VERSION ""

NS_ :

BS_:

BU_: Turbocharger OnBoardDataLogger OffBoardDiagnosticTool2 OffBoardDiagnosticTool1 FileServer ParkingBrakeController SeatControl2 FanDriveController SteeringColumnUnit CommunicationUnitRadio CommunicationUnitSatellite CommunicationUnitCellular PropulsionBatteryCharger ChassisController2 ChassisController1 EngineValveControl AuxiliaryHeater2 AuxiliaryHeater1 ClutchUnit RampControl InformationSystem1 SuspensionSystemController2 OilSensor VehicleDynamicStability ExhaustEmissionController TransmissionDisplay2 TransmissionDisplay1 ClimateControl2 WaterPumpController RearAxleSteeringController LightingOperatorControl SeatController1 IgnitionController2 IgnitionController1 TirePressureController CabController2 CabController1 PneumaticSystemController SuspensionSystemController1 HydraulicPumpController EnduranceBrakingSystem RetarderExhaustEngine2 OnBoardDiagnosticUnit HeadwayController RetarderExhaustEngine1 CabDisplay1 ManagementComputer VirtualTerminal OffVehicleGateway PowerTakeOffFront HitchControl AuxiliaryValveControl BodyController TractorTrailerBridge1 StarterSystem ElectricalSystem VehicleSecurity VehicleNavigation AerodynamicControl ElectricalChargingSystem ClimateControl1 TripRecorder InstrumentCluster SuspensionDriveAxle2 SuspensionDriveAxle1 SuspensionSteerAxle SteeringController FuelSystem CruiseControl RetarderDriveline RetarderEngine BrakesDriveAxle2 BrakesDriveAxle1 BrakesSystemController BrakesSteerAxle AxleDrive2 AxleDrive1 AxleSteering PowerTakeOff ShiftConsoleSecondary ShiftConsolePrimary Transmission2 Transmission1 Engine2 Engine1

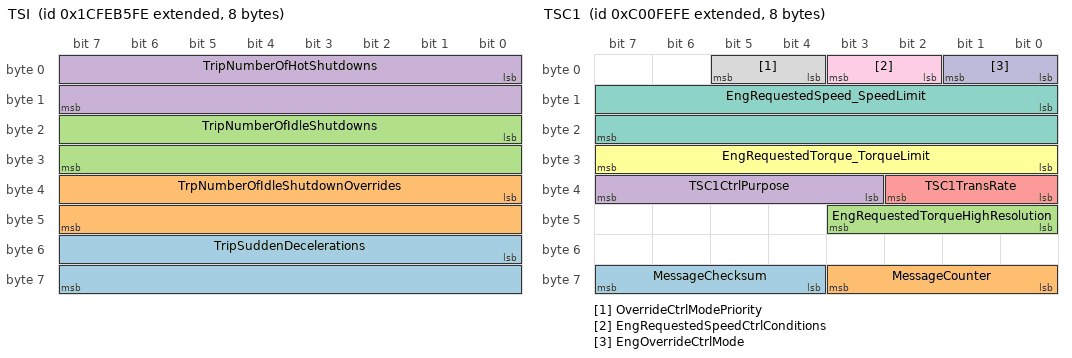
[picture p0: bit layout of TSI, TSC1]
BO_ 2633938430 TSI: 8 Vector__XXX
 SG_ TripSuddenDecelerations : 48|16@1+ (1,0) [0|64255] "counts" Vector__XXX
 SG_ TrpNumberOfIdleShutdownOverrides : 32|16@1+ (1,0) [0|64255] "counts" Vector__XXX
 SG_ TripNumberOfIdleShutdowns : 16|16@1+ (1,0) [0|64255] "counts" Vector__XXX
 SG_ TripNumberOfHotShutdowns : 0|16@1+ (1,0) [0|64255] "counts" Vector__XXX

BO_ 2348875518 TSC1: 8 Vector__XXX
 SG_ MessageChecksum : 60|4@1+ (1,0) [0|15] "" Vector__XXX
 SG_ MessageCounter : 56|4@1+ (1,0) [0|15] "" Vector__XXX
 SG_ EngRequestedTorqueHighResolution : 40|4@1+ (1,0) [0|0.875] "%" Vector__XXX
 SG_ TSC1CtrlPurpose : 35|5@1+ (1,0) [0|31] "" Vector__XXX
 SG_ TSC1TransRate : 32|3@1+ (1,0) [0|7] "" Vector__XXX
 SG_ EngRequestedTorque_TorqueLimit : 24|8@1+ (1,-125) [-125|125] "%" Vector__XXX
 SG_ EngRequestedSpeed_SpeedLimit : 8|16@1+ (1,0) [0|8031.875] "rpm" Vector__XXX
 SG_ OverrideCtrlModePriority : 4|2@1+ (1,0) [0|3] "" Vector__XXX
 SG_ EngRequestedSpeedCtrlConditions : 2|2@1+ (1,0) [0|3] "" Vector__XXX
 SG_ EngOverrideCtrlMode : 0|2@1+ (1,0) [0|3] "" Vector__XXX

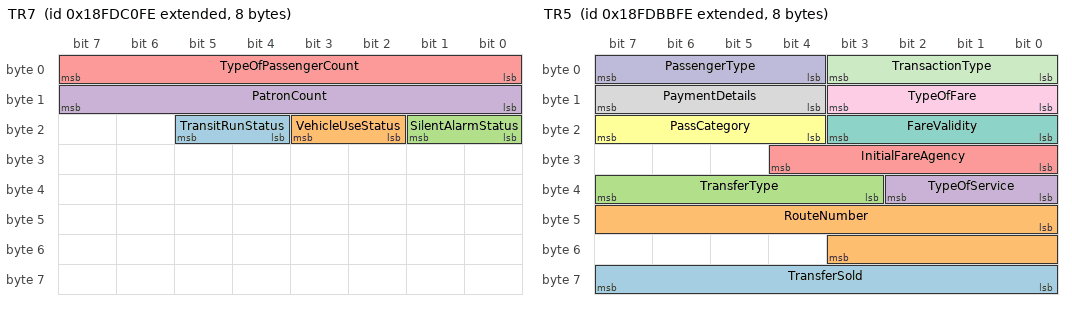
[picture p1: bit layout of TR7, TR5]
BO_ 2566766846 TR7: 8 Vector__XXX
 SG_ TransitRunStatus : 20|2@1+ (1,0) [0|3] "" Vector__XXX
 SG_ VehicleUseStatus : 18|2@1+ (1,0) [0|3] "" Vector__XXX
 SG_ SilentAlarmStatus : 16|2@1+ (1,0) [0|3] "" Vector__XXX
 SG_ PatronCount : 8|8@1+ (1,0) [0|250] "" Vector__XXX
 SG_ TypeOfPassengerCount : 0|8@1+ (1.02,0) [0|255] "" Vector__XXX

BO_ 2566765310 TR6: 8 Vector__XXX
 SG_ FareboxAlarmIdentifier : 8|7@1+ (1,0) [0|127] "" Vector__XXX
 SG_ FareboxEmergencyStatus : 0|2@1+ (1,0) [0|3] "" Vector__XXX

BO_ 2566765566 TR5: 8 Vector__XXX
 SG_ TransferSold : 56|8@1+ (1.02,0) [0|255] "" Vector__XXX
 SG_ RouteNumber : 40|12@1+ (1,0) [0|4095] "" Vector__XXX
 SG_ TransferType : 35|5@1+ (1,0) [0|31] "" Vector__XXX
 SG_ TypeOfService : 32|3@1+ (1,0) [0|7] "" Vector__XXX
 SG_ InitialFareAgency : 24|5@1+ (1,0) [0|31] "" Vector__XXX
 SG_ PassCategory : 20|4@1+ (1,0) [0|15] "" Vector__XXX
 SG_ FareValidity : 16|4@1+ (1,0) [0|15] "" Vector__XXX
 SG_ PaymentDetails : 12|4@1+ (1,0) [0|15] "" Vector__XXX
 SG_ TypeOfFare : 8|4@1+ (1,0) [0|15] "" Vector__XXX
 SG_ PassengerType : 4|4@1+ (1,0) [0|15] "" Vector__XXX
 SG_ TransactionType : 0|4@1+ (1,0) [0|15] "" Vector__XXX

BO_ 2566765822 TR4: 15 Vector__XXX
 SG_ DriversFareboxSecurityCode : 104|16@1+ (1.0199206287448,0) [0|65535] "counts" Vector__XXX
 SG_ AssignedBlock : 88|16@1+ (1.0199206287448,0) [0|65535] "counts" Vector__XXX
 SG_ AssignedRun : 72|16@1+ (1.0199206287448,0) [0|65535] "counts" Vector__XXX
 SG_ AssignedRoute : 56|16@1+ (1.0199206287448,0) [0|65535] "counts" Vector__XXX
 SG_ PatternNumber : 40|16@1+ (1.0199206287448,0) [0|65535] "counts" Vector__XXX
 SG_ TripNumber : 24|16@1+ (1.0199206287448,0) [0|65535] "counts" Vector__XXX
 SG_ FarePresets : 16|8@1+ (1.02,0) [0|255] "" Vector__XXX
 SG_ TripDirection : 8|4@1+ (1,0) [0|15] "" Vector__XXX
 SG_ TripStatus : 2|3@1+ (1,0) [0|0] "" Vector__XXX
 SG_ FareboxServiceStatus : 0|2@1+ (1,0) [0|3] "" Vector__XXX

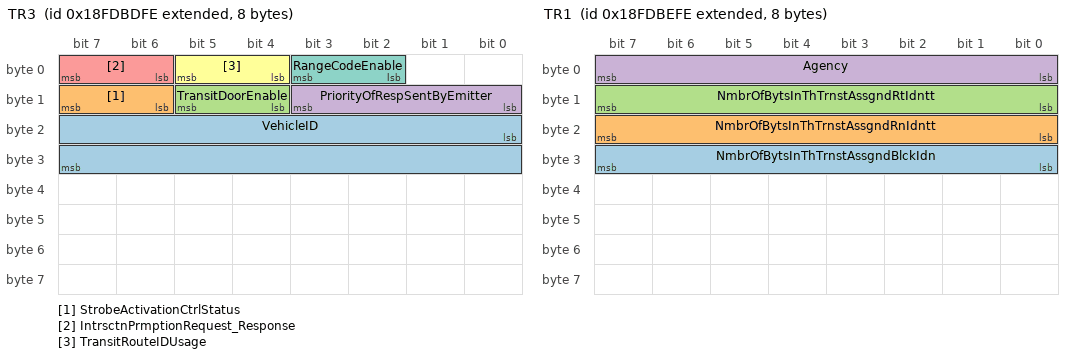
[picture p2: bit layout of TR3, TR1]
BO_ 2566766078 TR3: 8 Vector__XXX
 SG_ VehicleID : 16|16@1+ (1.0199206287448,0) [0|65535] "counts" Vector__XXX
 SG_ StrobeActivationCtrlStatus : 14|2@1+ (1,0) [0|3] "" Vector__XXX
 SG_ TransitDoorEnable : 12|2@1+ (1,0) [0|3] "" Vector__XXX
 SG_ PriorityOfRespSentByEmitter : 8|4@1+ (1,0) [0|15] "" Vector__XXX
 SG_ IntrsctnPrmptionRequest_Response : 6|2@1+ (1,0) [0|3] "" Vector__XXX
 SG_ TransitRouteIDUsage : 4|2@1+ (1,0) [0|3] "" Vector__XXX
 SG_ RangeCodeEnable : 2|2@1+ (1,0) [0|3] "" Vector__XXX

BO_ 2566766590 TR2: 8 Vector__XXX
 SG_ NmbrOfBytsInThMlpstIdntification : 0|8@1+ (1,0) [0|250] "" Vector__XXX

BO_ 2566766334 TR1: 8 Vector__XXX
 SG_ NmbrOfBytsInThTrnstAssgndBlckIdn : 24|8@1+ (1,0) [0|250] "" Vector__XXX
 SG_ NmbrOfBytsInThTrnstAssgndRnIdntt : 16|8@1+ (1,0) [0|250] "" Vector__XXX
 SG_ NmbrOfBytsInThTrnstAssgndRtIdntt : 8|8@1+ (1,0) [0|250] "" Vector__XXX
 SG_ Agency : 0|8@1+ (1.02,0) [0|255] "" Vector__XXX

BO_ 2561605374 TPRS: 8 Vector__XXX
 SG_ ReferenceTirePressSetting_33 m51 : 8|8@1+ (8,0) [0|2000] "kPa" Vector__XXX
 SG_ ReferenceTirePressSetting_32 m50 : 8|8@1+ (8,0) [0|2000] "kPa" Vector__XXX
 SG_ ReferenceTirePressSetting_31 m49 : 8|8@1+ (8,0) [0|2000] "kPa" Vector__XXX
 SG_ ReferenceTirePressSetting_30 m48 : 8|8@1+ (8,0) [0|2000] "kPa" Vector__XXX
 SG_ ReferenceTirePressSetting_23 m35 : 8|8@1+ (8,0) [0|2000] "kPa" Vector__XXX
 SG_ ReferenceTirePressSetting_22 m34 : 8|8@1+ (8,0) [0|2000] "kPa" Vector__XXX
 SG_ ReferenceTirePressSetting_21 m33 : 8|8@1+ (8,0) [0|2000] "kPa" Vector__XXX
 SG_ ReferenceTirePressSetting_20 m32 : 8|8@1+ (8,0) [0|2000] "kPa" Vector__XXX
 SG_ ReferenceTirePressSetting_13 m19 : 8|8@1+ (8,0) [0|2000] "kPa" Vector__XXX
 SG_ ReferenceTirePressSetting_12 m18 : 8|8@1+ (8,0) [0|2000] "kPa" Vector__XXX
 SG_ ReferenceTirePressSetting_11 m17 : 8|8@1+ (8,0) [0|2000] "kPa" Vector__XXX
 SG_ ReferenceTirePressSetting_10 m16 : 8|8@1+ (8,0) [0|2000] "kPa" Vector__XXX
 SG_ ReferenceTirePressSetting_01 m1 : 8|8@1+ (8,0) [0|2000] "kPa" Vector__XXX
 SG_ ReferenceTirePressSetting_00 m0 : 8|8@1+ (8,0) [0|2000] "kPa" Vector__XXX
 SG_ TireLocation M : 0|8@1+ (1,0) [0|255] "" Vector__XXX

BO_ 2566765054 TPRI: 8 Vector__XXX
 SG_ ReferenceTirePress_33 m51 : 8|8@1+ (8,0) [0|2000] "kPa" Vector__XXX
 SG_ ReferenceTirePress_32 m50 : 8|8@1+ (8,0) [0|2000] "kPa" Vector__XXX
 SG_ ReferenceTirePress_31 m49 : 8|8@1+ (8,0) [0|2000] "kPa" Vector__XXX
 SG_ ReferenceTirePress_30 m48 : 8|8@1+ (8,0) [0|2000] "kPa" Vector__XXX
 SG_ ReferenceTirePress_23 m35 : 8|8@1+ (8,0) [0|2000] "kPa" Vector__XXX
 SG_ ReferenceTirePress_22 m34 : 8|8@1+ (8,0) [0|2000] "kPa" Vector__XXX
 SG_ ReferenceTirePress_21 m33 : 8|8@1+ (8,0) [0|2000] "kPa" Vector__XXX
 SG_ ReferenceTirePress_20 m32 : 8|8@1+ (8,0) [0|2000] "kPa" Vector__XXX
 SG_ ReferenceTirePress_13 m19 : 8|8@1+ (8,0) [0|2000] "kPa" Vector__XXX
 SG_ ReferenceTirePress_12 m18 : 8|8@1+ (8,0) [0|2000] "kPa" Vector__XXX
 SG_ ReferenceTirePress_11 m17 : 8|8@1+ (8,0) [0|2000] "kPa" Vector__XXX
 SG_ ReferenceTirePress_10 m16 : 8|8@1+ (8,0) [0|2000] "kPa" Vector__XXX
 SG_ ReferenceTirePress_01 m1 : 8|8@1+ (8,0) [0|2000] "kPa" Vector__XXX
 SG_ ReferenceTirePress_00 m0 : 8|8@1+ (8,0) [0|2000] "kPa" Vector__XXX
 SG_ TireLocation M : 0|8@1+ (1,0) [0|255] "" Vector__XXX

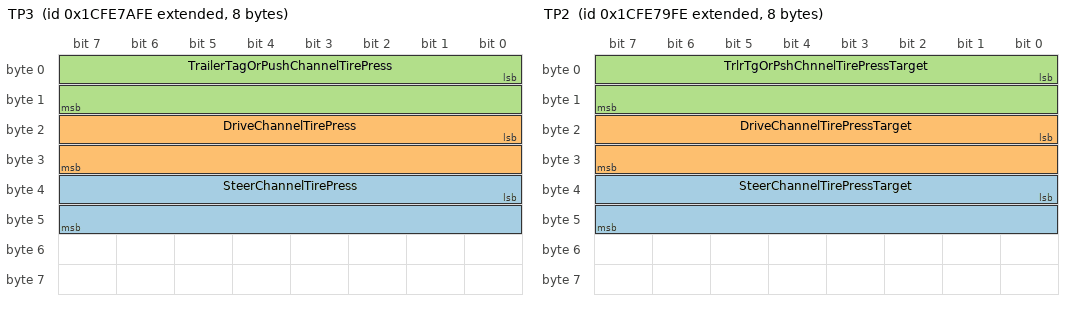
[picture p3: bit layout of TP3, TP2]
BO_ 2633923326 TP3: 8 Vector__XXX
 SG_ SteerChannelTirePress : 32|16@1+ (0.5,0) [0|32127.5] "kPa" Vector__XXX
 SG_ DriveChannelTirePress : 16|16@1+ (0.5,0) [0|32127.5] "kPa" Vector__XXX
 SG_ TrailerTagOrPushChannelTirePress : 0|16@1+ (0.5,0) [0|32127.5] "kPa" Vector__XXX

BO_ 2633923070 TP2: 8 Vector__XXX
 SG_ SteerChannelTirePressTarget : 32|16@1+ (0.5,0) [0|32127.5] "kPa" Vector__XXX
 SG_ DriveChannelTirePressTarget : 16|16@1+ (0.5,0) [0|32127.5] "kPa" Vector__XXX
 SG_ TrlrTgOrPshChnnelTirePressTarget : 0|16@1+ (0.5,0) [0|32127.5] "kPa" Vector__XXX

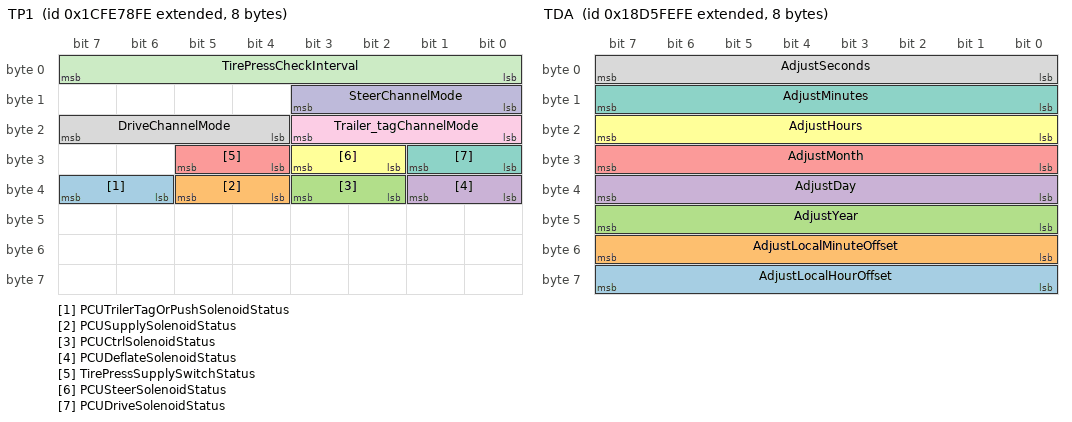
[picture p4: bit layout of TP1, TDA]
BO_ 2633922814 TP1: 8 Vector__XXX
 SG_ PCUTrilerTagOrPushSolenoidStatus : 38|2@1+ (1,0) [0|3] "" Vector__XXX
 SG_ PCUSupplySolenoidStatus : 36|2@1+ (1,0) [0|3] "" Vector__XXX
 SG_ PCUCtrlSolenoidStatus : 34|2@1+ (1,0) [0|3] "" Vector__XXX
 SG_ PCUDeflateSolenoidStatus : 32|2@1+ (1,0) [0|3] "" Vector__XXX
 SG_ TirePressSupplySwitchStatus : 28|2@1+ (1,0) [0|3] "" Vector__XXX
 SG_ PCUSteerSolenoidStatus : 26|2@1+ (1,0) [0|3] "" Vector__XXX
 SG_ PCUDriveSolenoidStatus : 24|2@1+ (1,0) [0|3] "" Vector__XXX
 SG_ DriveChannelMode : 20|4@1+ (1,0) [0|15] "" Vector__XXX
 SG_ Trailer_tagChannelMode : 16|4@1+ (1,0) [0|15] "" Vector__XXX
 SG_ SteerChannelMode : 8|4@1+ (1,0) [0|15] "" Vector__XXX
 SG_ TirePressCheckInterval : 0|8@1+ (1,0) [0|250] "mins" Vector__XXX

BO_ 2566845694 TIRE: 8 Vector__XXX
 SG_ TirePressThresholdDetection_13 m19 : 61|3@1+ (1,0) [0|7] "" Vector__XXX
 SG_ TirePressThresholdDetection_12 m18 : 61|3@1+ (1,0) [0|7] "" Vector__XXX
 SG_ TirePressThresholdDetection_11 m17 : 61|3@1+ (1,0) [0|7] "" Vector__XXX
 SG_ TirePressThresholdDetection_10 m16 : 61|3@1+ (1,0) [0|7] "" Vector__XXX
 SG_ TirePressThresholdDetection_01 m1 : 61|3@1+ (1,0) [0|7] "" Vector__XXX
 SG_ TirePress_33 m51 : 8|8@1+ (4,0) [0|1000] "kPa" Vector__XXX
 SG_ TirePress_32 m50 : 8|8@1+ (4,0) [0|1000] "kPa" Vector__XXX
 SG_ TirePress_31 m49 : 8|8@1+ (4,0) [0|1000] "kPa" Vector__XXX
 SG_ TirePress_30 m48 : 8|8@1+ (4,0) [0|1000] "kPa" Vector__XXX
 SG_ TirePress_23 m35 : 8|8@1+ (4,0) [0|1000] "kPa" Vector__XXX
 SG_ TirePress_22 m34 : 8|8@1+ (4,0) [0|1000] "kPa" Vector__XXX
 SG_ TirePress_21 m33 : 8|8@1+ (4,0) [0|1000] "kPa" Vector__XXX
 SG_ TirePress_20 m32 : 8|8@1+ (4,0) [0|1000] "kPa" Vector__XXX
 SG_ TirePress_13 m19 : 8|8@1+ (4,0) [0|1000] "kPa" Vector__XXX
 SG_ TirePress_12 m18 : 8|8@1+ (4,0) [0|1000] "kPa" Vector__XXX
 SG_ TirePress_11 m17 : 8|8@1+ (4,0) [0|1000] "kPa" Vector__XXX
 SG_ TirePress_10 m16 : 8|8@1+ (4,0) [0|1000] "kPa" Vector__XXX
 SG_ TireAirLeakageRate_33 m51 : 40|16@1+ (0.1,0) [0|6425.5] "Pa/s" Vector__XXX
 SG_ TireAirLeakageRate_32 m50 : 40|16@1+ (0.1,0) [0|6425.5] "Pa/s" Vector__XXX
 SG_ TireAirLeakageRate_31 m49 : 40|16@1+ (0.1,0) [0|6425.5] "Pa/s" Vector__XXX
 SG_ TireAirLeakageRate_30 m48 : 40|16@1+ (0.1,0) [0|6425.5] "Pa/s" Vector__XXX
 SG_ TireAirLeakageRate_23 m35 : 40|16@1+ (0.1,0) [0|6425.5] "Pa/s" Vector__XXX
 SG_ TireAirLeakageRate_22 m34 : 40|16@1+ (0.1,0) [0|6425.5] "Pa/s" Vector__XXX
 SG_ TireAirLeakageRate_21 m33 : 40|16@1+ (0.1,0) [0|6425.5] "Pa/s" Vector__XXX
 SG_ TireAirLeakageRate_20 m32 : 40|16@1+ (0.1,0) [0|6425.5] "Pa/s" Vector__XXX
 SG_ TireAirLeakageRate_13 m19 : 40|16@1+ (0.1,0) [0|6425.5] "Pa/s" Vector__XXX
 SG_ TireAirLeakageRate_12 m18 : 40|16@1+ (0.1,0) [0|6425.5] "Pa/s" Vector__XXX
 SG_ TireAirLeakageRate_11 m17 : 40|16@1+ (0.1,0) [0|6425.5] "Pa/s" Vector__XXX
 SG_ TireAirLeakageRate_10 m16 : 40|16@1+ (0.1,0) [0|6425.5] "Pa/s" Vector__XXX
 SG_ TireAirLeakageRate_01 m1 : 40|16@1+ (0.1,0) [0|6425.5] "Pa/s" Vector__XXX
 SG_ TireAirLeakageRate_00 m0 : 40|16@1+ (0.1,0) [0|6425.5] "Pa/s" Vector__XXX
 SG_ CTIWheelSensorStatus_33 m51 : 32|2@1+ (1,0) [0|3] "" Vector__XXX
 SG_ CTIWheelSensorStatus_32 m50 : 32|2@1+ (1,0) [0|3] "" Vector__XXX
 SG_ CTIWheelSensorStatus_31 m49 : 32|2@1+ (1,0) [0|3] "" Vector__XXX
 SG_ CTIWheelSensorStatus_30 m48 : 32|2@1+ (1,0) [0|3] "" Vector__XXX
 SG_ CTIWheelSensorStatus_23 m35 : 32|2@1+ (1,0) [0|3] "" Vector__XXX
 SG_ CTIWheelSensorStatus_22 m34 : 32|2@1+ (1,0) [0|3] "" Vector__XXX
 SG_ CTIWheelSensorStatus_21 m33 : 32|2@1+ (1,0) [0|3] "" Vector__XXX
 SG_ CTIWheelSensorStatus_20 m32 : 32|2@1+ (1,0) [0|3] "" Vector__XXX
 SG_ CTIWheelSensorStatus_13 m19 : 32|2@1+ (1,0) [0|3] "" Vector__XXX
 SG_ CTIWheelSensorStatus_12 m18 : 32|2@1+ (1,0) [0|3] "" Vector__XXX
 SG_ CTIWheelSensorStatus_11 m17 : 32|2@1+ (1,0) [0|3] "" Vector__XXX
 SG_ CTIWheelSensorStatus_10 m16 : 32|2@1+ (1,0) [0|3] "" Vector__XXX
 SG_ CTIWheelSensorStatus_01 m1 : 32|2@1+ (1,0) [0|3] "" Vector__XXX
 SG_ CTIWheelEndElectricalFault_33 m51 : 36|2@1+ (1,0) [0|3] "" Vector__XXX
 SG_ CTIWheelEndElectricalFault_32 m50 : 36|2@1+ (1,0) [0|3] "" Vector__XXX
 SG_ CTIWheelEndElectricalFault_31 m49 : 36|2@1+ (1,0) [0|3] "" Vector__XXX
 SG_ CTIWheelEndElectricalFault_30 m48 : 36|2@1+ (1,0) [0|3] "" Vector__XXX
 SG_ CTIWheelEndElectricalFault_23 m35 : 36|2@1+ (1,0) [0|3] "" Vector__XXX
 SG_ CTIWheelEndElectricalFault_22 m34 : 36|2@1+ (1,0) [0|3] "" Vector__XXX
 SG_ CTIWheelEndElectricalFault_21 m33 : 36|2@1+ (1,0) [0|3] "" Vector__XXX
 SG_ CTIWheelEndElectricalFault_20 m32 : 36|2@1+ (1,0) [0|3] "" Vector__XXX
 SG_ CTIWheelEndElectricalFault_13 m19 : 36|2@1+ (1,0) [0|3] "" Vector__XXX
 SG_ CTIWheelEndElectricalFault_12 m18 : 36|2@1+ (1,0) [0|3] "" Vector__XXX
 SG_ CTIWheelEndElectricalFault_11 m17 : 36|2@1+ (1,0) [0|3] "" Vector__XXX
 SG_ CTIWheelEndElectricalFault_10 m16 : 36|2@1+ (1,0) [0|3] "" Vector__XXX
 SG_ CTIWheelEndElectricalFault_01 m1 : 36|2@1+ (1,0) [0|3] "" Vector__XXX
 SG_ CTITireStatus_33 m51 : 34|2@1+ (1,0) [0|3] "" Vector__XXX
 SG_ CTITireStatus_32 m50 : 34|2@1+ (1,0) [0|3] "" Vector__XXX
 SG_ CTITireStatus_31 m49 : 34|2@1+ (1,0) [0|3] "" Vector__XXX
 SG_ CTITireStatus_30 m48 : 34|2@1+ (1,0) [0|3] "" Vector__XXX
 SG_ CTITireStatus_23 m35 : 34|2@1+ (1,0) [0|3] "" Vector__XXX
 SG_ CTITireStatus_22 m34 : 34|2@1+ (1,0) [0|3] "" Vector__XXX
 SG_ CTITireStatus_21 m33 : 34|2@1+ (1,0) [0|3] "" Vector__XXX
 SG_ CTITireStatus_20 m32 : 34|2@1+ (1,0) [0|3] "" Vector__XXX
 SG_ CTITireStatus_13 m19 : 34|2@1+ (1,0) [0|3] "" Vector__XXX
 SG_ CTITireStatus_12 m18 : 34|2@1+ (1,0) [0|3] "" Vector__XXX
 SG_ CTITireStatus_11 m17 : 34|2@1+ (1,0) [0|3] "" Vector__XXX
 SG_ CTITireStatus_10 m16 : 34|2@1+ (1,0) [0|3] "" Vector__XXX
 SG_ CTITireStatus_01 m1 : 34|2@1+ (1,0) [0|3] "" Vector__XXX
 SG_ TireTemp_11 m17 : 16|16@1+ (0.03125,-273) [-273|1735] "°C" Vector__XXX
 SG_ TireTemp_33 m51 : 16|16@1+ (0.03125,-273) [-273|1735] "°C" Vector__XXX
 SG_ TireTemp_32 m50 : 16|16@1+ (0.03125,-273) [-273|1735] "°C" Vector__XXX
 SG_ TireTemp_31 m49 : 16|16@1+ (0.03125,-273) [-273|1735] "°C" Vector__XXX
 SG_ TireTemp_30 m48 : 16|16@1+ (0.03125,-273) [-273|1735] "°C" Vector__XXX
 SG_ TireTemp_23 m35 : 16|16@1+ (0.03125,-273) [-273|1735] "°C" Vector__XXX
 SG_ TireTemp_22 m34 : 16|16@1+ (0.03125,-273) [-273|1735] "°C" Vector__XXX
 SG_ TireTemp_21 m33 : 16|16@1+ (0.03125,-273) [-273|1735] "°C" Vector__XXX
 SG_ TireTemp_20 m32 : 16|16@1+ (0.03125,-273) [-273|1735] "°C" Vector__XXX
 SG_ TireTemp_13 m19 : 16|16@1+ (0.03125,-273) [-273|1735] "°C" Vector__XXX
 SG_ TireTemp_12 m18 : 16|16@1+ (0.03125,-273) [-273|1735] "°C" Vector__XXX
 SG_ TireTemp_10 m16 : 16|16@1+ (0.03125,-273) [-273|1735] "°C" Vector__XXX
 SG_ TireTemp_01 m1 : 16|16@1+ (0.03125,-273) [-273|1735] "°C" Vector__XXX
 SG_ TireTemp_00 m0 : 16|16@1+ (0.03125,-273) [-273|1735] "°C" Vector__XXX
 SG_ TirePressThresholdDetection_33 m51 : 61|3@1+ (1,0) [0|7] "" Vector__XXX
 SG_ TirePressThresholdDetection_32 m50 : 61|3@1+ (1,0) [0|7] "" Vector__XXX
 SG_ TirePressThresholdDetection_31 m49 : 61|3@1+ (1,0) [0|7] "" Vector__XXX
 SG_ TirePressThresholdDetection_30 m48 : 61|3@1+ (1,0) [0|7] "" Vector__XXX
 SG_ TirePressThresholdDetection_23 m35 : 61|3@1+ (1,0) [0|7] "" Vector__XXX
 SG_ TirePressThresholdDetection_22 m34 : 61|3@1+ (1,0) [0|7] "" Vector__XXX
 SG_ TirePressThresholdDetection_21 m33 : 61|3@1+ (1,0) [0|7] "" Vector__XXX
 SG_ TirePressThresholdDetection_20 m32 : 61|3@1+ (1,0) [0|7] "" Vector__XXX
 SG_ TirePressThresholdDetection_00 m0 : 61|3@1+ (1,0) [0|7] "" Vector__XXX
 SG_ TirePress_01 m1 : 8|8@1+ (4,0) [0|1000] "kPa" Vector__XXX
 SG_ TirePress_00 m0 : 8|8@1+ (4,0) [0|1000] "kPa" Vector__XXX
 SG_ CTIWheelSensorStatus_00 m0 : 32|2@1+ (1,0) [0|3] "" Vector__XXX
 SG_ CTIWheelEndElectricalFault_00 m0 : 36|2@1+ (1,0) [0|3] "" Vector__XXX
 SG_ CTITireStatus_00 m0 : 34|2@1+ (1,0) [0|3] "" Vector__XXX
 SG_ TireLocation M : 0|8@1+ (1,0) [0|255] "" Vector__XXX

BO_ 2633939966 TFI: 16 Vector__XXX
 SG_ TripFanOnTimeDueToAManualSwitch : 64|32@1+ (0.05,0) [0|210554060.75] "hr" Vector__XXX
 SG_ TripFanOnTime : 0|32@1+ (0.05,0) [0|210554060.75] "hr" Vector__XXX
 SG_ TripFanOnTimeDueToTheA_CSystem : 96|32@1+ (0.05,0) [0|210554060.75] "hr" Vector__XXX
 SG_ TripFanOnTimeDueToTheEngSystem : 32|32@1+ (0.05,0) [0|210554060.75] "hr" Vector__XXX

BO_ 2633939710 TDI: 12 Vector__XXX
 SG_ TripDistanceInTopGear : 64|32@1+ (0.12500000000594,0) [0|526385151.9] "km" Vector__XXX
 SG_ TripGearDownDistance : 32|32@1+ (0.12500000000594,0) [0|526385151.9] "km" Vector__XXX
 SG_ TripDistanceOnVSL : 0|32@1+ (0.12500000000594,0) [0|526385151.9] "km" Vector__XXX

BO_ 2564161278 TDA: 8 Vector__XXX
 SG_ AdjustLocalHourOffset : 56|8@1+ (1,-125) [-125|125] "hr" Vector__XXX
 SG_ AdjustLocalMinuteOffset : 48|8@1+ (1,-125) [-125|125] "mins" Vector__XXX
 SG_ AdjustYear : 40|8@1+ (1,1985) [1985|2235] "years" Vector__XXX
 SG_ AdjustDay : 32|8@1+ (0.25,0) [0|62.5] "days" Vector__XXX
 SG_ AdjustMonth : 24|8@1+ (1,0) [0|250] "months" Vector__XXX
 SG_ AdjustHours : 16|8@1+ (1,0) [0|250] "hr" Vector__XXX
 SG_ AdjustMinutes : 8|8@1+ (1,0) [0|250] "mins" Vector__XXX
 SG_ AdjustSeconds : 0|8@1+ (0.25,0) [0|62.5] "s" Vector__XXX

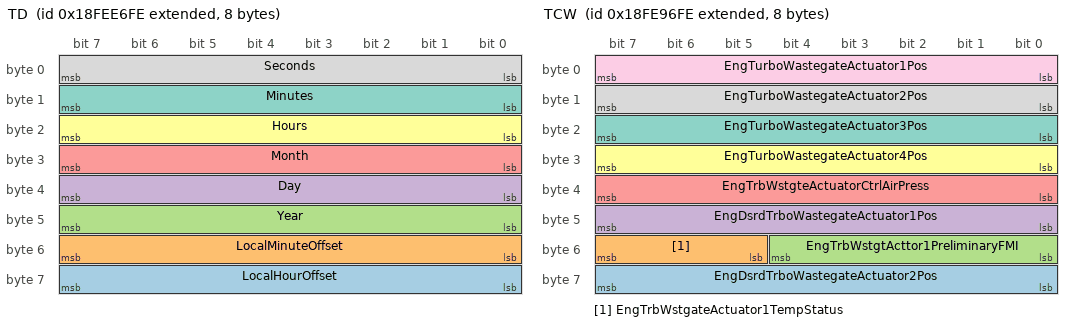
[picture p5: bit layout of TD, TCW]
BO_ 2566842110 TD: 8 Vector__XXX
 SG_ LocalHourOffset : 56|8@1+ (1,-125) [-125|125] "hr" Vector__XXX
 SG_ LocalMinuteOffset : 48|8@1+ (1,-125) [-125|125] "mins" Vector__XXX
 SG_ Year : 40|8@1+ (1,1985) [1985|2235] "years" Vector__XXX
 SG_ Day : 32|8@1+ (0.25,0) [0|62.5] "days" Vector__XXX
 SG_ Month : 24|8@1+ (1,0) [0|250] "months" Vector__XXX
 SG_ Hours : 16|8@1+ (1,0) [0|250] "hr" Vector__XXX
 SG_ Minutes : 8|8@1+ (1,0) [0|250] "mins" Vector__XXX
 SG_ Seconds : 0|8@1+ (0.25,0) [0|62.5] "s" Vector__XXX

BO_ 2566821630 TCW: 8 Vector__XXX
 SG_ EngDsrdTrboWastegateActuator2Pos : 56|8@1+ (1,0) [0|100] "%" Vector__XXX
 SG_ EngTrbWstgateActuator1TempStatus : 53|3@1+ (1,0) [0|7] "" Vector__XXX
 SG_ EngTrbWstgtActtor1PreliminaryFMI : 48|5@1+ (1,0) [0|31] "" Vector__XXX
 SG_ EngDsrdTrboWastegateActuator1Pos : 40|8@1+ (1,0) [0|100] "%" Vector__XXX
 SG_ EngTrbWstgteActuatorCtrlAirPress : 32|8@1+ (4,0) [0|1000] "kPa" Vector__XXX
 SG_ EngTurboWastegateActuator4Pos : 24|8@1+ (0.4,0) [0|100] "%" Vector__XXX
 SG_ EngTurboWastegateActuator3Pos : 16|8@1+ (0.4,0) [0|100] "%" Vector__XXX
 SG_ EngTurboWastegateActuator2Pos : 8|8@1+ (0.4,0) [0|100] "%" Vector__XXX
 SG_ EngTurboWastegateActuator1Pos : 0|8@1+ (0.4,0) [0|100] "%" Vector__XXX

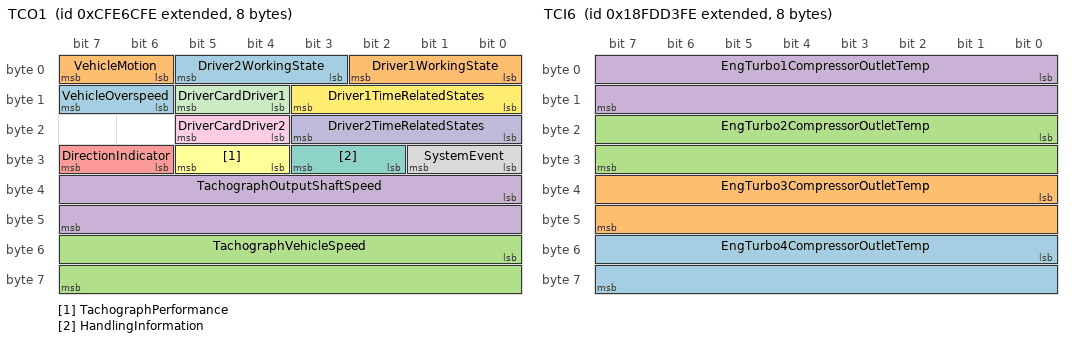
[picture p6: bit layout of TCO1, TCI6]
BO_ 2365484286 TCO1: 8 Vector__XXX
 SG_ VehicleOverspeed : 14|2@1+ (1,0) [0|3] "" Vector__XXX
 SG_ VehicleMotion : 6|2@1+ (1,0) [0|3] "" Vector__XXX
 SG_ TachographVehicleSpeed : 48|16@1+ (0.0039062485409696,0) [0|250.996] "km/h" Vector__XXX
 SG_ TachographOutputShaftSpeed : 32|16@1+ (0.125,0) [0|8031.875] "rpm" Vector__XXX
 SG_ DirectionIndicator : 30|2@1+ (1,0) [0|3] "" Vector__XXX
 SG_ TachographPerformance : 28|2@1+ (1,0) [0|3] "" Vector__XXX
 SG_ HandlingInformation : 26|2@1+ (1,0) [0|3] "" Vector__XXX
 SG_ SystemEvent : 24|2@1+ (1,0) [0|3] "" Vector__XXX
 SG_ DriverCardDriver2 : 20|2@1+ (1,0) [0|3] "" Vector__XXX
 SG_ Driver2TimeRelatedStates : 16|4@1+ (1,0) [0|15] "" Vector__XXX
 SG_ DriverCardDriver1 : 12|2@1+ (1,0) [0|3] "" Vector__XXX
 SG_ Driver1TimeRelatedStates : 8|4@1+ (1,0) [0|15] "" Vector__XXX
 SG_ Driver2WorkingState : 3|3@1+ (1,0) [0|7] "" Vector__XXX
 SG_ Driver1WorkingState : 0|3@1+ (1,0) [0|7] "" Vector__XXX

BO_ 2566771710 TCI6: 8 Vector__XXX
 SG_ EngTurbo4CompressorOutletTemp : 48|16@1+ (0.03125,-273) [-273|1734.96875] "deg C" Vector__XXX
 SG_ EngTurbo3CompressorOutletTemp : 32|16@1+ (0.03125,-273) [-273|1734.96875] "deg C" Vector__XXX
 SG_ EngTurbo2CompressorOutletTemp : 16|16@1+ (0.03125,-273) [-273|1734.96875] "deg C" Vector__XXX
 SG_ EngTurbo1CompressorOutletTemp : 0|16@1+ (0.03125,-273) [-273|1734.96875] "deg C" Vector__XXX

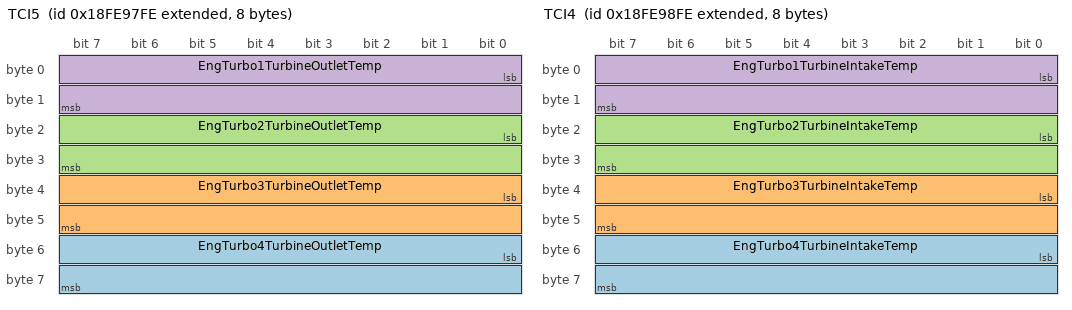
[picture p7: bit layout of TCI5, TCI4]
BO_ 2566821886 TCI5: 8 Vector__XXX
 SG_ EngTurbo4TurbineOutletTemp : 48|16@1+ (0.03125,-273) [-273|1734.96875] "deg C" Vector__XXX
 SG_ EngTurbo3TurbineOutletTemp : 32|16@1+ (0.03125,-273) [-273|1734.96875] "deg C" Vector__XXX
 SG_ EngTurbo2TurbineOutletTemp : 16|16@1+ (0.03125,-273) [-273|1734.96875] "deg C" Vector__XXX
 SG_ EngTurbo1TurbineOutletTemp : 0|16@1+ (0.03125,-273) [-273|1734.96875] "deg C" Vector__XXX

BO_ 2566822142 TCI4: 8 Vector__XXX
 SG_ EngTurbo4TurbineIntakeTemp : 48|16@1+ (0.03125,-273) [-273|1734.96875] "deg C" Vector__XXX
 SG_ EngTurbo3TurbineIntakeTemp : 32|16@1+ (0.03125,-273) [-273|1734.96875] "deg C" Vector__XXX
 SG_ EngTurbo2TurbineIntakeTemp : 16|16@1+ (0.03125,-273) [-273|1734.96875] "deg C" Vector__XXX
 SG_ EngTurbo1TurbineIntakeTemp : 0|16@1+ (0.03125,-273) [-273|1734.96875] "deg C" Vector__XXX

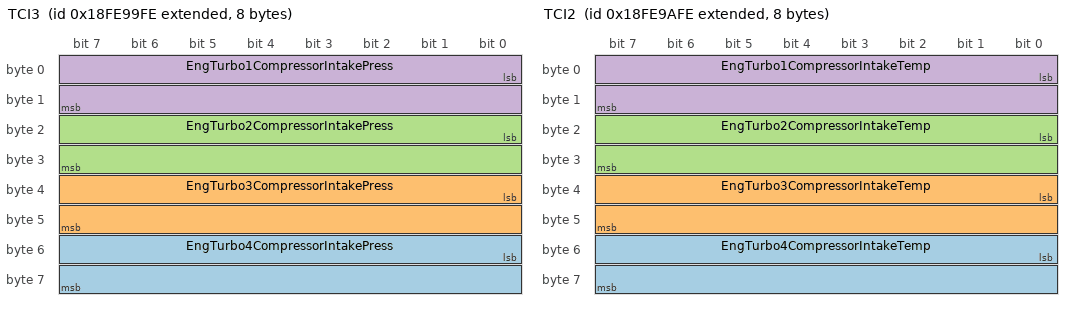
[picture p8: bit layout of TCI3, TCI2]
BO_ 2566822398 TCI3: 8 Vector__XXX
 SG_ EngTurbo4CompressorIntakePress : 48|16@1+ (0.0078124659559567,-250) [-250|251.99] "kPa" Vector__XXX
 SG_ EngTurbo3CompressorIntakePress : 32|16@1+ (0.0078124659559567,-250) [-250|251.99] "kPa" Vector__XXX
 SG_ EngTurbo2CompressorIntakePress : 16|16@1+ (0.0078124659559567,-250) [-250|251.99] "kPa" Vector__XXX
 SG_ EngTurbo1CompressorIntakePress : 0|16@1+ (0.0078124659559567,-250) [-250|251.99] "kPa" Vector__XXX

BO_ 2566822654 TCI2: 8 Vector__XXX
 SG_ EngTurbo4CompressorIntakeTemp : 48|16@1+ (0.03125,-273) [-273|1734.96875] "deg C" Vector__XXX
 SG_ EngTurbo3CompressorIntakeTemp : 32|16@1+ (0.03125,-273) [-273|1734.96875] "deg C" Vector__XXX
 SG_ EngTurbo2CompressorIntakeTemp : 16|16@1+ (0.03125,-273) [-273|1734.96875] "deg C" Vector__XXX
 SG_ EngTurbo1CompressorIntakeTemp : 0|16@1+ (0.03125,-273) [-273|1734.96875] "deg C" Vector__XXX

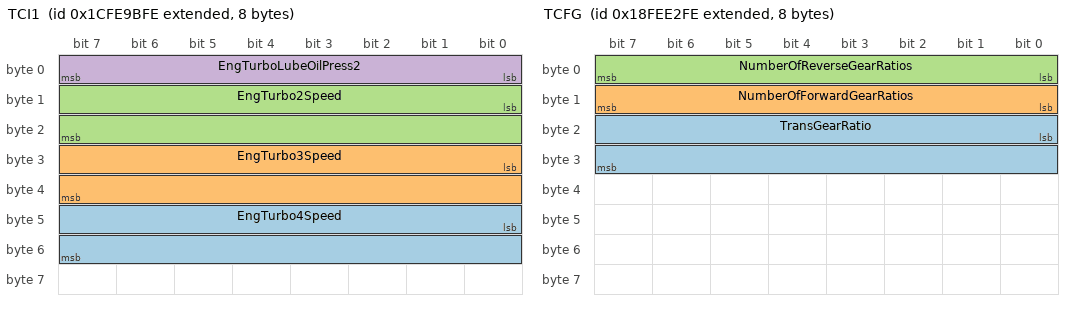
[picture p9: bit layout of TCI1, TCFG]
BO_ 2633931774 TCI1: 8 Vector__XXX
 SG_ EngTurbo4Speed : 40|16@1+ (4,0) [0|257020] "rpm" Vector__XXX
 SG_ EngTurbo3Speed : 24|16@1+ (4,0) [0|257020] "rpm" Vector__XXX
 SG_ EngTurbo2Speed : 8|16@1+ (4,0) [0|257020] "rpm" Vector__XXX
 SG_ EngTurboLubeOilPress2 : 0|8@1+ (4,0) [0|1000] "kPa" Vector__XXX

BO_ 2566802430 TCFG2: 8 Vector__XXX
 SG_ TransTorqueLimit : 0|16@1+ (1,0) [0|64255] "Nm" Vector__XXX

BO_ 2566841086 TCFG: 8 Vector__XXX
 SG_ TransGearRatio : 16|16@1+ (0.001,0) [0|64.255] "" Vector__XXX
 SG_ NumberOfForwardGearRatios : 8|8@1+ (1,0) [0|250] "" Vector__XXX
 SG_ NumberOfReverseGearRatios : 0|8@1+ (1,0) [0|250] "" Vector__XXX

BO_ 2348941054 TC1: 8 Vector__XXX
 SG_ TransMode8 : 62|2@1+ (1,0) [0|3] "" Vector__XXX
 SG_ TransMode7 : 60|2@1+ (1,0) [0|3] "" Vector__XXX
 SG_ TransMode6 : 58|2@1+ (1,0) [0|3] "" Vector__XXX
 SG_ TransMode5 : 56|2@1+ (1,0) [0|3] "" Vector__XXX
 SG_ TrnsShftSlectorDisplayModeSwitch : 54|2@1+ (1,0) [0|3] "" Vector__XXX
 SG_ TransRequestedLaunchGear : 50|4@1+ (1,0) [0|15] "" Vector__XXX
 SG_ TransMode4 : 46|2@1+ (1,0) [0|3] "" Vector__XXX
 SG_ TransMode3 : 44|2@1+ (1,0) [0|3] "" Vector__XXX
 SG_ TransMode2 : 42|2@1+ (1,0) [0|3] "" Vector__XXX
 SG_ TransMode1 : 40|2@1+ (1,0) [0|3] "" Vector__XXX
 SG_ DisengageDiffLockRqCentralRear : 36|2@1+ (1,0) [0|3] "" Vector__XXX
 SG_ DisengageDiffLockRqCentralFront : 34|2@1+ (1,0) [0|3] "" Vector__XXX
 SG_ DisengageDiffLockRqCentral : 32|2@1+ (1,0) [0|3] "" Vector__XXX
 SG_ DisengageDiffLockRqRearAxle2 : 30|2@1+ (1,0) [0|3] "" Vector__XXX
 SG_ DisengageDiffLockRqRearAxle1 : 28|2@1+ (1,0) [0|3] "" Vector__XXX
 SG_ DisengageDiffLockRqFrontAxle2 : 26|2@1+ (1,0) [0|3] "" Vector__XXX
 SG_ DisengageDiffLockRqFrontAxle1 : 24|2@1+ (1,0) [0|3] "" Vector__XXX
 SG_ TransRequestedGear : 16|8@1+ (1,-125) [-125|125] "" Vector__XXX
 SG_ RequestedPercentClutchSlip : 8|8@1+ (1,0) [0|100] "%" Vector__XXX
 SG_ TransReverseGearShiftInhibitRq : 6|2@1+ (1,0) [0|3] "" Vector__XXX
 SG_ DisengageDrivelineRq : 4|2@1+ (1,0) [0|3] "" Vector__XXX
 SG_ TrnsTrqeConverterLockupDisableRq : 2|2@1+ (1,0) [0|3] "" Vector__XXX
 SG_ TransGearShiftInhibitRq : 0|2@1+ (1,0) [0|3] "" Vector__XXX

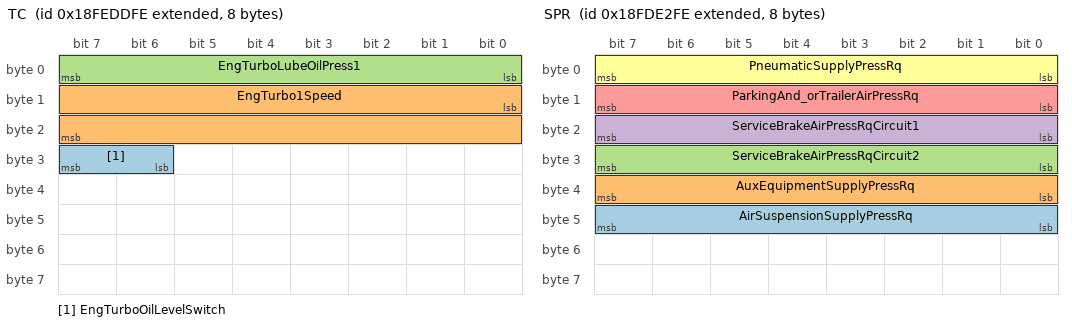
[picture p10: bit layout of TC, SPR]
BO_ 2566839806 TC: 8 Vector__XXX
 SG_ EngTurboOilLevelSwitch : 30|2@1+ (1,0) [0|3] "" Vector__XXX
 SG_ EngTurbo1Speed : 8|16@1+ (4,0) [0|257020] "rpm" Vector__XXX
 SG_ EngTurboLubeOilPress1 : 0|8@1+ (4,0) [0|1000] "kPa" Vector__XXX

BO_ 2633911806 TAVG: 8 Vector__XXX
 SG_ EngTotalAverageFuelEconomy : 16|16@1+ (0.0019531553964672,0) [0|125.5] "km/L" Vector__XXX
 SG_ EngTotalAverageFuelRate : 0|16@1+ (0.05,0) [0|3212.75] "L/h" Vector__XXX

BO_ 2566775550 SPR: 8 Vector__XXX
 SG_ AirSuspensionSupplyPressRq : 40|8@1+ (1,0) [0|2000] "kPa" Vector__XXX
 SG_ AuxEquipmentSupplyPressRq : 32|8@1+ (1,0) [0|2000] "kPa" Vector__XXX
 SG_ ServiceBrakeAirPressRqCircuit2 : 24|8@1+ (1,0) [0|2000] "kPa" Vector__XXX
 SG_ ServiceBrakeAirPressRqCircuit1 : 16|8@1+ (1,0) [0|2000] "kPa" Vector__XXX
 SG_ ParkingAnd_orTrailerAirPressRq : 8|8@1+ (1,0) [0|2000] "kPa" Vector__XXX
 SG_ PneumaticSupplyPressRq : 0|8@1+ (1,0) [0|2000] "kPa" Vector__XXX

BO_ 2566819838 SP2: 8 Vector__XXX
 SG_ EngExtlShutdownAirSupplyPress : 0|16@1+ (0.5,0) [0|32127.5] "kPa" Vector__XXX

BO_ 2566839038 SOFT: 8 Vector__XXX
 SG_ NmbrOfSftwreIdentificationFields : 0|8@1+ (1,0) [0|250] "steps" Vector__XXX
 SG_ SoftwareIdentification : 8|8@1+ (1.02,0) [0|255] "per byte" Vector__XXX

BO_ 2566841598 SHUTDN: 8 Vector__XXX
 SG_ PTOShutdownHasShutdownEng : 58|2@1+ (1,0) [0|3] "" Vector__XXX
 SG_ EngAirShutoffStatus : 56|2@1+ (1,0) [0|3] "" Vector__XXX
 SG_ EngOverspeedTest : 54|2@1+ (1,0) [0|3] "" Vector__XXX
 SG_ EngAirShutoffCmdStatus : 52|2@1+ (1,0) [0|3] "" Vector__XXX
 SG_ EngAlarmOutputCmdStatus : 50|2@1+ (1,0) [0|3] "" Vector__XXX
 SG_ EngAlarmAcknowledge : 48|2@1+ (1,0) [0|3] "" Vector__XXX
 SG_ EngProtectionSystemConfig : 46|2@1+ (1,0) [0|3] "" Vector__XXX
 SG_ EngProtectionSystemTimerState : 38|2@1+ (1,0) [0|3] "" Vector__XXX
 SG_ EngProtectionSystemTimerOverride : 36|2@1+ (1,0) [0|3] "" Vector__XXX
 SG_ EngPrtctnSystmApprachingShutdown : 34|2@1+ (1,0) [0|3] "" Vector__XXX
 SG_ EngPrtectionSystemHasShutdownEng : 32|2@1+ (1,0) [0|3] "" Vector__XXX
 SG_ EngWaitToStartLamp : 24|2@1+ (1,0) [0|3] "" Vector__XXX
 SG_ RefrigerantHighPressSwitch : 20|2@1+ (1,0) [0|3] "" Vector__XXX
 SG_ RefrigerantLowPressSwitch : 18|2@1+ (1,0) [0|3] "" Vector__XXX
 SG_ A_CHighPressFanSwitch : 16|2@1+ (1,0) [0|3] "" Vector__XXX
 SG_ EngIdleShutdownTimerFunction : 14|2@1+ (1,0) [0|3] "" Vector__XXX
 SG_ EngIdleShutdownTimerState : 6|2@1+ (1,0) [0|3] "" Vector__XXX
 SG_ EngIdleShutdownTimerOverride : 4|2@1+ (1,0) [0|3] "" Vector__XXX
 SG_ EngIdleShutdownDriverAlertMode : 2|2@1+ (1,0) [0|3] "" Vector__XXX
 SG_ EngIdleShutdownHasShutdownEng : 0|2@1+ (1,0) [0|3] "" Vector__XXX

BO_ 2633895166 WSMEM: 8 Vector__XXX
 SG_ VehicleSystem5 m5 : 49|7@1+ (1,0) [0|127] "" Vector__XXX
 SG_ VehicleSystem4 m4 : 49|7@1+ (1,0) [0|127] "" Vector__XXX
 SG_ VehicleSystem3 m3 : 49|7@1+ (1,0) [0|127] "" Vector__XXX
 SG_ VehicleSystem2 m2 : 49|7@1+ (1,0) [0|127] "" Vector__XXX
 SG_ VehicleSystem1 m1 : 49|7@1+ (1,0) [0|127] "" Vector__XXX
 SG_ ArbitraryAddressCapable : 63|1@1+ (1,0) [0|1] "" Vector__XXX
 SG_ IndustryGroup M : 60|3@1+ (1,0) [0|7] "" Vector__XXX
 SG_ VehicleSystemInstance : 56|4@1+ (1,0) [0|15] "" Vector__XXX
 SG_ VehicleSystem m0 : 49|7@1+ (1,0) [0|127] "" Vector__XXX
 SG_ ECUInstance : 32|3@1+ (1,0) [0|7] "" Vector__XXX
 SG_ FunctionInstance : 35|5@1+ (1,0) [0|31] "" Vector__XXX
 SG_ Function : 40|8@1+ (1,0) [0|255] "" Vector__XXX
 SG_ ManufacturerCode : 21|11@1+ (1,0) [0|2047] "" Vector__XXX
 SG_ IdentityNumber : 0|21@1+ (1,0) [0|2097152] "" Vector__XXX

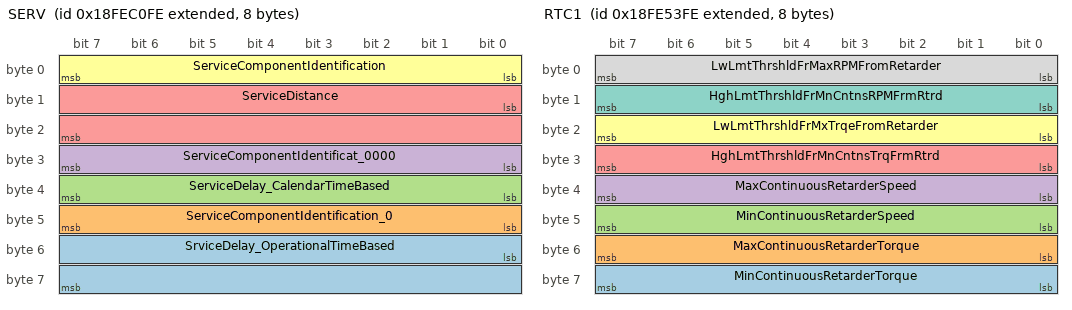
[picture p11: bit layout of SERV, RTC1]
BO_ 2566832382 SERV: 8 Vector__XXX
 SG_ SrviceDelay_OperationalTimeBased : 48|16@1+ (1,-32127) [-32127|32128] "hr" Vector__XXX
 SG_ ServiceComponentIdentification_0 : 40|8@1+ (1,0) [0|250] "ID" Vector__XXX
 SG_ ServiceDelay_CalendarTimeBased : 32|8@1+ (1,-125) [-125|125] "weeks" Vector__XXX
 SG_ ServiceComponentIdentificat_0000 : 24|8@1+ (1,0) [0|250] "ID" Vector__XXX
 SG_ ServiceDistance : 8|16@1+ (5,-160635) [-160635|160640] "km" Vector__XXX
 SG_ ServiceComponentIdentification : 0|8@1+ (1,0) [0|250] "ID" Vector__XXX

BO_ 2633928446 S2: 8 Vector__XXX
 SG_ TimeSinceLastService : 8|16@1+ (1,-32127) [-32127|32128] "hr" Vector__XXX
 SG_ ServiceComponentIdentification : 0|8@1+ (1,0) [0|250] "ID" Vector__XXX

BO_ 2566804478 RTC1: 8 Vector__XXX
 SG_ MinContinuousRetarderTorque : 56|8@1+ (1,-125) [-125|125] "%" Vector__XXX
 SG_ MaxContinuousRetarderTorque : 48|8@1+ (1,-125) [-125|125] "%" Vector__XXX
 SG_ MinContinuousRetarderSpeed : 40|8@1+ (1,0) [0|8000] "rpm" Vector__XXX
 SG_ MaxContinuousRetarderSpeed : 32|8@1+ (1,0) [0|8000] "rpm" Vector__XXX
 SG_ HghLmtThrshldFrMnCntnsTrqFrmRtrd : 24|8@1+ (1,-125) [-125|125] "%" Vector__XXX
 SG_ LwLmtThrshldFrMxTrqeFromRetarder : 16|8@1+ (1,-125) [-125|125] "%" Vector__XXX
 SG_ HghLmtThrshldFrMnCntnsRPMFrmRtrd : 8|8@1+ (1,0) [0|8000] "rpm" Vector__XXX
 SG_ LwLmtThrshldFrMaxRPMFromRetarder : 0|8@1+ (1,0) [0|8000] "rpm" Vector__XXX

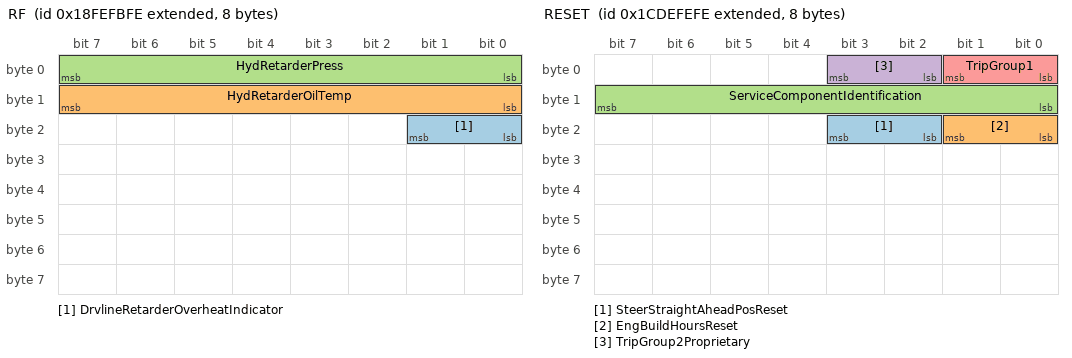
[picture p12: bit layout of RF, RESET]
BO_ 2566847486 RF: 8 Vector__XXX
 SG_ DrvlineRetarderOverheatIndicator : 16|2@1+ (1,0) [0|3] "" Vector__XXX
 SG_ HydRetarderOilTemp : 8|8@1+ (1,-40) [-40|210] "deg C" Vector__XXX
 SG_ HydRetarderPress : 0|8@1+ (16,0) [0|4000] "kPa" Vector__XXX

BO_ 2631859966 RESET: 8 Vector__XXX
 SG_ SteerStraightAheadPosReset : 18|2@1+ (1,0) [0|3] "" Vector__XXX
 SG_ EngBuildHoursReset : 16|2@1+ (1,0) [0|3] "" Vector__XXX
 SG_ ServiceComponentIdentification : 8|8@1+ (1,0) [0|250] "ID" Vector__XXX
 SG_ TripGroup2Proprietary : 2|2@1+ (1,0) [0|3] "" Vector__XXX
 SG_ TripGroup1 : 0|2@1+ (1,0) [0|3] "" Vector__XXX

BO_ 2566840830 RC: 19 Vector__XXX
 SG_ PercentTorqueAtPeakTorquePoint5 : 144|8@1+ (1,-125) [-125|125] "%" Vector__XXX
 SG_ ReferenceRetarderTorque : 128|16@1+ (1,0) [0|64255] "Nm" Vector__XXX
 SG_ RetarderSpeedAtPeakTorquePoint5 : 112|16@1+ (0.125,0) [0|8031.875] "rpm" Vector__XXX
 SG_ PercentTorqueAtPoint4 : 104|8@1+ (1,-125) [-125|125] "%" Vector__XXX
 SG_ RetarderSpeedAtPoint4 : 88|16@1+ (0.125,0) [0|8031.875] "rpm" Vector__XXX
 SG_ PercentTorqueAtPoint3 : 80|8@1+ (1,-125) [-125|125] "%" Vector__XXX
 SG_ RetarderSpeedAtPoint3 : 64|16@1+ (0.125,0) [0|8031.875] "rpm" Vector__XXX
 SG_ PercentTorqueAtMaxSpeedPoint2 : 56|8@1+ (1,-125) [-125|125] "%" Vector__XXX
 SG_ MaxRetarderSpeedPoint2 : 40|16@1+ (0.125,0) [0|8031.875] "rpm" Vector__XXX
 SG_ PercentTorqueAtIdlePoint1 : 32|8@1+ (1,-125) [-125|125] "%" Vector__XXX
 SG_ RetarderSpeedAtIdlePoint1 : 16|16@1+ (0.125,0) [0|8031.875] "rpm" Vector__XXX
 SG_ RetarderCtrlMethod : 8|8@1+ (1,0) [0|250] "steps" Vector__XXX
 SG_ RetarderLocation : 4|4@1+ (1,0) [0|15] "" Vector__XXX
 SG_ RetarderType : 0|4@1+ (1,0) [0|15] "" Vector__XXX

BO_ 2633930238 RBI: 8 Vector__XXX
 SG_ EngOperationTimeSinceRebuild : 0|32@1+ (1,0) [0|4211081215] "s" Vector__XXX

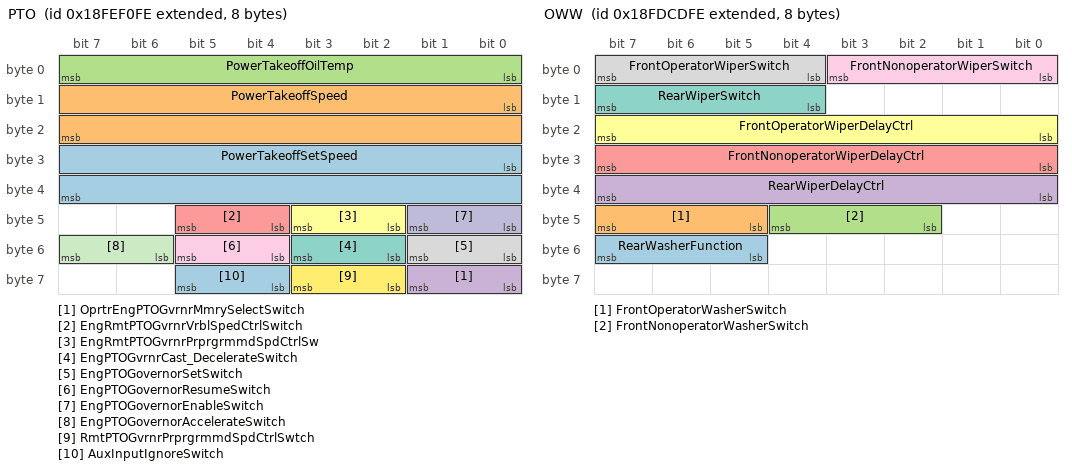
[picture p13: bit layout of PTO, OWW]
BO_ 2566844670 PTO: 8 Vector__XXX
 SG_ PowerTakeoffSetSpeed : 24|16@1+ (0.125,0) [0|8031.875] "rpm" Vector__XXX
 SG_ PowerTakeoffSpeed : 8|16@1+ (0.125,0) [0|8031.875] "rpm" Vector__XXX
 SG_ PowerTakeoffOilTemp : 0|8@1+ (1,-40) [-40|210] "deg C" Vector__XXX
 SG_ OprtrEngPTOGvrnrMmrySelectSwitch : 56|2@1+ (1,0) [0|3] "" Vector__XXX
 SG_ EngRmtPTOGvrnrVrblSpedCtrlSwitch : 44|2@1+ (1,0) [0|3] "" Vector__XXX
 SG_ EngRmtPTOGvrnrPrprgrmmdSpdCtrlSw : 42|2@1+ (1,0) [0|3] "" Vector__XXX
 SG_ EngPTOGvrnrCast_DecelerateSwitch : 50|2@1+ (1,0) [0|3] "" Vector__XXX
 SG_ EngPTOGovernorSetSwitch : 48|2@1+ (1,0) [0|3] "" Vector__XXX
 SG_ EngPTOGovernorResumeSwitch : 52|2@1+ (1,0) [0|3] "" Vector__XXX
 SG_ EngPTOGovernorEnableSwitch : 40|2@1+ (1,0) [0|3] "" Vector__XXX
 SG_ EngPTOGovernorAccelerateSwitch : 54|2@1+ (1,0) [0|3] "" Vector__XXX
 SG_ RmtPTOGvrnrPrprgrmmdSpdCtrlSwtch : 58|2@1+ (1,0) [0|3] "" Vector__XXX
 SG_ AuxInputIgnoreSwitch : 60|2@1+ (1,0) [0|3] "" Vector__XXX

BO_ 2566770174 OWW: 8 Vector__XXX
 SG_ RearWasherFunction : 53|3@1+ (1,0) [0|7] "" Vector__XXX
 SG_ FrontOperatorWasherSwitch : 45|3@1+ (1,0) [0|7] "" Vector__XXX
 SG_ FrontNonoperatorWasherSwitch : 42|3@1+ (1,0) [0|7] "" Vector__XXX
 SG_ RearWiperDelayCtrl : 32|8@1+ (0.4,0) [0|100] "%" Vector__XXX
 SG_ FrontNonoperatorWiperDelayCtrl : 24|8@1+ (0.4,0) [0|100] "%" Vector__XXX
 SG_ FrontOperatorWiperDelayCtrl : 16|8@1+ (0.4,0) [0|100] "%" Vector__XXX
 SG_ RearWiperSwitch : 12|4@1+ (1,0) [0|15] "" Vector__XXX
 SG_ FrontOperatorWiperSwitch : 4|4@1+ (1,0) [0|15] "" Vector__XXX
 SG_ FrontNonoperatorWiperSwitch : 0|4@1+ (1,0) [0|15] "" Vector__XXX

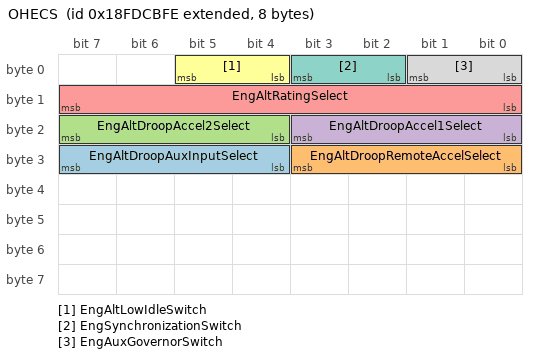
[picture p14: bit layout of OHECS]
BO_ 2566769662 OHECS: 8 Vector__XXX
 SG_ EngAltDroopAuxInputSelect : 28|4@1+ (1,0) [0|15] "" Vector__XXX
 SG_ EngAltDroopRemoteAccelSelect : 24|4@1+ (1,0) [0|15] "" Vector__XXX
 SG_ EngAltDroopAccel2Select : 20|4@1+ (1,0) [0|15] "" Vector__XXX
 SG_ EngAltDroopAccel1Select : 16|4@1+ (1,0) [0|15] "" Vector__XXX
 SG_ EngAltRatingSelect : 8|8@1+ (1.02,0) [0|255] "" Vector__XXX
 SG_ EngAltLowIdleSwitch : 4|2@1+ (1,0) [0|3] "" Vector__XXX
 SG_ EngSynchronizationSwitch : 2|2@1+ (1,0) [0|3] "" Vector__XXX
 SG_ EngAuxGovernorSwitch : 0|2@1+ (1,0) [0|3] "" Vector__XXX

CM_ SG_ 2633938430 TripSuddenDecelerations "Total number of decelerations whenever the vehicle deceleration is more than XYZ km/h/sec (where XYZ is a calibratible";
CM_ SG_ 2633938430 TrpNumberOfIdleShutdownOverrides "Total number of times an operator disables idle shutdown to prevent an engine shutdown, since the last trip reset.";
CM_ SG_ 2633938430 TripNumberOfIdleShutdowns "Total number of times the engine has been shutdown due to idling too long (at normal idle or fast idle) since the last trip";
CM_ SG_ 2633938430 TripNumberOfHotShutdowns "Total number of hot shutdowns since the last trip reset. A hot shutdown is based on operation at high load or high engine";
CM_ BO_ 2348875518 "NOTE - Retarder may be disabled by commanding a torque limit of 0%. Use of the limit mode allows the use of the";
CM_ SG_ 2348875518 MessageChecksum "The message checksum is used to verify the signal path from the transmitting device to the receiving device.";
CM_ SG_ 2348875518 MessageCounter "The message counter is used to detect situations where the transmitting ECU malfunction repeats the same frame all the";
CM_ SG_ 2348875518 EngRequestedTorqueHighResolution "This parameter displays an additional torque in percent of the reference engine torque.";
CM_ SG_ 2348875518 TSC1CtrlPurpose "State signal which indicates which control mode the sending device is using to generate the TSC1 command. Note that";
CM_ SG_ 2348875518 TSC1TransRate "This parameter indicates the transmission rate at which the sending device will transmit the TSC1 message. The engine";
CM_ SG_ 2348875518 EngRequestedTorque_TorqueLimit "Parameter provided to the engine or retarder in the torque/speed control message for controlling or limiting the output";
CM_ SG_ 2348875518 EngRequestedSpeed_SpeedLimit "Parameter provided to the engine from external sources in the torque/speed control message. This is the engine speed";
CM_ SG_ 2348875518 OverrideCtrlModePriority "This field is used as an input to the engine or retarder to determine the priority of the Override Control Mode received in";
CM_ SG_ 2348875518 EngRequestedSpeedCtrlConditions "This mode tells the engine control system the governor characteristics that are desired during speed control. The four";
CM_ SG_ 2348875518 EngOverrideCtrlMode "The override control mode defines which sort of command is used:";
CM_ BO_ 2566766846 "Used to notify the transit link devices of real-time boarding and exiting passengers or to indicate the total number of";
CM_ SG_ 2566766846 TransitRunStatus "Status of the run switch for the vehicle.";
CM_ SG_ 2566766846 VehicleUseStatus "Used to indicate the proper or unauthorized use of the vehicle. The administrative control device or any device issuing the";
CM_ SG_ 2566766846 SilentAlarmStatus "Used to report silent alarm push button status.";
CM_ SG_ 2566766846 PatronCount "Count of the number of passengers on a transit vehicle. If the type of passenger count (SPN 3043) is 0, the patron count";
CM_ SG_ 2566766846 TypeOfPassengerCount "Used to notify transit link devices of the type of passenger counting system used in the vehicle. Some passenger";
CM_ BO_ 2566765310 "Used to report alarms of the fare collection unit.";
CM_ SG_ 2566765310 FareboxAlarmIdentifier "Indicates the nature of the farebox alarm condition.";
CM_ SG_ 2566765310 FareboxEmergencyStatus "Indicates if a farebox emergency condition exists.";
CM_ BO_ 2566765566 "Used to report stop level point of sale detail.";
CM_ SG_ 2566765566 TransferSold "Indicates that a transfer was sold or issued on this transaction including its type and/or restrictions. The final definitions of";
CM_ SG_ 2566765566 RouteNumber "The route number issuing the transfer.";
CM_ SG_ 2566765566 TransferType "The kind of transfer used";
CM_ SG_ 2566765566 TypeOfService "The type of service provided";
CM_ SG_ 2566765566 InitialFareAgency "Identifies where the initial fare is paid";
CM_ SG_ 2566765566 PassCategory "Agency defined value indicating the category of the passenger associated with this fare";
CM_ SG_ 2566765566 FareValidity "Agency defined value indicating validity of this fare";
CM_ SG_ 2566765566 PaymentDetails "Payment details.";
CM_ SG_ 2566765566 TypeOfFare "Type of Fare";
CM_ SG_ 2566765566 PassengerType "Enumerated value representing the type/class of passenger, as defined by the agency.";
CM_ SG_ 2566765566 TransactionType "Enumerated value representing the type of transaction completed";
CM_ BO_ 2566765822 "Used to identify service, assignments, and fare preset detail of the fare collection unit.";
CM_ SG_ 2566765822 DriversFareboxSecurityCode "Security code for the farebox, numerical only.";
CM_ SG_ 2566765822 AssignedBlock "The agency defined block number for this trip";
CM_ SG_ 2566765822 AssignedRun "The agency defined run number for this trip";
CM_ SG_ 2566765822 AssignedRoute "The identity number assigned to this route.";
CM_ SG_ 2566765822 PatternNumber "The agency defined pattern number for this trip";
CM_ SG_ 2566765822 TripNumber "The identity number assigned to this trip.";
CM_ SG_ 2566765822 FarePresets "Fare Presets";
CM_ SG_ 2566765822 TripDirection "The general direction of travel for this trip.";
CM_ SG_ 2566765822 TripStatus "Trip Status";
CM_ SG_ 2566765822 FareboxServiceStatus "Indicates if the farebox is in or out of service.";
CM_ BO_ 2566766078 "Status and configuration of the device used for intersection preemption.";
CM_ SG_ 2566766078 VehicleID "Numerical designation of the vehicle. 65535 is used to represent the vehicle ID is not available.";
CM_ SG_ 2566766078 StrobeActivationCtrlStatus "Strobe activation control status";
CM_ SG_ 2566766078 TransitDoorEnable "Transit door enable";
CM_ SG_ 2566766078 PriorityOfRespSentByEmitter "Priority of response sent by emitter";
CM_ SG_ 2566766078 IntrsctnPrmptionRequest_Response "Status of the intersection signal preemption";
CM_ SG_ 2566766078 TransitRouteIDUsage "Transit route ID usage";
CM_ SG_ 2566766078 RangeCodeEnable "Range code enable";
CM_ BO_ 2566766590 "Identification of a transit route milepost";
CM_ SG_ 2566766590 NmbrOfBytsInThMlpstIdntification "Number of bytes in the Milepost Identification. This parameter identifies the length, in bytes, of the data in SPN 590";
CM_ BO_ 2566766334 "The current route assigned to this transit vehicle. The transit route information may be entered into different devices by";
CM_ SG_ 2566766334 NmbrOfBytsInThTrnstAssgndBlckIdn "Number of bytes in the Transit Assigned Block Identity. This parameter identifies the length, in bytes, of the data in SPN";
CM_ SG_ 2566766334 NmbrOfBytsInThTrnstAssgndRnIdntt "Number of bytes in the Transit Assigned Run Identity. This parameter identifies the length, in bytes, of the data in SPN";
CM_ SG_ 2566766334 NmbrOfBytsInThTrnstAssgndRtIdntt "Number of bytes in the Transit Assigned Route Identity. This parameter identifies the length, in bytes, of the data in SPN";
CM_ SG_ 2566766334 Agency "The identity of the agency involved in this transaction";
CM_ BO_ 2561605374 "Tire Pressure Reference Setting";
CM_ SG_ 2561605374 TireLocation "Identifies which tire is associated with the parametric data in this PGN.";
CM_ BO_ 2566765054 "Tire Pressure Reference Information";
CM_ SG_ 2566765054 TireLocation "Identifies which tire is associated with the parametric data in this PGN.";
CM_ SG_ 2633923326 SteerChannelTirePress "The latest gage pressure reading of the steer group of tires, as opposed to the pressure in each tire.";
CM_ SG_ 2633923326 DriveChannelTirePress "The latest gage pressure reading of the drive group of tires, as opposed to the pressure in each tire.";
CM_ SG_ 2633923326 TrailerTagOrPushChannelTirePress "The latest gage pressure reading of the trailer, tag, or push group of tires, as opposed to the pressure in each tire.";
CM_ SG_ 2633923070 SteerChannelTirePressTarget "The tire pressure control system’s target gage pressure for the steer group of tires.";
CM_ SG_ 2633923070 DriveChannelTirePressTarget "The tire pressure control system’s target gage pressure for the drive group of tires.";
CM_ SG_ 2633923070 TrlrTgOrPshChnnelTirePressTarget "The tire pressure control system’s target gage pressure for the trailer, tag, or push group of tires.";
CM_ SG_ 2633922814 PCUTrilerTagOrPushSolenoidStatus "Current state of the trailer, tag, or push solenoid used to implement a tire pressure control system in its pneumatic control";
CM_ SG_ 2633922814 PCUSupplySolenoidStatus "Current state of the supply solenoid used to implement a tire pressure control system in its pneumatic control unit (PCU).";
CM_ SG_ 2633922814 PCUCtrlSolenoidStatus "Current state of the control solenoid used to implement a tire pressure control system in its pneumatic control unit (PCU).";
CM_ SG_ 2633922814 PCUDeflateSolenoidStatus "Current state of the deflate solenoid used to implement a tire pressure control system in its pneumatic control unit (PCU).";
CM_ SG_ 2633922814 TirePressSupplySwitchStatus "Current state of an open/closed type switch used to determine if adequate pressure exists for system implementation.";
CM_ SG_ 2633922814 PCUSteerSolenoidStatus "Current state of the steer solenoid used to implement a tire pressure control system in its pneumatic control unit (PCU).";
CM_ SG_ 2633922814 PCUDriveSolenoidStatus "Current state of the drive solenoid used to implement a tire pressure control system in its pneumatic control unit (PCU).";
CM_ SG_ 2633922814 DriveChannelMode "Indicates the functional mode of trailer/tag channel of the tire pressure control system.";
CM_ SG_ 2633922814 Trailer_tagChannelMode "Indicates the functional mode of trailer/tag channel of the tire pressure control system.";
CM_ SG_ 2633922814 SteerChannelMode "Indicates the functional mode of steer channel of the tire pressure control system.";
CM_ SG_ 2633922814 TirePressCheckInterval "The interval at which the system will check the tire pressures (e.g., 5, 10, 15 min.).";
CM_ BO_ 2566845694 "Tire Condition";
CM_ SG_ 2566845694 TirePressThresholdDetection_13 "Signal indicating the pressure level of the tire.";
CM_ SG_ 2566845694 TirePressThresholdDetection_12 "Signal indicating the pressure level of the tire.";
CM_ SG_ 2566845694 TirePressThresholdDetection_11 "Signal indicating the pressure level of the tire.";
CM_ SG_ 2566845694 TirePressThresholdDetection_10 "Signal indicating the pressure level of the tire.";
CM_ SG_ 2566845694 TirePressThresholdDetection_01 "Signal indicating the pressure level of the tire.";
CM_ SG_ 2566845694 TirePress_33 "Pressure at which air is contained in cavity formed by tire and rim.";
CM_ SG_ 2566845694 TirePress_32 "Pressure at which air is contained in cavity formed by tire and rim.";
CM_ SG_ 2566845694 TirePress_31 "Pressure at which air is contained in cavity formed by tire and rim.";
CM_ SG_ 2566845694 TirePress_30 "Pressure at which air is contained in cavity formed by tire and rim.";
CM_ SG_ 2566845694 TirePress_23 "Pressure at which air is contained in cavity formed by tire and rim.";
CM_ SG_ 2566845694 TirePress_22 "Pressure at which air is contained in cavity formed by tire and rim.";
CM_ SG_ 2566845694 TirePress_21 "Pressure at which air is contained in cavity formed by tire and rim.";
CM_ SG_ 2566845694 TirePress_20 "Pressure at which air is contained in cavity formed by tire and rim.";
CM_ SG_ 2566845694 TirePress_13 "Pressure at which air is contained in cavity formed by tire and rim.";
CM_ SG_ 2566845694 TirePress_12 "Pressure at which air is contained in cavity formed by tire and rim.";
CM_ SG_ 2566845694 TirePress_11 "Pressure at which air is contained in cavity formed by tire and rim.";
CM_ SG_ 2566845694 TirePress_10 "Pressure at which air is contained in cavity formed by tire and rim.";
CM_ SG_ 2566845694 TireAirLeakageRate_33 "The pressure loss rate of a tire.";
CM_ SG_ 2566845694 TireAirLeakageRate_32 "The pressure loss rate of a tire.";
CM_ SG_ 2566845694 TireAirLeakageRate_31 "The pressure loss rate of a tire.";
CM_ SG_ 2566845694 TireAirLeakageRate_30 "The pressure loss rate of a tire.";
CM_ SG_ 2566845694 TireAirLeakageRate_23 "The pressure loss rate of a tire.";
CM_ SG_ 2566845694 TireAirLeakageRate_22 "The pressure loss rate of a tire.";
CM_ SG_ 2566845694 TireAirLeakageRate_21 "The pressure loss rate of a tire.";
CM_ SG_ 2566845694 TireAirLeakageRate_20 "The pressure loss rate of a tire.";
CM_ SG_ 2566845694 TireAirLeakageRate_13 "The pressure loss rate of a tire.";
CM_ SG_ 2566845694 TireAirLeakageRate_12 "The pressure loss rate of a tire.";
CM_ SG_ 2566845694 TireAirLeakageRate_11 "The pressure loss rate of a tire.";
CM_ SG_ 2566845694 TireAirLeakageRate_10 "The pressure loss rate of a tire.";
CM_ SG_ 2566845694 TireAirLeakageRate_01 "The pressure loss rate of a tire.";
CM_ SG_ 2566845694 TireAirLeakageRate_00 "The pressure loss rate of a tire.";
CM_ SG_ 2566845694 CTIWheelSensorStatus_33 "Indicates whether the wheel is being monitored by the CTI controller.";
CM_ SG_ 2566845694 CTIWheelSensorStatus_32 "Indicates whether the wheel is being monitored by the CTI controller.";
CM_ SG_ 2566845694 CTIWheelSensorStatus_31 "Indicates whether the wheel is being monitored by the CTI controller.";
CM_ SG_ 2566845694 CTIWheelSensorStatus_30 "Indicates whether the wheel is being monitored by the CTI controller.";
CM_ SG_ 2566845694 CTIWheelSensorStatus_23 "Indicates whether the wheel is being monitored by the CTI controller.";
CM_ SG_ 2566845694 CTIWheelSensorStatus_22 "Indicates whether the wheel is being monitored by the CTI controller.";
CM_ SG_ 2566845694 CTIWheelSensorStatus_21 "Indicates whether the wheel is being monitored by the CTI controller.";
CM_ SG_ 2566845694 CTIWheelSensorStatus_20 "Indicates whether the wheel is being monitored by the CTI controller.";
CM_ SG_ 2566845694 CTIWheelSensorStatus_13 "Indicates whether the wheel is being monitored by the CTI controller.";
CM_ SG_ 2566845694 CTIWheelSensorStatus_12 "Indicates whether the wheel is being monitored by the CTI controller.";
CM_ SG_ 2566845694 CTIWheelSensorStatus_11 "Indicates whether the wheel is being monitored by the CTI controller.";
CM_ SG_ 2566845694 CTIWheelSensorStatus_10 "Indicates whether the wheel is being monitored by the CTI controller.";
CM_ SG_ 2566845694 CTIWheelSensorStatus_01 "Indicates whether the wheel is being monitored by the CTI controller.";
CM_ SG_ 2566845694 CTIWheelEndElectricalFault_33 "Indicates the status of electrical fault on CTI wheel interface.";
CM_ SG_ 2566845694 CTIWheelEndElectricalFault_32 "Indicates the status of electrical fault on CTI wheel interface.";
CM_ SG_ 2566845694 CTIWheelEndElectricalFault_31 "Indicates the status of electrical fault on CTI wheel interface.";
CM_ SG_ 2566845694 CTIWheelEndElectricalFault_30 "Indicates the status of electrical fault on CTI wheel interface.";
CM_ SG_ 2566845694 CTIWheelEndElectricalFault_23 "Indicates the status of electrical fault on CTI wheel interface.";
CM_ SG_ 2566845694 CTIWheelEndElectricalFault_22 "Indicates the status of electrical fault on CTI wheel interface.";
CM_ SG_ 2566845694 CTIWheelEndElectricalFault_21 "Indicates the status of electrical fault on CTI wheel interface.";
CM_ SG_ 2566845694 CTIWheelEndElectricalFault_20 "Indicates the status of electrical fault on CTI wheel interface.";
CM_ SG_ 2566845694 CTIWheelEndElectricalFault_13 "Indicates the status of electrical fault on CTI wheel interface.";
CM_ SG_ 2566845694 CTIWheelEndElectricalFault_12 "Indicates the status of electrical fault on CTI wheel interface.";
CM_ SG_ 2566845694 CTIWheelEndElectricalFault_11 "Indicates the status of electrical fault on CTI wheel interface.";
CM_ SG_ 2566845694 CTIWheelEndElectricalFault_10 "Indicates the status of electrical fault on CTI wheel interface.";
CM_ SG_ 2566845694 CTIWheelEndElectricalFault_01 "Indicates the status of electrical fault on CTI wheel interface.";
CM_ SG_ 2566845694 CTITireStatus_33 "Indicates the status of the tire.";
CM_ SG_ 2566845694 CTITireStatus_32 "Indicates the status of the tire.";
CM_ SG_ 2566845694 CTITireStatus_31 "Indicates the status of the tire.";
CM_ SG_ 2566845694 CTITireStatus_30 "Indicates the status of the tire.";
CM_ SG_ 2566845694 CTITireStatus_23 "Indicates the status of the tire.";
CM_ SG_ 2566845694 CTITireStatus_22 "Indicates the status of the tire.";
CM_ SG_ 2566845694 CTITireStatus_21 "Indicates the status of the tire.";
CM_ SG_ 2566845694 CTITireStatus_20 "Indicates the status of the tire.";
CM_ SG_ 2566845694 CTITireStatus_13 "Indicates the status of the tire.";
CM_ SG_ 2566845694 CTITireStatus_12 "Indicates the status of the tire.";
CM_ SG_ 2566845694 CTITireStatus_11 "Indicates the status of the tire.";
CM_ SG_ 2566845694 CTITireStatus_10 "Indicates the status of the tire.";
CM_ SG_ 2566845694 CTITireStatus_01 "Indicates the status of the tire.";
CM_ SG_ 2566845694 TireTemp_11 "Temperature at the surface of the tire sidewall.";
CM_ SG_ 2566845694 TireTemp_33 "Temperature at the surface of the tire sidewall.";
CM_ SG_ 2566845694 TireTemp_32 "Temperature at the surface of the tire sidewall.";
CM_ SG_ 2566845694 TireTemp_31 "Temperature at the surface of the tire sidewall.";
CM_ SG_ 2566845694 TireTemp_30 "Temperature at the surface of the tire sidewall.";
CM_ SG_ 2566845694 TireTemp_23 "Temperature at the surface of the tire sidewall.";
CM_ SG_ 2566845694 TireTemp_22 "Temperature at the surface of the tire sidewall.";
CM_ SG_ 2566845694 TireTemp_21 "Temperature at the surface of the tire sidewall.";
CM_ SG_ 2566845694 TireTemp_20 "Temperature at the surface of the tire sidewall.";
CM_ SG_ 2566845694 TireTemp_13 "Temperature at the surface of the tire sidewall.";
CM_ SG_ 2566845694 TireTemp_12 "Temperature at the surface of the tire sidewall.";
CM_ SG_ 2566845694 TireTemp_10 "Temperature at the surface of the tire sidewall.";
CM_ SG_ 2566845694 TireTemp_01 "Temperature at the surface of the tire sidewall.";
CM_ SG_ 2566845694 TireTemp_00 "Temperature at the surface of the tire sidewall.";
CM_ SG_ 2566845694 TirePressThresholdDetection_33 "Signal indicating the pressure level of the tire.";
CM_ SG_ 2566845694 TirePressThresholdDetection_32 "Signal indicating the pressure level of the tire.";
CM_ SG_ 2566845694 TirePressThresholdDetection_31 "Signal indicating the pressure level of the tire.";
CM_ SG_ 2566845694 TirePressThresholdDetection_30 "Signal indicating the pressure level of the tire.";
CM_ SG_ 2566845694 TirePressThresholdDetection_23 "Signal indicating the pressure level of the tire.";
CM_ SG_ 2566845694 TirePressThresholdDetection_22 "Signal indicating the pressure level of the tire.";
CM_ SG_ 2566845694 TirePressThresholdDetection_21 "Signal indicating the pressure level of the tire.";
CM_ SG_ 2566845694 TirePressThresholdDetection_20 "Signal indicating the pressure level of the tire.";
CM_ SG_ 2566845694 TirePressThresholdDetection_00 "Signal indicating the pressure level of the tire.";
CM_ SG_ 2566845694 TirePress_01 "Pressure at which air is contained in cavity formed by tire and rim.";
CM_ SG_ 2566845694 TirePress_00 "Pressure at which air is contained in cavity formed by tire and rim.";
CM_ SG_ 2566845694 CTIWheelSensorStatus_00 "Indicates whether the wheel is being monitored by the CTI controller.";
CM_ SG_ 2566845694 CTIWheelEndElectricalFault_00 "Indicates the status of electrical fault on CTI wheel interface.";
CM_ SG_ 2566845694 CTITireStatus_00 "Indicates the status of the tire.";
CM_ SG_ 2566845694 TireLocation "Identifies which tire is associated with the parametric data in this PGN.";
CM_ BO_ 2633939966 "Trip Fan Information";
CM_ SG_ 2633939966 TripFanOnTimeDueToAManualSwitch "Total time the fan has been on due to manual activation by the operator (i.e., excluding time on due to automatic triggers)";
CM_ SG_ 2633939966 TripFanOnTime "Total time the fan has been on (due to an automatic trigger or manual trigger) since the last trip reset. The fan could be";
CM_ SG_ 2633939966 TripFanOnTimeDueToTheA_CSystem "Total time the fan has been on due to the A/C system since the last trip reset. For the time to be accumulated against the";
CM_ SG_ 2633939966 TripFanOnTimeDueToTheEngSystem "Total time the fan has been on due to engine triggers (i.e., excluding time on due to an operator manual switch or A/C";
CM_ BO_ 2633939710 "Trip Distance Information";
CM_ SG_ 2633939710 TripDistanceInTopGear "Total distance accumulated while the vehicle has operated in top gear for a calibrated minimum time since the last trip";
CM_ SG_ 2633939710 TripGearDownDistance "Total distance accumulated while the vehicle has operated in the gear which is one gear down from top gear and exceeds";
CM_ SG_ 2633939710 TripDistanceOnVSL "Total distance accumulated while the engine torque mode is road speed governing since the last trip reset.";
CM_ SG_ 2564161278 AdjustLocalHourOffset "The hour component for setting the offset between the UTC (Universal Time Coordinate) time and date and a the local";
CM_ SG_ 2564161278 AdjustLocalMinuteOffset "The minute component for setting the offset between the UTC (Universal Time Coordinate) time and date and a the local";
CM_ SG_ 2564161278 AdjustYear "The year component for setting the current calendar date. This should be reported as the year component of the current";
CM_ SG_ 2564161278 AdjustDay "The day component for setting the current calendar date. This should be reported as the day component of the current";
CM_ SG_ 2564161278 AdjustMonth "The month component for setting the current calendar date. This should be reported as the month component of the";
CM_ SG_ 2564161278 AdjustHours "The hours component for setting the current time of day. This should be reported as the hours component of the current";
CM_ SG_ 2564161278 AdjustMinutes "The minutes component for setting the current time of day. This should be reported as the minutes component of the";
CM_ SG_ 2564161278 AdjustSeconds "The seconds component for setting the current time of day. This should be reported as the seconds component of the";
CM_ SG_ 2566842110 LocalHourOffset "The hour component of the offset between the UTC (Universal Time Coordinate) time and date and a local time zone time";
CM_ SG_ 2566842110 LocalMinuteOffset "The minute component of the offset between the UTC time and date and a local time zone time and date. This is the";
CM_ SG_ 2566842110 Year "The year component of the current calendar date. This should be reported as the year component of the current date at";
CM_ SG_ 2566842110 Day "The day component of the current calendar date. This should be reported as the day component of the current date at";
CM_ SG_ 2566842110 Month "The month component of the current calendar date. This should be reported as the month component of the current date";
CM_ SG_ 2566842110 Hours "The hour component of the current time of day. This should be reported as the hour component of the current time at";
CM_ SG_ 2566842110 Minutes "The minutes component of the current time of day. This should be reported as the minutes component of the current time";
CM_ SG_ 2566842110 Seconds "The seconds component of the current time of day. This should be reported as the seconds component of the current";
CM_ SG_ 2566821630 EngDsrdTrboWastegateActuator2Pos "The Requested Valve position of the Turbocharger Wastegate Valve 2, commanded by the engine ECM. A value of 0%";
CM_ SG_ 2566821630 EngTrbWstgateActuator1TempStatus "Used to identify the status of the Engine Turbocharger Wastegate Actuator 1 drive circuitry temperature. Temperature";
CM_ SG_ 2566821630 EngTrbWstgtActtor1PreliminaryFMI "Used to identify the applicable J1939-73 FMI detected in the Engine Turbocharger Wastegate Actuator 1 by the";
CM_ SG_ 2566821630 EngDsrdTrboWastegateActuator1Pos "The Requested Valve position of the Turbocharger Wastegate Valve 1, commanded by the engine ECM. A value of 0%";
CM_ SG_ 2566821630 EngTrbWstgteActuatorCtrlAirPress "Gage pressure of the air used to control the actuator which opens and closes the wastegate valve.";
CM_ SG_ 2566821630 EngTurboWastegateActuator4Pos "Position of the wastegate drive. A value of 0% represents fully closed and a value of 100% represents fully open.";
CM_ SG_ 2566821630 EngTurboWastegateActuator3Pos "Position of the wastegate drive. A value of 0% represents fully closed and a value of 100% represents fully open.";
CM_ SG_ 2566821630 EngTurboWastegateActuator2Pos "Position of the wastegate drive. A value of 0% represents fully closed and a value of 100% represents fully open.";
CM_ SG_ 2566821630 EngTurboWastegateActuator1Pos "Position of the wastegate drive. A value of 0% represents fully closed and a value of 100% represents fully open.";
CM_ BO_ 2365484286 "Tachograph";
CM_ SG_ 2365484286 VehicleOverspeed "Indicates whether the vehicle is exceeding the legal speed limit set in the tachograph.";
CM_ SG_ 2365484286 VehicleMotion "Indicates whether motion of the vehicle is detected or not.";
CM_ SG_ 2365484286 TachographVehicleSpeed "Speed of the vehicle registered by the tachograph.";
CM_ SG_ 2365484286 TachographOutputShaftSpeed "Calculated speed of the transmission output shaft.";
CM_ SG_ 2365484286 DirectionIndicator "Indicates the direction of the vehicle.";
CM_ SG_ 2365484286 TachographPerformance "Indicates the tachograph performance; including electronic or mechanical analysis, instrument analysis, speed sensor";
CM_ SG_ 2365484286 HandlingInformation "Indicates that handling information is present. Information could include “no printer paper”, “no driver card”, etc.";
CM_ SG_ 2365484286 SystemEvent "Indicates that a tachograph event has occurred. This may include power supply interruption, interruption of the speed";
CM_ SG_ 2365484286 DriverCardDriver2 "Indicates the presence of a driver card";
CM_ SG_ 2365484286 Driver2TimeRelatedStates "Indicates if the driver approaches or exceeds working time limits (or other limits).";
CM_ SG_ 2365484286 DriverCardDriver1 "Indicates the presence of a driver card";
CM_ SG_ 2365484286 Driver1TimeRelatedStates "Indicates if the driver approaches or exceeds working time limits (or other limits).";
CM_ SG_ 2365484286 Driver2WorkingState "State of work of the driver.";
CM_ SG_ 2365484286 Driver1WorkingState "State of work of the driver.";
CM_ SG_ 2566771710 EngTurbo4CompressorOutletTemp "Temperature of the air exiting the turbocharger 4 compressor outlet";
CM_ SG_ 2566771710 EngTurbo3CompressorOutletTemp "Temperature of the air exiting the turbocharger 3 compressor outlet";
CM_ SG_ 2566771710 EngTurbo2CompressorOutletTemp "Temperature of the air exiting the turbocharger 2 compressor outlet";
CM_ SG_ 2566771710 EngTurbo1CompressorOutletTemp "Temperature of the air exiting the turbocharger 1 compressor outlet";
CM_ SG_ 2566821886 EngTurbo4TurbineOutletTemp "Temperature of the combustion by-products exiting the turbine side of the turbocharger.";
CM_ SG_ 2566821886 EngTurbo3TurbineOutletTemp "Temperature of the combustion by-products exiting the turbine side of the turbocharger.";
CM_ SG_ 2566821886 EngTurbo2TurbineOutletTemp "Temperature of the combustion by-products exiting the turbine side of the turbocharger.";
CM_ SG_ 2566821886 EngTurbo1TurbineOutletTemp "Temperature of the combustion by-products exiting the turbine side of the turbocharger.";
CM_ SG_ 2566822142 EngTurbo4TurbineIntakeTemp "Temperature of the combustion by-products entering the turbine side of the turbocharger.";
CM_ SG_ 2566822142 EngTurbo3TurbineIntakeTemp "Temperature of the combustion by-products entering the turbine side of the turbocharger.";
CM_ SG_ 2566822142 EngTurbo2TurbineIntakeTemp "Temperature of the combustion by-products entering the turbine side of the turbocharger.";
CM_ SG_ 2566822142 EngTurbo1TurbineIntakeTemp "Temperature of the combustion by-products entering the turbine side of the turbocharger.";
CM_ SG_ 2566822398 EngTurbo4CompressorIntakePress "Gage pressure of the air entering the compressor side of the turbocharger.";
CM_ SG_ 2566822398 EngTurbo3CompressorIntakePress "Gage pressure of the air entering the compressor side of the turbocharger.";
CM_ SG_ 2566822398 EngTurbo2CompressorIntakePress "Gage pressure of the air entering the compressor side of the turbocharger.";
CM_ SG_ 2566822398 EngTurbo1CompressorIntakePress "Gage pressure of the air entering the compressor side of the turbocharger.";
CM_ SG_ 2566822654 EngTurbo4CompressorIntakeTemp "Temperature of the air entering the compressor side of the turbocharger.";
CM_ SG_ 2566822654 EngTurbo3CompressorIntakeTemp "Temperature of the air entering the compressor side of the turbocharger.";
CM_ SG_ 2566822654 EngTurbo2CompressorIntakeTemp "Temperature of the air entering the compressor side of the turbocharger.";
CM_ SG_ 2566822654 EngTurbo1CompressorIntakeTemp "Temperature of the air entering the compressor side of the turbocharger.";
CM_ SG_ 2633931774 EngTurbo4Speed "Rotational velocity of rotor in the turbocharger.";
CM_ SG_ 2633931774 EngTurbo3Speed "Rotational velocity of rotor in the turbocharger.";
CM_ SG_ 2633931774 EngTurbo2Speed "Rotational velocity of rotor in the turbocharger.";
CM_ SG_ 2633931774 EngTurboLubeOilPress2 "Gage pressure of oil in turbocharger lubrication system.";
CM_ BO_ 2566802430 "Transmission Configuration 2";
CM_ SG_ 2566802430 TransTorqueLimit "Parameter provided to the engine from the transmission as a torque limit to be invoked by the engine in the event that";
CM_ BO_ 2566841086 "Total message length depends on total number of forward and reverse gear ratios.";
CM_ SG_ 2566841086 TransGearRatio "The transmission configuration describes the number of forward gears, the number of reverse gears, and the ratio of each";
CM_ SG_ 2566841086 NumberOfForwardGearRatios "Number of forward gear ratios in the transmission, provided as part of the configuration.";
CM_ SG_ 2566841086 NumberOfReverseGearRatios "Number of reverse gear ratios in the transmission, provided as part of the transmission configuration.";
CM_ SG_ 2348941054 TransMode8 "Indicates whether transmission mode 8 is enabled. Modes are manufacturer specific and are not necessarily mutually";
CM_ SG_ 2348941054 TransMode7 "Indicates whether transmission mode 7 is enabled. Modes are manufacturer specific and are not necessarily mutually";
CM_ SG_ 2348941054 TransMode6 "Indicates whether transmission mode 6 is enabled. Modes are manufacturer specific and are not necessarily mutually";
CM_ SG_ 2348941054 TransMode5 "Indicates whether transmission mode 5 is enabled. Modes are manufacturer specific and are not necessarily mutually";
CM_ SG_ 2348941054 TrnsShftSlectorDisplayModeSwitch "Status of the operator’s switch used to ‘toggle’ through multiple display modes of a shift selector display.";
CM_ SG_ 2348941054 TransRequestedLaunchGear "Initial gear for the transmission to start out in when the vehicle is launched from a standing stop, as specified by the";
CM_ SG_ 2348941054 TransMode4 "Indicates whether transmission mode 4 is enabled. Modes are manufacturer specific and are not necessarily mutually";
CM_ SG_ 2348941054 TransMode3 "Indicates whether transmission mode 3 is enabled. Modes are manufacturer specific and are not necessarily mutually";
CM_ SG_ 2348941054 TransMode2 "Indicates whether transmission mode 2 is enabled. Modes are manufacturer specific and are not necessarily mutually";
CM_ SG_ 2348941054 TransMode1 "Indicates whether transmission mode 1 is enabled. Modes are manufacturer specific and are not necessarily mutually";
CM_ SG_ 2348941054 DisengageDiffLockRqCentralRear "Command signal used to disengage the various differential locks, e.g., to allow an undistributed individual wheel control";
CM_ SG_ 2348941054 DisengageDiffLockRqCentralFront "Command signal used to disengage the various differential locks, e.g., to allow an undistributed individual wheel control";
CM_ SG_ 2348941054 DisengageDiffLockRqCentral "Command signal used to disengage the various differential locks, e.g., to allow an undistributed individual wheel control";
CM_ SG_ 2348941054 DisengageDiffLockRqRearAxle2 "Command signal used to disengage the various differential locks, e.g., to allow an undistributed individual wheel control";
CM_ SG_ 2348941054 DisengageDiffLockRqRearAxle1 "Command signal used to disengage the various differential locks, e.g., to allow an undistributed individual wheel control";
CM_ SG_ 2348941054 DisengageDiffLockRqFrontAxle2 "Command signal used to disengage the various differential locks, e.g., to allow an undistributed individual wheel control";
CM_ SG_ 2348941054 DisengageDiffLockRqFrontAxle1 "Command signal used to disengage the various differential locks, e.g., to allow an undistributed individual wheel control";
CM_ SG_ 2348941054 TransRequestedGear "Gear requested by the operator, ABS, or engine.";
CM_ SG_ 2348941054 RequestedPercentClutchSlip "Parameter which represents the percent clutch slip requested by a device.";
CM_ SG_ 2348941054 TransReverseGearShiftInhibitRq "Allows devices external to the normal transmission shift selector system to request the transmission to inhibit shifts into";
CM_ SG_ 2348941054 DisengageDrivelineRq "Command signal used to simply disengage the driveline, e.g., to prevent engine drag torque from causing high wheel slip";
CM_ SG_ 2348941054 TrnsTrqeConverterLockupDisableRq "Command signal to prevent torque converter lockup, which may cause problems in certain circumstances for ASR.";
CM_ SG_ 2348941054 TransGearShiftInhibitRq "Command signal to inhibit gear shifts.";
CM_ BO_ 2566839806 "Turbocharger";
CM_ SG_ 2566839806 EngTurboOilLevelSwitch "Switch signal which indicates the presence of oil at the turbocharger";
CM_ SG_ 2566839806 EngTurbo1Speed "Rotational velocity of rotor in the turbocharger.";
CM_ SG_ 2566839806 EngTurboLubeOilPress1 "Gage pressure of oil in turbocharger lubrication system.";
CM_ BO_ 2633911806 "Averages of information accumulated over the life of the engine";
CM_ SG_ 2633911806 EngTotalAverageFuelEconomy "Average fuel economy, equal to total vehicle distance divided by total fuel used, over the life of the engine";
CM_ SG_ 2633911806 EngTotalAverageFuelRate "Average fuel rate, equal to total fuel used divided by total engine hours, over the life of the engine";
CM_ BO_ 2566775550 "Used for controlling the supply pressure. Often used to raise the pressure of a supply pressure circuit in situations where";
CM_ SG_ 2566775550 AirSuspensionSupplyPressRq "Command signal to influence the pneumatic pressure in the circuit for the electronically controlled air suspension system.";
CM_ SG_ 2566775550 AuxEquipmentSupplyPressRq "Command signal to influence the pneumatic pressure in the auxiliary circuit. This parameter is the setpoint for the";
CM_ SG_ 2566775550 ServiceBrakeAirPressRqCircuit2 "Command signal to influence the pneumatic pressure in the service brake circuit or reservoir #2. This parameter is the";
CM_ SG_ 2566775550 ServiceBrakeAirPressRqCircuit1 "Command signal to influence the pneumatic pressure in the service brake circuit or reservoir #1. This parameter is the";
CM_ SG_ 2566775550 ParkingAnd_orTrailerAirPressRq "Command signal to influence the pneumatic pressure in the circuit or reservoir for the parking brake and/or the trailer";
CM_ SG_ 2566775550 PneumaticSupplyPressRq "Command signal to influence the pneumatic pressure in the main reservoir. This parameter is the setpoint for the";
CM_ SG_ 2566819838 EngExtlShutdownAirSupplyPress "Pressure of the air used to shut off the fuel supply to the engine.";
CM_ BO_ 2566839038 "Byte: 1 Number of software identification fields";
CM_ SG_ 2566839038 NmbrOfSftwreIdentificationFields "Number of software identification designators represented in the software identification parameter group.";
CM_ SG_ 2566839038 SoftwareIdentification "Software identification of an electronic module. As an example, this parameter may be represented with ASCII characters";
CM_ SG_ 2566841598 PTOShutdownHasShutdownEng "Status signal which identifies whether or not the engine has been shutdown by the PTO shutdown system.";
CM_ SG_ 2566841598 EngAirShutoffStatus "State signal which indicates the actual measured position of the Air Shutoff.";
CM_ SG_ 2566841598 EngOverspeedTest "The engine overspeed test signal as measured by the reporting ECM. Engine Overspeed Test is a mechanism to";
CM_ SG_ 2566841598 EngAirShutoffCmdStatus "State signal which indicates when the Air Shutoff driver output is being driven. Disabled means controller wants air";
CM_ SG_ 2566841598 EngAlarmOutputCmdStatus "State signal which indicates when the Alarm driver output is being driven. Not active means the Controller has no alarm";
CM_ SG_ 2566841598 EngAlarmAcknowledge "The Engine Alarm Acknowledge Input signal as measured by the reporting ECM. The Engine Alarm Acknowledge is a";
CM_ SG_ 2566841598 EngProtectionSystemConfig "Parameter which indicates the configuration of the engine shutdown system.";
CM_ SG_ 2566841598 EngProtectionSystemTimerState "Status signal which indicates the current mode of the engine protection system timer system. See Figure SPN1107_A.";
CM_ SG_ 2566841598 EngProtectionSystemTimerOverride "Status signal which indicates the status of the override feature of the engine protection system timer. See Figure";
CM_ SG_ 2566841598 EngPrtctnSystmApprachingShutdown "Status signal which indicates that engine shutdown is imminent. This engine protection signal can be a result of different";
CM_ SG_ 2566841598 EngPrtectionSystemHasShutdownEng "Status signal which indicates whether or not the engine protection system has shutdown the engine. See Figure";
CM_ SG_ 2566841598 EngWaitToStartLamp "Lamp signal which indicates that the engine is too cold to start and the operator should wait until the signal becomes";
CM_ SG_ 2566841598 RefrigerantHighPressSwitch "Switch signal which indicates the position of the high pressure switch in the coolant circuit of an air conditioning system.";
CM_ SG_ 2566841598 RefrigerantLowPressSwitch "Switch signal which indicates the position of the low pressure switch in the coolant circuit of an air conditioning system.";
CM_ SG_ 2566841598 A_CHighPressFanSwitch "Switch signal which indicates that the pressure in the coolant circuit of an air conditioning system is high and the fan may";
CM_ SG_ 2566841598 EngIdleShutdownTimerFunction "Parameter which indicates the configuration of the idle shutdown timer system.";
CM_ SG_ 2566841598 EngIdleShutdownTimerState "Status signal which indicates the current mode of operation of the idle shutdown timer system. See Figure SPN590_A.";
CM_ SG_ 2566841598 EngIdleShutdownTimerOverride "Status signal which indicates the status of the override feature of the idle shutdown timer system. See Figure SPN590_A.";
CM_ SG_ 2566841598 EngIdleShutdownDriverAlertMode "Status signal which indicates the status of the driver alert mode of the idle shutdown timer system. While the driver alert";
CM_ SG_ 2566841598 EngIdleShutdownHasShutdownEng "Status signal which identifies whether or not the engine has been shutdown by the idle shutdown timer system. See";
CM_ BO_ 2633895166 "This message is sent by the Master of a Working Set to identify an individual member of a specific Working Set (Master’s 
Source Address identifies the particular Working Set).";
CM_ SG_ 2633895166 IndustryGroup "0 = Global; 
   1  = On-Highway; 
   2  = Agricultural and Forestry; 
   3  = Construction; 
   4  = Marine;
   5  = Industrial - Process
          Control - Stationary (Gen-Sets)
   6  = Reserve for SAE
   7  = Reserve for SAE";
CM_ SG_ 2633895166 ManufacturerCode "Assigned by NMEA 2000 Committee";
CM_ BO_ 2566832382 "Transmitted with the service component identification that has the shortest distance or nearest time until the next service";
CM_ SG_ 2566832382 SrviceDelay_OperationalTimeBased "The time in vehicle operational time until the next vehicle service inspection is required. A negative value is transmitted if";
CM_ SG_ 2566832382 ServiceComponentIdentification_0 "Identification of component needing service. See Table SPN911_A.Identification of component needing service. See Table SPN911_A.Identification of component needing service. See Table SPN911_A.";
CM_ SG_ 2566832382 ServiceDelay_CalendarTimeBased "The time in weeks until the next vehicle service inspection is required. A negative value is transmitted if the service";
CM_ SG_ 2566832382 ServiceDistance "The distance which can be traveled by the vehicle before the next service inspection is required. A negative distance is";
CM_ BO_ 2633928446 "NOTE - There are two acceptable formats for the Service PGN. Format 1 has only 8 bytes of data and reports the";
CM_ SG_ 2633928446 TimeSinceLastService "The vehicle operation time since the last service was performed. The type of service information is identified by the";
CM_ SG_ 2633928446 ServiceComponentIdentification "Identification of component needing service. See Table SPN911_A.";
CM_ SG_ 2566804478 MinContinuousRetarderTorque "Applied limit for minimum continuous retarder torque";
CM_ SG_ 2566804478 MaxContinuousRetarderTorque "Applied limit for maximum continuous retarder torque.";
CM_ SG_ 2566804478 MinContinuousRetarderSpeed "Applied limit for minimum continuous retarder RPM";
CM_ SG_ 2566804478 MaxContinuousRetarderSpeed "Applied limit for maximum continuous retarder RPM";
CM_ SG_ 2566804478 HghLmtThrshldFrMnCntnsTrqFrmRtrd "Maximum allowable value for minimum continuous retarder torque.";
CM_ SG_ 2566804478 LwLmtThrshldFrMxTrqeFromRetarder "Minimum allowable value for maximum continuous retarder torque.";
CM_ SG_ 2566804478 HghLmtThrshldFrMnCntnsRPMFrmRtrd "Maximum allowable value for minimum continuous retarder speed";
CM_ SG_ 2566804478 LwLmtThrshldFrMaxRPMFromRetarder "Minimum allowable value for maximum continuous retarder speed";
CM_ SG_ 2566847486 DrvlineRetarderOverheatIndicator "Signal from the driveline retarder indicating that its fluid temperature is above normal acceptable limits, and as a result,";
CM_ SG_ 2566847486 HydRetarderOilTemp "Temperature of oil found in a hydraulic retarder.";
CM_ SG_ 2566847486 HydRetarderPress "Gage pressure of oil in hydraulic retarder system.";
CM_ BO_ 2631859966 "NOTE—This message requires an Acknowledgement response (See J1939-21, PGN 59392) from the receiving node.";
CM_ SG_ 2631859966 SteerStraightAheadPosReset "Used to reset the straight ahead position for a steering sensor in the steering column or a steering controller's straight";
CM_ SG_ 2631859966 EngBuildHoursReset "Command signal used to reset the engine rebuild hours.";
CM_ SG_ 2631859966 ServiceComponentIdentification "Identification of component needing service. See Table SPN911_A.";
CM_ SG_ 2631859966 TripGroup2Proprietary "Command signal used to reset proprietary parameters associated with a trip but not defined within this document.";
CM_ SG_ 2631859966 TripGroup1 "Command signal used to reset the PGNs and parameters as defined in Table SPN988_A.";
CM_ BO_ 2566840830 "This map describes the stationary behavior of the retarder.";
CM_ SG_ 2566840830 PercentTorqueAtPeakTorquePoint5 "The torque limit that indicates the available retarder torque which can be provided by the retarder at point 5 of the retarder";
CM_ SG_ 2566840830 ReferenceRetarderTorque "This parameter is the 100% reference value for all defined indicated retarder torque parameters. It is only defined once";
CM_ SG_ 2566840830 RetarderSpeedAtPeakTorquePoint5 "Please reference PGN 65249";
CM_ SG_ 2566840830 PercentTorqueAtPoint4 "The torque limit that indicates the available retarder torque which can be provided by the retarder at points 3 and 4 of the";
CM_ SG_ 2566840830 RetarderSpeedAtPoint4 "Retarder speed of point 4 of the engine retarder torque map. Please reference PGN 65249.";
CM_ SG_ 2566840830 PercentTorqueAtPoint3 "The torque limit that indicates the available retarder torque which can be provided by the retarder at points 3 and 4 of the";
CM_ SG_ 2566840830 RetarderSpeedAtPoint3 "Retarder speed of point 3 of the engine retarder torque map. Please reference PGN 65249.";
CM_ SG_ 2566840830 PercentTorqueAtMaxSpeedPoint2 "The torque limit that indicates the available retarder torque which can be provided by the retarder at its maximum speed.";
CM_ SG_ 2566840830 MaxRetarderSpeedPoint2 "Maximum speed of retarder (Please reference PGN 65249).";
CM_ SG_ 2566840830 PercentTorqueAtIdlePoint1 "The torque limit that indicates the available retarder torque which can be provided by the retarder at idle speed. The data";
CM_ SG_ 2566840830 RetarderSpeedAtIdlePoint1 "Please reference PGN 65249";
CM_ SG_ 2566840830 RetarderCtrlMethod "This parameter identifies the number of steps used by the retarder.";
CM_ SG_ 2566840830 RetarderLocation "This parameter defines whether the “torque/speed curve” defined by the retarder configuration message (PGN 65249) is";
CM_ SG_ 2566840830 RetarderType "A vehicle retarder is a supplementary device to the wheel brakes for the driver to better control the vehicle. The wheel";
CM_ SG_ 2633930238 EngOperationTimeSinceRebuild "The time in engine operation since the last engine rebuild.";
CM_ BO_ 2566844670 "Power Takeoff Information";
CM_ SG_ 2566844670 PowerTakeoffSetSpeed "Rotational velocity selected by operator for device used to transmit engine power to auxiliary equipment.";
CM_ SG_ 2566844670 PowerTakeoffSpeed "Rotational velocity of device used to transmit engine power to auxiliary equipment.";
CM_ SG_ 2566844670 PowerTakeoffOilTemp "Temperature of lubricant in device used to transmit engine power to auxiliary equipment.";
CM_ SG_ 2566844670 OprtrEngPTOGvrnrMmrySelectSwitch "Measured state of the operator’s engine PTO governor memory select switch. This switch selects which of the two";
CM_ SG_ 2566844670 EngRmtPTOGvrnrVrblSpedCtrlSwitch "Switch signal which indicates that the remote PTO governor toggle switch is in the enabled (ON) position. If the toggle";
CM_ SG_ 2566844670 EngRmtPTOGvrnrPrprgrmmdSpdCtrlSw "Switch signal which indicates that the remote PTO governor toggle switch is in the enabled (ON) position. If the toggle";
CM_ SG_ 2566844670 EngPTOGvrnrCast_DecelerateSwitch "Switch signal of the PTO control activator which indicates that the activator is in the position to \"coast/decelerate\" the PTO";
CM_ SG_ 2566844670 EngPTOGovernorSetSwitch "Switch signal of the PTO control activator which indicates that the activator is in the position to \"set\" the engine PTO";
CM_ SG_ 2566844670 EngPTOGovernorResumeSwitch "Switch signal of the PTO control activator which indicates that the activator is in the position to \"resume\" a previously";
CM_ SG_ 2566844670 EngPTOGovernorEnableSwitch "Switch signal which indicates that the PTO governor toggle switch is in the enabled (ON) position and therefore it is";
CM_ SG_ 2566844670 EngPTOGovernorAccelerateSwitch "Switch signal of the PTO control activator which indicates that the activator is in the position to \"accelerate\" the PTO";
CM_ SG_ 2566844670 RmtPTOGvrnrPrprgrmmdSpdCtrlSwtch "Switch signal which indicates that the remote PTO governor toggle switch #2 is in the enabled (ON) position. If the toggle";
CM_ SG_ 2566844670 AuxInputIgnoreSwitch "Switch signal which overrides other switch input's ability to disable an engine's operating condition.";
CM_ BO_ 2566770174 "Message for items related to the operators controls for the window wipers and washers on the front and rear cab windows";
CM_ SG_ 2566770174 RearWasherFunction "State of operation selected by operator switch for the rear washer. The parameter, 'Front Operator Washer Switch’";
CM_ SG_ 2566770174 FrontOperatorWasherSwitch "State of operation selected by operator switch for the washer in front of the operator position. This parameter, 'Front";
CM_ SG_ 2566770174 FrontNonoperatorWasherSwitch "State of operation selected by operator switch for the front washer not in front of the operator position. The parameter,";
CM_ SG_ 2566770174 RearWiperDelayCtrl "Time between cycles of the rear wiper (i.e. from end of cycle 'n' to start of cycle 'n+1') as selected by the operator control";
CM_ SG_ 2566770174 FrontNonoperatorWiperDelayCtrl "Time between cycles of the front non-operator side wiper (i.e. from end of cycle 'n' to start of cycle 'n+1') as selected by";
CM_ SG_ 2566770174 FrontOperatorWiperDelayCtrl "Time between cycles of the front operator side wiper (i.e. from end of cycle 'n' to start of cycle 'n+1') as selected by the";
CM_ SG_ 2566770174 RearWiperSwitch "State of operation selected by operator switch for the rear wiper. The parameter, 'Front Operator Washer Switch' should";
CM_ SG_ 2566770174 FrontOperatorWiperSwitch "State of operation selected by operator switch for the Wiper in front of the operator position. This parameter, 'Front";
CM_ SG_ 2566770174 FrontNonoperatorWiperSwitch "State of operation selected by operator switch for the front wiper not in front of the operator position. The parameter,";
CM_ BO_ 2566769662 "Allows for the selection of off-highway engine control modes, as they apply to different modes of engine operation which";
CM_ SG_ 2566769662 EngAltDroopAuxInputSelect "In some off-highway applications it may be desirable to have multiple droop settings available across the range of engine";
CM_ SG_ 2566769662 EngAltDroopRemoteAccelSelect "In some off-highway applications it may be desirable to have multiple droop settings available across the range of engine";
CM_ SG_ 2566769662 EngAltDroopAccel2Select "Same description as Engine Alternate Droop Accelerator 1 Select (SPN 2881) except that the selections may apply to";
CM_ SG_ 2566769662 EngAltDroopAccel1Select "In some off-highway applications it may be desirable to have multiple droop settings available across the range of engine";
CM_ SG_ 2566769662 EngAltRatingSelect "In some off-highway applications it may be desirable to have multiple engine ratings available for selection by the";
CM_ SG_ 2566769662 EngAltLowIdleSwitch "Operator switch which selects between two low idle speeds, default and alternate.";
CM_ SG_ 2566769662 EngSynchronizationSwitch "This is the On/Off operation of the Multiple Unit Synchronization functionality. When it is enabled (i.e. On) the master";
CM_ SG_ 2566769662 EngAuxGovernorSwitch "This is the On/Off operation of the Auxiliary Governor feature switch. This feature is used to allow engine speed to be";
BA_DEF_ SG_  "SigType" ENUM  "Default","Range","RangeSigned","ASCII","Discrete","Control","ReferencePGN","DTC","StringDelimiter","StringLength","StringLengthControl";
BA_DEF_ SG_  "GenSigStartValue" INT 0 10000;
BA_DEF_ SG_  "GenSigSendType" ENUM  "Cyclic","OnWrite","OnWriteWithRepetition","OnChange","OnChangeWithRepetition","IfActive","IfActiveWithRepetition","NoSigSendType";
BA_DEF_ SG_  "GenSigILSupport" ENUM  "No","Yes";
BA_DEF_ SG_  "GenSigEVName" STRING ;
BA_DEF_ SG_  "SPN" INT 0 524287;
BA_DEF_ SG_  "SAEDocument" STRING ;
BA_DEF_ BO_  "GenMsgStartDelayTime" INT 0 100000;
BA_DEF_ BO_  "GenMsgILSupport" ENUM  "No","Yes";
BA_DEF_ BO_  "GenMsgRequestable" INT 0 1;
BA_DEF_ BO_  "GenMsgSendType" ENUM  "cyclic","NotUsed","NotUsed","NotUsed","NotUsed","NotUsed","NotUsed","IfActive","noMsgSendType";
BA_DEF_ BO_  "VFrameFormat" ENUM  "StandardCAN","ExtendedCAN","reserved","J1939PG";
BA_DEF_ BO_  "SingleFrame" INT 0 1;
BA_DEF_ BO_  "GenMsgCycleTime" INT 0 3600000;
BA_DEF_ BO_  "SAE_Document" STRING ;
BA_DEF_ SG_  "SystemSignalLongSymbol" STRING ;
BA_DEF_DEF_  "SigType" "Default";
BA_DEF_DEF_  "GenSigStartValue" 0;
BA_DEF_DEF_  "GenSigSendType" "NoSigSendType";
BA_DEF_DEF_  "GenSigILSupport" "Yes";
BA_DEF_DEF_  "GenSigEVName" "Env@Nodename_@Signame";
BA_DEF_DEF_  "SPN" 0;
BA_DEF_DEF_  "SAEDocument" "";
BA_DEF_DEF_  "GenMsgStartDelayTime" 0;
BA_DEF_DEF_  "GenMsgILSupport" "Yes";
BA_DEF_DEF_  "GenMsgRequestable" 1;
BA_DEF_DEF_  "GenMsgSendType" "noMsgSendType";
BA_DEF_DEF_  "VFrameFormat" "J1939PG";
BA_DEF_DEF_  "SingleFrame" 1;
BA_DEF_DEF_  "GenMsgCycleTime" 0;
BA_DEF_DEF_  "SAE_Document" "";
BA_DEF_DEF_  "SystemSignalLongSymbol" "";
BA_ "SAE_Document" BO_ 2633938430 "J1939-71";
BA_ "GenMsgSendType" BO_ 2348875518 0;
BA_ "GenMsgCycleTime" BO_ 2348875518 10;
BA_ "SAE_Document" BO_ 2348875518 "J1939-71";
BA_ "SAE_Document" BO_ 2566766846 "J1939-71";
BA_ "SAE_Document" BO_ 2566765310 "J1939-71";
BA_ "SAE_Document" BO_ 2566765566 "J1939-71";
BA_ "SAE_Document" BO_ 2566765822 "J1939-71";
BA_ "SAE_Document" BO_ 2566766078 "J1939-71";
BA_ "SAE_Document" BO_ 2566766590 "J1939-71";
BA_ "SAE_Document" BO_ 2566766334 "J1939-71";
BA_ "SAE_Document" BO_ 2561605374 "J1939-71";
BA_ "SAE_Document" BO_ 2566765054 "J1939-71";
BA_ "SAE_Document" BO_ 2633923326 "J1939-71";
BA_ "SAE_Document" BO_ 2633923070 "J1939-71";
BA_ "SAE_Document" BO_ 2633922814 "J1939-71";
BA_ "GenMsgSendType" BO_ 2566845694 0;
BA_ "GenMsgCycleTime" BO_ 2566845694 10000;
BA_ "SAE_Document" BO_ 2566845694 "J1939-71";
BA_ "SAE_Document" BO_ 2633939966 "J1939-71";
BA_ "SAE_Document" BO_ 2633939710 "J1939-71";
BA_ "SAE_Document" BO_ 2564161278 "J1939-71";
BA_ "SAE_Document" BO_ 2566842110 "J1939-71";
BA_ "GenMsgSendType" BO_ 2566821630 0;
BA_ "GenMsgCycleTime" BO_ 2566821630 100;
BA_ "SAE_Document" BO_ 2566821630 "J1939-71";
BA_ "GenMsgSendType" BO_ 2365484286 0;
BA_ "GenMsgCycleTime" BO_ 2365484286 50;
BA_ "SAE_Document" BO_ 2365484286 "J1939-71";
BA_ "GenMsgSendType" BO_ 2566771710 0;
BA_ "GenMsgCycleTime" BO_ 2566771710 1000;
BA_ "SAE_Document" BO_ 2566771710 "J1939-71";
BA_ "GenMsgSendType" BO_ 2566821886 0;
BA_ "GenMsgCycleTime" BO_ 2566821886 1000;
BA_ "SAE_Document" BO_ 2566821886 "J1939-71";
BA_ "GenMsgSendType" BO_ 2566822142 0;
BA_ "GenMsgCycleTime" BO_ 2566822142 1000;
BA_ "SAE_Document" BO_ 2566822142 "J1939-71";
BA_ "GenMsgSendType" BO_ 2566822398 0;
BA_ "GenMsgCycleTime" BO_ 2566822398 1000;
BA_ "SAE_Document" BO_ 2566822398 "J1939-71";
BA_ "GenMsgSendType" BO_ 2566822654 0;
BA_ "GenMsgCycleTime" BO_ 2566822654 1000;
BA_ "SAE_Document" BO_ 2566822654 "J1939-71";
BA_ "GenMsgSendType" BO_ 2633931774 0;
BA_ "GenMsgCycleTime" BO_ 2633931774 1000;
BA_ "SAE_Document" BO_ 2633931774 "J1939-71";
BA_ "SAE_Document" BO_ 2566802430 "J1939-71";
BA_ "SAE_Document" BO_ 2566841086 "J1939-71";
BA_ "GenMsgSendType" BO_ 2348941054 2;
BA_ "GenMsgCycleTime" BO_ 2348941054 50;
BA_ "SAE_Document" BO_ 2348941054 "J1939-71";
BA_ "GenMsgSendType" BO_ 2566839806 0;
BA_ "GenMsgCycleTime" BO_ 2566839806 1000;
BA_ "SAE_Document" BO_ 2566839806 "J1939-71";
BA_ "SAE_Document" BO_ 2633911806 "J1939-71";
BA_ "GenMsgSendType" BO_ 2566775550 2;
BA_ "GenMsgCycleTime" BO_ 2566775550 1000;
BA_ "SAE_Document" BO_ 2566775550 "J1939-71";
BA_ "GenMsgSendType" BO_ 2566819838 0;
BA_ "GenMsgCycleTime" BO_ 2566819838 1000;
BA_ "SAE_Document" BO_ 2566819838 "J1939-71";
BA_ "SAE_Document" BO_ 2566839038 "J1939-71";
BA_ "GenMsgSendType" BO_ 2566841598 0;
BA_ "GenMsgCycleTime" BO_ 2566841598 1000;
BA_ "SAE_Document" BO_ 2566841598 "J1939-71";
BA_ "SAE_Document" BO_ 2633895166 "J1939-81";
BA_ "SAE_Document" BO_ 2566832382 "J1939-71";
BA_ "SAE_Document" BO_ 2633928446 "J1939-71";
BA_ "GenMsgSendType" BO_ 2566804478 0;
BA_ "GenMsgCycleTime" BO_ 2566804478 5000;
BA_ "SAE_Document" BO_ 2566804478 "J1939-71";
BA_ "GenMsgSendType" BO_ 2566847486 0;
BA_ "GenMsgCycleTime" BO_ 2566847486 1000;
BA_ "SAE_Document" BO_ 2566847486 "J1939-71";
BA_ "SAE_Document" BO_ 2631859966 "J1939-71";
BA_ "GenMsgSendType" BO_ 2566840830 0;
BA_ "GenMsgCycleTime" BO_ 2566840830 5000;
BA_ "SAE_Document" BO_ 2566840830 "J1939-71";
BA_ "SAE_Document" BO_ 2633930238 "J1939-71";
BA_ "GenMsgSendType" BO_ 2566844670 0;
BA_ "GenMsgCycleTime" BO_ 2566844670 100;
BA_ "SAE_Document" BO_ 2566844670 "J1939-71";
BA_ "GenMsgSendType" BO_ 2566770174 0;
BA_ "GenMsgCycleTime" BO_ 2566770174 200;
BA_ "SAE_Document" BO_ 2566770174 "J1939-71";
BA_ "GenMsgSendType" BO_ 2566769662 0;
BA_ "GenMsgCycleTime" BO_ 2566769662 500;
BA_ "SAE_Document" BO_ 2566769662 "J1939-71";
BA_ "SigType" SG_ 2633938430 TripSuddenDecelerations 1;
BA_ "SPN" SG_ 2633938430 TripSuddenDecelerations 1023;
BA_ "SAEDocument" SG_ 2633938430 TripSuddenDecelerations "J1939-71";
BA_ "SigType" SG_ 2633938430 TrpNumberOfIdleShutdownOverrides 1;
BA_ "SPN" SG_ 2633938430 TrpNumberOfIdleShutdownOverrides 1022;
BA_ "SAEDocument" SG_ 2633938430 TrpNumberOfIdleShutdownOverrides "J1939-71";
BA_ "SigType" SG_ 2633938430 TripNumberOfIdleShutdowns 1;
BA_ "SPN" SG_ 2633938430 TripNumberOfIdleShutdowns 1021;
BA_ "SAEDocument" SG_ 2633938430 TripNumberOfIdleShutdowns "J1939-71";
BA_ "SigType" SG_ 2633938430 TripNumberOfHotShutdowns 1;
BA_ "SPN" SG_ 2633938430 TripNumberOfHotShutdowns 1020;
BA_ "SAEDocument" SG_ 2633938430 TripNumberOfHotShutdowns "J1939-71";
BA_ "SPN" SG_ 2348875518 MessageChecksum 4207;
BA_ "SAEDocument" SG_ 2348875518 MessageChecksum "J1939-71";
BA_ "SPN" SG_ 2348875518 MessageCounter 4206;
BA_ "SAEDocument" SG_ 2348875518 MessageCounter "J1939-71";
BA_ "SPN" SG_ 2348875518 EngRequestedTorqueHighResolution 4191;
BA_ "SAEDocument" SG_ 2348875518 EngRequestedTorqueHighResolution "J1939-71";
BA_ "SPN" SG_ 2348875518 TSC1CtrlPurpose 3350;
BA_ "SAEDocument" SG_ 2348875518 TSC1CtrlPurpose "J1939-71";
BA_ "SPN" SG_ 2348875518 TSC1TransRate 3349;
BA_ "SAEDocument" SG_ 2348875518 TSC1TransRate "J1939-71";
BA_ "SPN" SG_ 2348875518 EngRequestedTorque_TorqueLimit 518;
BA_ "SAEDocument" SG_ 2348875518 EngRequestedTorque_TorqueLimit "J1939-71";
BA_ "SPN" SG_ 2348875518 EngRequestedSpeed_SpeedLimit 898;
BA_ "SAEDocument" SG_ 2348875518 EngRequestedSpeed_SpeedLimit "J1939-71";
BA_ "SigType" SG_ 2348875518 OverrideCtrlModePriority 5;
BA_ "SPN" SG_ 2348875518 OverrideCtrlModePriority 897;
BA_ "SAEDocument" SG_ 2348875518 OverrideCtrlModePriority "J1939-71";
BA_ "SigType" SG_ 2348875518 EngRequestedSpeedCtrlConditions 5;
BA_ "SPN" SG_ 2348875518 EngRequestedSpeedCtrlConditions 696;
BA_ "SAEDocument" SG_ 2348875518 EngRequestedSpeedCtrlConditions "J1939-71";
BA_ "SigType" SG_ 2348875518 EngOverrideCtrlMode 5;
BA_ "SPN" SG_ 2348875518 EngOverrideCtrlMode 695;
BA_ "SAEDocument" SG_ 2348875518 EngOverrideCtrlMode "J1939-71";
BA_ "SigType" SG_ 2566766846 TransitRunStatus 5;
BA_ "SPN" SG_ 2566766846 TransitRunStatus 3046;
BA_ "SAEDocument" SG_ 2566766846 TransitRunStatus "J1939-71";
BA_ "SigType" SG_ 2566766846 VehicleUseStatus 5;
BA_ "SPN" SG_ 2566766846 VehicleUseStatus 3045;
BA_ "SAEDocument" SG_ 2566766846 VehicleUseStatus "J1939-71";
BA_ "SigType" SG_ 2566766846 SilentAlarmStatus 5;
BA_ "SPN" SG_ 2566766846 SilentAlarmStatus 3044;
BA_ "SAEDocument" SG_ 2566766846 SilentAlarmStatus "J1939-71";
BA_ "SigType" SG_ 2566766846 PatronCount 1;
BA_ "SPN" SG_ 2566766846 PatronCount 3047;
BA_ "SAEDocument" SG_ 2566766846 PatronCount "J1939-71";
BA_ "SigType" SG_ 2566766846 TypeOfPassengerCount 1;
BA_ "SPN" SG_ 2566766846 TypeOfPassengerCount 3043;
BA_ "SAEDocument" SG_ 2566766846 TypeOfPassengerCount "J1939-71";
BA_ "SPN" SG_ 2566765310 FareboxAlarmIdentifier 3181;
BA_ "SAEDocument" SG_ 2566765310 FareboxAlarmIdentifier "J1939-71";
BA_ "SigType" SG_ 2566765310 FareboxEmergencyStatus 4;
BA_ "SPN" SG_ 2566765310 FareboxEmergencyStatus 3179;
BA_ "SAEDocument" SG_ 2566765310 FareboxEmergencyStatus "J1939-71";
BA_ "SigType" SG_ 2566765566 TransferSold 1;
BA_ "SPN" SG_ 2566765566 TransferSold 3168;
BA_ "SAEDocument" SG_ 2566765566 TransferSold "J1939-71";
BA_ "SPN" SG_ 2566765566 RouteNumber 3169;
BA_ "SAEDocument" SG_ 2566765566 RouteNumber "J1939-71";
BA_ "SPN" SG_ 2566765566 TransferType 3173;
BA_ "SAEDocument" SG_ 2566765566 TransferType "J1939-71";
BA_ "SPN" SG_ 2566765566 TypeOfService 3172;
BA_ "SAEDocument" SG_ 2566765566 TypeOfService "J1939-71";
BA_ "SPN" SG_ 2566765566 InitialFareAgency 3167;
BA_ "SAEDocument" SG_ 2566765566 InitialFareAgency "J1939-71";
BA_ "SPN" SG_ 2566765566 PassCategory 3166;
BA_ "SAEDocument" SG_ 2566765566 PassCategory "J1939-71";
BA_ "SPN" SG_ 2566765566 FareValidity 3165;
BA_ "SAEDocument" SG_ 2566765566 FareValidity "J1939-71";
BA_ "SPN" SG_ 2566765566 PaymentDetails 3177;
BA_ "SAEDocument" SG_ 2566765566 PaymentDetails "J1939-71";
BA_ "SPN" SG_ 2566765566 TypeOfFare 3176;
BA_ "SAEDocument" SG_ 2566765566 TypeOfFare "J1939-71";
BA_ "SPN" SG_ 2566765566 PassengerType 3171;
BA_ "SAEDocument" SG_ 2566765566 PassengerType "J1939-71";
BA_ "SPN" SG_ 2566765566 TransactionType 3170;
BA_ "SAEDocument" SG_ 2566765566 TransactionType "J1939-71";
BA_ "SigType" SG_ 2566765822 DriversFareboxSecurityCode 1;
BA_ "SPN" SG_ 2566765822 DriversFareboxSecurityCode 3164;
BA_ "SAEDocument" SG_ 2566765822 DriversFareboxSecurityCode "J1939-71";
BA_ "SigType" SG_ 2566765822 AssignedBlock 1;
BA_ "SPN" SG_ 2566765822 AssignedBlock 3163;
BA_ "SAEDocument" SG_ 2566765822 AssignedBlock "J1939-71";
BA_ "SigType" SG_ 2566765822 AssignedRun 1;
BA_ "SPN" SG_ 2566765822 AssignedRun 3162;
BA_ "SAEDocument" SG_ 2566765822 AssignedRun "J1939-71";
BA_ "SigType" SG_ 2566765822 AssignedRoute 1;
BA_ "SPN" SG_ 2566765822 AssignedRoute 3160;
BA_ "SAEDocument" SG_ 2566765822 AssignedRoute "J1939-71";
BA_ "SigType" SG_ 2566765822 PatternNumber 1;
BA_ "SPN" SG_ 2566765822 PatternNumber 3161;
BA_ "SAEDocument" SG_ 2566765822 PatternNumber "J1939-71";
BA_ "SigType" SG_ 2566765822 TripNumber 1;
BA_ "SPN" SG_ 2566765822 TripNumber 3159;
BA_ "SAEDocument" SG_ 2566765822 TripNumber "J1939-71";
BA_ "SigType" SG_ 2566765822 FarePresets 1;
BA_ "SPN" SG_ 2566765822 FarePresets 3175;
BA_ "SAEDocument" SG_ 2566765822 FarePresets "J1939-71";
BA_ "SPN" SG_ 2566765822 TripDirection 3174;
BA_ "SAEDocument" SG_ 2566765822 TripDirection "J1939-71";
BA_ "SPN" SG_ 2566765822 TripStatus 3180;
BA_ "SAEDocument" SG_ 2566765822 TripStatus "J1939-71";
BA_ "SigType" SG_ 2566765822 FareboxServiceStatus 4;
BA_ "SPN" SG_ 2566765822 FareboxServiceStatus 3178;
BA_ "SAEDocument" SG_ 2566765822 FareboxServiceStatus "J1939-71";
BA_ "SigType" SG_ 2566766078 VehicleID 1;
BA_ "SPN" SG_ 2566766078 VehicleID 3085;
BA_ "SAEDocument" SG_ 2566766078 VehicleID "J1939-71";
BA_ "SigType" SG_ 2566766078 StrobeActivationCtrlStatus 4;
BA_ "SPN" SG_ 2566766078 StrobeActivationCtrlStatus 3082;
BA_ "SAEDocument" SG_ 2566766078 StrobeActivationCtrlStatus "J1939-71";
BA_ "SigType" SG_ 2566766078 TransitDoorEnable 4;
BA_ "SPN" SG_ 2566766078 TransitDoorEnable 3083;
BA_ "SAEDocument" SG_ 2566766078 TransitDoorEnable "J1939-71";
BA_ "SPN" SG_ 2566766078 PriorityOfRespSentByEmitter 3084;
BA_ "SAEDocument" SG_ 2566766078 PriorityOfRespSentByEmitter "J1939-71";
BA_ "SigType" SG_ 2566766078 IntrsctnPrmptionRequest_Response 4;
BA_ "SPN" SG_ 2566766078 IntrsctnPrmptionRequest_Response 3079;
BA_ "SAEDocument" SG_ 2566766078 IntrsctnPrmptionRequest_Response "J1939-71";
BA_ "SigType" SG_ 2566766078 TransitRouteIDUsage 4;
BA_ "SPN" SG_ 2566766078 TransitRouteIDUsage 3080;
BA_ "SAEDocument" SG_ 2566766078 TransitRouteIDUsage "J1939-71";
BA_ "SigType" SG_ 2566766078 RangeCodeEnable 4;
BA_ "SPN" SG_ 2566766078 RangeCodeEnable 3081;
BA_ "SAEDocument" SG_ 2566766078 RangeCodeEnable "J1939-71";
BA_ "SigType" SG_ 2566766590 NmbrOfBytsInThMlpstIdntification 1;
BA_ "SPN" SG_ 2566766590 NmbrOfBytsInThMlpstIdntification 3070;
BA_ "SAEDocument" SG_ 2566766590 NmbrOfBytsInThMlpstIdntification "J1939-71";
BA_ "SigType" SG_ 2566766334 NmbrOfBytsInThTrnstAssgndBlckIdn 1;
BA_ "SPN" SG_ 2566766334 NmbrOfBytsInThTrnstAssgndBlckIdn 3073;
BA_ "SAEDocument" SG_ 2566766334 NmbrOfBytsInThTrnstAssgndBlckIdn "J1939-71";
BA_ "SigType" SG_ 2566766334 NmbrOfBytsInThTrnstAssgndRnIdntt 1;
BA_ "SPN" SG_ 2566766334 NmbrOfBytsInThTrnstAssgndRnIdntt 3072;
BA_ "SAEDocument" SG_ 2566766334 NmbrOfBytsInThTrnstAssgndRnIdntt "J1939-71";
BA_ "SigType" SG_ 2566766334 NmbrOfBytsInThTrnstAssgndRtIdntt 1;
BA_ "SPN" SG_ 2566766334 NmbrOfBytsInThTrnstAssgndRtIdntt 3071;
BA_ "SAEDocument" SG_ 2566766334 NmbrOfBytsInThTrnstAssgndRtIdntt "J1939-71";
BA_ "SigType" SG_ 2566766334 Agency 1;
BA_ "SPN" SG_ 2566766334 Agency 3078;
BA_ "SAEDocument" SG_ 2566766334 Agency "J1939-71";
BA_ "SigType" SG_ 2561605374 ReferenceTirePressSetting_33 1;
BA_ "SPN" SG_ 2561605374 ReferenceTirePressSetting_33 521833;
BA_ "SigType" SG_ 2561605374 ReferenceTirePressSetting_32 1;
BA_ "SPN" SG_ 2561605374 ReferenceTirePressSetting_32 521832;
BA_ "SigType" SG_ 2561605374 ReferenceTirePressSetting_31 1;
BA_ "SPN" SG_ 2561605374 ReferenceTirePressSetting_31 521831;
BA_ "SigType" SG_ 2561605374 ReferenceTirePressSetting_30 1;
BA_ "SPN" SG_ 2561605374 ReferenceTirePressSetting_30 521830;
BA_ "SigType" SG_ 2561605374 ReferenceTirePressSetting_23 1;
BA_ "SPN" SG_ 2561605374 ReferenceTirePressSetting_23 521823;
BA_ "SigType" SG_ 2561605374 ReferenceTirePressSetting_22 1;
BA_ "SPN" SG_ 2561605374 ReferenceTirePressSetting_22 521822;
BA_ "SigType" SG_ 2561605374 ReferenceTirePressSetting_21 1;
BA_ "SPN" SG_ 2561605374 ReferenceTirePressSetting_21 521821;
BA_ "SigType" SG_ 2561605374 ReferenceTirePressSetting_20 1;
BA_ "SPN" SG_ 2561605374 ReferenceTirePressSetting_20 521820;
BA_ "SigType" SG_ 2561605374 ReferenceTirePressSetting_13 1;
BA_ "SPN" SG_ 2561605374 ReferenceTirePressSetting_13 521813;
BA_ "SigType" SG_ 2561605374 ReferenceTirePressSetting_12 1;
BA_ "SPN" SG_ 2561605374 ReferenceTirePressSetting_12 521812;
BA_ "SigType" SG_ 2561605374 ReferenceTirePressSetting_11 1;
BA_ "SPN" SG_ 2561605374 ReferenceTirePressSetting_11 521811;
BA_ "SigType" SG_ 2561605374 ReferenceTirePressSetting_10 1;
BA_ "SPN" SG_ 2561605374 ReferenceTirePressSetting_10 521810;
BA_ "SigType" SG_ 2561605374 ReferenceTirePressSetting_01 1;
BA_ "SPN" SG_ 2561605374 ReferenceTirePressSetting_01 521801;
BA_ "SigType" SG_ 2561605374 ReferenceTirePressSetting_00 1;
BA_ "SPN" SG_ 2561605374 ReferenceTirePressSetting_00 521800;
BA_ "SigType" SG_ 2561605374 TireLocation 1;
BA_ "SPN" SG_ 2561605374 TireLocation 3190;
BA_ "SAEDocument" SG_ 2561605374 TireLocation "J1939-71";
BA_ "SigType" SG_ 2566765054 ReferenceTirePress_33 1;
BA_ "SPN" SG_ 2566765054 ReferenceTirePress_33 521933;
BA_ "SigType" SG_ 2566765054 ReferenceTirePress_32 1;
BA_ "SPN" SG_ 2566765054 ReferenceTirePress_32 521932;
BA_ "SigType" SG_ 2566765054 ReferenceTirePress_31 1;
BA_ "SPN" SG_ 2566765054 ReferenceTirePress_31 521931;
BA_ "SigType" SG_ 2566765054 ReferenceTirePress_30 1;
BA_ "SPN" SG_ 2566765054 ReferenceTirePress_30 521930;
BA_ "SigType" SG_ 2566765054 ReferenceTirePress_23 1;
BA_ "SPN" SG_ 2566765054 ReferenceTirePress_23 521923;
BA_ "SigType" SG_ 2566765054 ReferenceTirePress_22 1;
BA_ "SPN" SG_ 2566765054 ReferenceTirePress_22 521922;
BA_ "SigType" SG_ 2566765054 ReferenceTirePress_21 1;
BA_ "SPN" SG_ 2566765054 ReferenceTirePress_21 521921;
BA_ "SigType" SG_ 2566765054 ReferenceTirePress_20 1;
BA_ "SPN" SG_ 2566765054 ReferenceTirePress_20 521920;
BA_ "SigType" SG_ 2566765054 ReferenceTirePress_13 1;
BA_ "SPN" SG_ 2566765054 ReferenceTirePress_13 521913;
BA_ "SigType" SG_ 2566765054 ReferenceTirePress_12 1;
BA_ "SPN" SG_ 2566765054 ReferenceTirePress_12 521912;
BA_ "SigType" SG_ 2566765054 ReferenceTirePress_11 1;
BA_ "SPN" SG_ 2566765054 ReferenceTirePress_11 521911;
BA_ "SigType" SG_ 2566765054 ReferenceTirePress_10 1;
BA_ "SPN" SG_ 2566765054 ReferenceTirePress_10 521910;
BA_ "SigType" SG_ 2566765054 ReferenceTirePress_01 1;
BA_ "SPN" SG_ 2566765054 ReferenceTirePress_01 521901;
BA_ "SigType" SG_ 2566765054 ReferenceTirePress_00 1;
BA_ "SPN" SG_ 2566765054 ReferenceTirePress_00 521900;
BA_ "SigType" SG_ 2566765054 TireLocation 1;
BA_ "SPN" SG_ 2566765054 TireLocation 3190;
BA_ "SAEDocument" SG_ 2566765054 TireLocation "J1939-71";
BA_ "SigType" SG_ 2633923326 SteerChannelTirePress 1;
BA_ "SPN" SG_ 2633923326 SteerChannelTirePress 146;
BA_ "SAEDocument" SG_ 2633923326 SteerChannelTirePress "J1939-71";
BA_ "SigType" SG_ 2633923326 DriveChannelTirePress 1;
BA_ "SPN" SG_ 2633923326 DriveChannelTirePress 145;
BA_ "SAEDocument" SG_ 2633923326 DriveChannelTirePress "J1939-71";
BA_ "SigType" SG_ 2633923326 TrailerTagOrPushChannelTirePress 1;
BA_ "SPN" SG_ 2633923326 TrailerTagOrPushChannelTirePress 144;
BA_ "SAEDocument" SG_ 2633923326 TrailerTagOrPushChannelTirePress "J1939-71";
BA_ "SigType" SG_ 2633923070 SteerChannelTirePressTarget 1;
BA_ "SPN" SG_ 2633923070 SteerChannelTirePressTarget 143;
BA_ "SAEDocument" SG_ 2633923070 SteerChannelTirePressTarget "J1939-71";
BA_ "SigType" SG_ 2633923070 DriveChannelTirePressTarget 1;
BA_ "SPN" SG_ 2633923070 DriveChannelTirePressTarget 142;
BA_ "SAEDocument" SG_ 2633923070 DriveChannelTirePressTarget "J1939-71";
BA_ "SigType" SG_ 2633923070 TrlrTgOrPshChnnelTirePressTarget 1;
BA_ "SPN" SG_ 2633923070 TrlrTgOrPshChnnelTirePressTarget 141;
BA_ "SAEDocument" SG_ 2633923070 TrlrTgOrPshChnnelTirePressTarget "J1939-71";
BA_ "SigType" SG_ 2633922814 PCUTrilerTagOrPushSolenoidStatus 5;
BA_ "SPN" SG_ 2633922814 PCUTrilerTagOrPushSolenoidStatus 1475;
BA_ "SAEDocument" SG_ 2633922814 PCUTrilerTagOrPushSolenoidStatus "J1939-71";
BA_ "SigType" SG_ 2633922814 PCUSupplySolenoidStatus 5;
BA_ "SPN" SG_ 2633922814 PCUSupplySolenoidStatus 1474;
BA_ "SAEDocument" SG_ 2633922814 PCUSupplySolenoidStatus "J1939-71";
BA_ "SigType" SG_ 2633922814 PCUCtrlSolenoidStatus 5;
BA_ "SPN" SG_ 2633922814 PCUCtrlSolenoidStatus 1473;
BA_ "SAEDocument" SG_ 2633922814 PCUCtrlSolenoidStatus "J1939-71";
BA_ "SigType" SG_ 2633922814 PCUDeflateSolenoidStatus 5;
BA_ "SPN" SG_ 2633922814 PCUDeflateSolenoidStatus 1472;
BA_ "SAEDocument" SG_ 2633922814 PCUDeflateSolenoidStatus "J1939-71";
BA_ "SigType" SG_ 2633922814 TirePressSupplySwitchStatus 5;
BA_ "SPN" SG_ 2633922814 TirePressSupplySwitchStatus 1471;
BA_ "SAEDocument" SG_ 2633922814 TirePressSupplySwitchStatus "J1939-71";
BA_ "SigType" SG_ 2633922814 PCUSteerSolenoidStatus 5;
BA_ "SPN" SG_ 2633922814 PCUSteerSolenoidStatus 1470;
BA_ "SAEDocument" SG_ 2633922814 PCUSteerSolenoidStatus "J1939-71";
BA_ "SigType" SG_ 2633922814 PCUDriveSolenoidStatus 5;
BA_ "SPN" SG_ 2633922814 PCUDriveSolenoidStatus 1469;
BA_ "SAEDocument" SG_ 2633922814 PCUDriveSolenoidStatus "J1939-71";
BA_ "SPN" SG_ 2633922814 DriveChannelMode 1468;
BA_ "SAEDocument" SG_ 2633922814 DriveChannelMode "J1939-71";
BA_ "SPN" SG_ 2633922814 Trailer_tagChannelMode 1467;
BA_ "SAEDocument" SG_ 2633922814 Trailer_tagChannelMode "J1939-71";
BA_ "SPN" SG_ 2633922814 SteerChannelMode 1466;
BA_ "SAEDocument" SG_ 2633922814 SteerChannelMode "J1939-71";
BA_ "SPN" SG_ 2633922814 TirePressCheckInterval 39;
BA_ "SAEDocument" SG_ 2633922814 TirePressCheckInterval "J1939-71";
BA_ "SPN" SG_ 2566845694 TirePressThresholdDetection_13 521613;
BA_ "SPN" SG_ 2566845694 TirePressThresholdDetection_12 521612;
BA_ "SPN" SG_ 2566845694 TirePressThresholdDetection_11 521611;
BA_ "SPN" SG_ 2566845694 TirePressThresholdDetection_10 521610;
BA_ "SPN" SG_ 2566845694 TirePressThresholdDetection_01 521601;
BA_ "SigType" SG_ 2566845694 TirePress_33 1;
BA_ "SPN" SG_ 2566845694 TirePress_33 521033;
BA_ "SigType" SG_ 2566845694 TirePress_32 1;
BA_ "SPN" SG_ 2566845694 TirePress_32 521032;
BA_ "SigType" SG_ 2566845694 TirePress_31 1;
BA_ "SPN" SG_ 2566845694 TirePress_31 521031;
BA_ "SigType" SG_ 2566845694 TirePress_30 1;
BA_ "SPN" SG_ 2566845694 TirePress_30 521030;
BA_ "SigType" SG_ 2566845694 TirePress_23 1;
BA_ "SPN" SG_ 2566845694 TirePress_23 521023;
BA_ "SigType" SG_ 2566845694 TirePress_22 1;
BA_ "SPN" SG_ 2566845694 TirePress_22 521022;
BA_ "SigType" SG_ 2566845694 TirePress_21 1;
BA_ "SPN" SG_ 2566845694 TirePress_21 521021;
BA_ "SigType" SG_ 2566845694 TirePress_20 1;
BA_ "SPN" SG_ 2566845694 TirePress_20 521020;
BA_ "SigType" SG_ 2566845694 TirePress_13 1;
BA_ "SPN" SG_ 2566845694 TirePress_13 521013;
BA_ "SigType" SG_ 2566845694 TirePress_12 1;
BA_ "SPN" SG_ 2566845694 TirePress_12 521012;
BA_ "SigType" SG_ 2566845694 TirePress_11 1;
BA_ "SPN" SG_ 2566845694 TirePress_11 521011;
BA_ "SigType" SG_ 2566845694 TirePress_10 1;
BA_ "SPN" SG_ 2566845694 TirePress_10 521010;
BA_ "SigType" SG_ 2566845694 TireAirLeakageRate_33 1;
BA_ "SPN" SG_ 2566845694 TireAirLeakageRate_33 521533;
BA_ "SigType" SG_ 2566845694 TireAirLeakageRate_32 1;
BA_ "SPN" SG_ 2566845694 TireAirLeakageRate_32 521532;
BA_ "SigType" SG_ 2566845694 TireAirLeakageRate_31 1;
BA_ "SPN" SG_ 2566845694 TireAirLeakageRate_31 521531;
BA_ "SigType" SG_ 2566845694 TireAirLeakageRate_30 1;
BA_ "SPN" SG_ 2566845694 TireAirLeakageRate_30 521530;
BA_ "SigType" SG_ 2566845694 TireAirLeakageRate_23 1;
BA_ "SPN" SG_ 2566845694 TireAirLeakageRate_23 521523;
BA_ "SigType" SG_ 2566845694 TireAirLeakageRate_22 1;
BA_ "SPN" SG_ 2566845694 TireAirLeakageRate_22 521522;
BA_ "SigType" SG_ 2566845694 TireAirLeakageRate_21 1;
BA_ "SPN" SG_ 2566845694 TireAirLeakageRate_21 521521;
BA_ "SigType" SG_ 2566845694 TireAirLeakageRate_20 1;
BA_ "SPN" SG_ 2566845694 TireAirLeakageRate_20 521520;
BA_ "SigType" SG_ 2566845694 TireAirLeakageRate_13 1;
BA_ "SPN" SG_ 2566845694 TireAirLeakageRate_13 521513;
BA_ "SigType" SG_ 2566845694 TireAirLeakageRate_12 1;
BA_ "SPN" SG_ 2566845694 TireAirLeakageRate_12 521512;
BA_ "SigType" SG_ 2566845694 TireAirLeakageRate_11 1;
BA_ "SPN" SG_ 2566845694 TireAirLeakageRate_11 521511;
BA_ "SigType" SG_ 2566845694 TireAirLeakageRate_10 1;
BA_ "SPN" SG_ 2566845694 TireAirLeakageRate_10 521510;
BA_ "SigType" SG_ 2566845694 TireAirLeakageRate_01 1;
BA_ "SPN" SG_ 2566845694 TireAirLeakageRate_01 521501;
BA_ "SigType" SG_ 2566845694 TireAirLeakageRate_00 1;
BA_ "SPN" SG_ 2566845694 TireAirLeakageRate_00 521500;
BA_ "SigType" SG_ 2566845694 CTIWheelSensorStatus_33 4;
BA_ "SPN" SG_ 2566845694 CTIWheelSensorStatus_33 521433;
BA_ "SigType" SG_ 2566845694 CTIWheelSensorStatus_32 4;
BA_ "SPN" SG_ 2566845694 CTIWheelSensorStatus_32 521432;
BA_ "SigType" SG_ 2566845694 CTIWheelSensorStatus_31 4;
BA_ "SPN" SG_ 2566845694 CTIWheelSensorStatus_31 521431;
BA_ "SigType" SG_ 2566845694 CTIWheelSensorStatus_30 4;
BA_ "SPN" SG_ 2566845694 CTIWheelSensorStatus_30 521430;
BA_ "SigType" SG_ 2566845694 CTIWheelSensorStatus_23 4;
BA_ "SPN" SG_ 2566845694 CTIWheelSensorStatus_23 521423;
BA_ "SigType" SG_ 2566845694 CTIWheelSensorStatus_22 4;
BA_ "SPN" SG_ 2566845694 CTIWheelSensorStatus_22 521422;
BA_ "SigType" SG_ 2566845694 CTIWheelSensorStatus_21 4;
BA_ "SPN" SG_ 2566845694 CTIWheelSensorStatus_21 521421;
BA_ "SigType" SG_ 2566845694 CTIWheelSensorStatus_20 4;
BA_ "SPN" SG_ 2566845694 CTIWheelSensorStatus_20 521420;
BA_ "SigType" SG_ 2566845694 CTIWheelSensorStatus_13 4;
BA_ "SPN" SG_ 2566845694 CTIWheelSensorStatus_13 521413;
BA_ "SigType" SG_ 2566845694 CTIWheelSensorStatus_12 4;
BA_ "SPN" SG_ 2566845694 CTIWheelSensorStatus_12 521412;
BA_ "SigType" SG_ 2566845694 CTIWheelSensorStatus_11 4;
BA_ "SPN" SG_ 2566845694 CTIWheelSensorStatus_11 521411;
BA_ "SigType" SG_ 2566845694 CTIWheelSensorStatus_10 4;
BA_ "SPN" SG_ 2566845694 CTIWheelSensorStatus_10 521410;
BA_ "SigType" SG_ 2566845694 CTIWheelSensorStatus_01 4;
BA_ "SPN" SG_ 2566845694 CTIWheelSensorStatus_01 521401;
BA_ "SigType" SG_ 2566845694 CTIWheelEndElectricalFault_33 4;
BA_ "SPN" SG_ 2566845694 CTIWheelEndElectricalFault_33 521233;
BA_ "SigType" SG_ 2566845694 CTIWheelEndElectricalFault_32 4;
BA_ "SPN" SG_ 2566845694 CTIWheelEndElectricalFault_32 521232;
BA_ "SigType" SG_ 2566845694 CTIWheelEndElectricalFault_31 4;
BA_ "SPN" SG_ 2566845694 CTIWheelEndElectricalFault_31 521231;
BA_ "SigType" SG_ 2566845694 CTIWheelEndElectricalFault_30 4;
BA_ "SPN" SG_ 2566845694 CTIWheelEndElectricalFault_30 521230;
BA_ "SigType" SG_ 2566845694 CTIWheelEndElectricalFault_23 4;
BA_ "SPN" SG_ 2566845694 CTIWheelEndElectricalFault_23 521223;
BA_ "SigType" SG_ 2566845694 CTIWheelEndElectricalFault_22 4;
BA_ "SPN" SG_ 2566845694 CTIWheelEndElectricalFault_22 521222;
BA_ "SigType" SG_ 2566845694 CTIWheelEndElectricalFault_21 4;
BA_ "SPN" SG_ 2566845694 CTIWheelEndElectricalFault_21 521221;
BA_ "SigType" SG_ 2566845694 CTIWheelEndElectricalFault_20 4;
BA_ "SPN" SG_ 2566845694 CTIWheelEndElectricalFault_20 521220;
BA_ "SigType" SG_ 2566845694 CTIWheelEndElectricalFault_13 4;
BA_ "SPN" SG_ 2566845694 CTIWheelEndElectricalFault_13 521213;
BA_ "SigType" SG_ 2566845694 CTIWheelEndElectricalFault_12 4;
BA_ "SPN" SG_ 2566845694 CTIWheelEndElectricalFault_12 521212;
BA_ "SigType" SG_ 2566845694 CTIWheelEndElectricalFault_11 4;
BA_ "SPN" SG_ 2566845694 CTIWheelEndElectricalFault_11 521211;
BA_ "SigType" SG_ 2566845694 CTIWheelEndElectricalFault_10 4;
BA_ "SPN" SG_ 2566845694 CTIWheelEndElectricalFault_10 521210;
BA_ "SigType" SG_ 2566845694 CTIWheelEndElectricalFault_01 4;
BA_ "SPN" SG_ 2566845694 CTIWheelEndElectricalFault_01 521201;
BA_ "SigType" SG_ 2566845694 CTITireStatus_33 4;
BA_ "SPN" SG_ 2566845694 CTITireStatus_33 521333;
BA_ "SigType" SG_ 2566845694 CTITireStatus_32 4;
BA_ "SPN" SG_ 2566845694 CTITireStatus_32 521332;
BA_ "SigType" SG_ 2566845694 CTITireStatus_31 4;
BA_ "SPN" SG_ 2566845694 CTITireStatus_31 521331;
BA_ "SigType" SG_ 2566845694 CTITireStatus_30 4;
BA_ "SPN" SG_ 2566845694 CTITireStatus_30 521330;
BA_ "SigType" SG_ 2566845694 CTITireStatus_23 4;
BA_ "SPN" SG_ 2566845694 CTITireStatus_23 521323;
BA_ "SigType" SG_ 2566845694 CTITireStatus_22 4;
BA_ "SPN" SG_ 2566845694 CTITireStatus_22 521322;
BA_ "SigType" SG_ 2566845694 CTITireStatus_21 4;
BA_ "SPN" SG_ 2566845694 CTITireStatus_21 521321;
BA_ "SigType" SG_ 2566845694 CTITireStatus_20 4;
BA_ "SPN" SG_ 2566845694 CTITireStatus_20 521320;
BA_ "SigType" SG_ 2566845694 CTITireStatus_13 4;
BA_ "SPN" SG_ 2566845694 CTITireStatus_13 521313;
BA_ "SigType" SG_ 2566845694 CTITireStatus_12 4;
BA_ "SPN" SG_ 2566845694 CTITireStatus_12 521312;
BA_ "SigType" SG_ 2566845694 CTITireStatus_11 4;
BA_ "SPN" SG_ 2566845694 CTITireStatus_11 521311;
BA_ "SigType" SG_ 2566845694 CTITireStatus_10 4;
BA_ "SPN" SG_ 2566845694 CTITireStatus_10 521310;
BA_ "SigType" SG_ 2566845694 CTITireStatus_01 4;
BA_ "SPN" SG_ 2566845694 CTITireStatus_01 521301;
BA_ "SigType" SG_ 2566845694 TireTemp_11 1;
BA_ "SPN" SG_ 2566845694 TireTemp_11 521111;
BA_ "SigType" SG_ 2566845694 TireTemp_33 1;
BA_ "SPN" SG_ 2566845694 TireTemp_33 521133;
BA_ "SigType" SG_ 2566845694 TireTemp_32 1;
BA_ "SPN" SG_ 2566845694 TireTemp_32 521132;
BA_ "SigType" SG_ 2566845694 TireTemp_31 1;
BA_ "SPN" SG_ 2566845694 TireTemp_31 521131;
BA_ "SigType" SG_ 2566845694 TireTemp_30 1;
BA_ "SPN" SG_ 2566845694 TireTemp_30 521130;
BA_ "SigType" SG_ 2566845694 TireTemp_23 1;
BA_ "SPN" SG_ 2566845694 TireTemp_23 521123;
BA_ "SigType" SG_ 2566845694 TireTemp_22 1;
BA_ "SPN" SG_ 2566845694 TireTemp_22 521122;
BA_ "SigType" SG_ 2566845694 TireTemp_21 1;
BA_ "SPN" SG_ 2566845694 TireTemp_21 521121;
BA_ "SigType" SG_ 2566845694 TireTemp_20 1;
BA_ "SPN" SG_ 2566845694 TireTemp_20 521120;
BA_ "SigType" SG_ 2566845694 TireTemp_13 1;
BA_ "SPN" SG_ 2566845694 TireTemp_13 521113;
BA_ "SigType" SG_ 2566845694 TireTemp_12 1;
BA_ "SPN" SG_ 2566845694 TireTemp_12 521112;
BA_ "SigType" SG_ 2566845694 TireTemp_10 1;
BA_ "SPN" SG_ 2566845694 TireTemp_10 521110;
BA_ "SigType" SG_ 2566845694 TireTemp_01 1;
BA_ "SPN" SG_ 2566845694 TireTemp_01 521101;
BA_ "SigType" SG_ 2566845694 TireTemp_00 1;
BA_ "SPN" SG_ 2566845694 TireTemp_00 521100;
BA_ "SPN" SG_ 2566845694 TirePressThresholdDetection_33 521633;
BA_ "SPN" SG_ 2566845694 TirePressThresholdDetection_32 521632;
BA_ "SPN" SG_ 2566845694 TirePressThresholdDetection_31 521631;
BA_ "SPN" SG_ 2566845694 TirePressThresholdDetection_30 521630;
BA_ "SPN" SG_ 2566845694 TirePressThresholdDetection_23 521623;
BA_ "SPN" SG_ 2566845694 TirePressThresholdDetection_22 521622;
BA_ "SPN" SG_ 2566845694 TirePressThresholdDetection_21 521621;
BA_ "SPN" SG_ 2566845694 TirePressThresholdDetection_20 521620;
BA_ "SPN" SG_ 2566845694 TirePressThresholdDetection_00 521600;
BA_ "SigType" SG_ 2566845694 TirePress_01 1;
BA_ "SPN" SG_ 2566845694 TirePress_01 521001;
BA_ "SigType" SG_ 2566845694 TirePress_00 1;
BA_ "SPN" SG_ 2566845694 TirePress_00 521000;
BA_ "SigType" SG_ 2566845694 CTIWheelSensorStatus_00 4;
BA_ "SPN" SG_ 2566845694 CTIWheelSensorStatus_00 521400;
BA_ "SigType" SG_ 2566845694 CTIWheelEndElectricalFault_00 4;
BA_ "SPN" SG_ 2566845694 CTIWheelEndElectricalFault_00 521200;
BA_ "SigType" SG_ 2566845694 CTITireStatus_00 4;
BA_ "SPN" SG_ 2566845694 CTITireStatus_00 521300;
BA_ "SigType" SG_ 2566845694 TireLocation 1;
BA_ "SPN" SG_ 2566845694 TireLocation 929;
BA_ "SAEDocument" SG_ 2566845694 TireLocation "J1939-71";
BA_ "SigType" SG_ 2633939966 TripFanOnTimeDueToAManualSwitch 1;
BA_ "SPN" SG_ 2633939966 TripFanOnTimeDueToAManualSwitch 996;
BA_ "SAEDocument" SG_ 2633939966 TripFanOnTimeDueToAManualSwitch "J1939-71";
BA_ "SigType" SG_ 2633939966 TripFanOnTime 1;
BA_ "SPN" SG_ 2633939966 TripFanOnTime 994;
BA_ "SAEDocument" SG_ 2633939966 TripFanOnTime "J1939-71";
BA_ "SigType" SG_ 2633939966 TripFanOnTimeDueToTheA_CSystem 1;
BA_ "SPN" SG_ 2633939966 TripFanOnTimeDueToTheA_CSystem 997;
BA_ "SAEDocument" SG_ 2633939966 TripFanOnTimeDueToTheA_CSystem "J1939-71";
BA_ "SigType" SG_ 2633939966 TripFanOnTimeDueToTheEngSystem 1;
BA_ "SPN" SG_ 2633939966 TripFanOnTimeDueToTheEngSystem 995;
BA_ "SAEDocument" SG_ 2633939966 TripFanOnTimeDueToTheEngSystem "J1939-71";
BA_ "SigType" SG_ 2633939710 TripDistanceInTopGear 1;
BA_ "SPN" SG_ 2633939710 TripDistanceInTopGear 1000;
BA_ "SAEDocument" SG_ 2633939710 TripDistanceInTopGear "J1939-71";
BA_ "SigType" SG_ 2633939710 TripGearDownDistance 1;
BA_ "SPN" SG_ 2633939710 TripGearDownDistance 999;
BA_ "SAEDocument" SG_ 2633939710 TripGearDownDistance "J1939-71";
BA_ "SigType" SG_ 2633939710 TripDistanceOnVSL 1;
BA_ "SPN" SG_ 2633939710 TripDistanceOnVSL 998;
BA_ "SAEDocument" SG_ 2633939710 TripDistanceOnVSL "J1939-71";
BA_ "SigType" SG_ 2564161278 AdjustLocalHourOffset 1;
BA_ "SPN" SG_ 2564161278 AdjustLocalHourOffset 1610;
BA_ "SAEDocument" SG_ 2564161278 AdjustLocalHourOffset "J1939-71";
BA_ "SigType" SG_ 2564161278 AdjustLocalMinuteOffset 1;
BA_ "SPN" SG_ 2564161278 AdjustLocalMinuteOffset 1609;
BA_ "SAEDocument" SG_ 2564161278 AdjustLocalMinuteOffset "J1939-71";
BA_ "SigType" SG_ 2564161278 AdjustYear 1;
BA_ "SPN" SG_ 2564161278 AdjustYear 1608;
BA_ "SAEDocument" SG_ 2564161278 AdjustYear "J1939-71";
BA_ "SigType" SG_ 2564161278 AdjustDay 1;
BA_ "SPN" SG_ 2564161278 AdjustDay 1607;
BA_ "SAEDocument" SG_ 2564161278 AdjustDay "J1939-71";
BA_ "SigType" SG_ 2564161278 AdjustMonth 1;
BA_ "SPN" SG_ 2564161278 AdjustMonth 1606;
BA_ "SAEDocument" SG_ 2564161278 AdjustMonth "J1939-71";
BA_ "SigType" SG_ 2564161278 AdjustHours 1;
BA_ "SPN" SG_ 2564161278 AdjustHours 1605;
BA_ "SAEDocument" SG_ 2564161278 AdjustHours "J1939-71";
BA_ "SigType" SG_ 2564161278 AdjustMinutes 1;
BA_ "SPN" SG_ 2564161278 AdjustMinutes 1604;
BA_ "SAEDocument" SG_ 2564161278 AdjustMinutes "J1939-71";
BA_ "SigType" SG_ 2564161278 AdjustSeconds 1;
BA_ "SPN" SG_ 2564161278 AdjustSeconds 1603;
BA_ "SAEDocument" SG_ 2564161278 AdjustSeconds "J1939-71";
BA_ "SigType" SG_ 2566842110 LocalHourOffset 1;
BA_ "SPN" SG_ 2566842110 LocalHourOffset 1602;
BA_ "SAEDocument" SG_ 2566842110 LocalHourOffset "J1939-71";
BA_ "SigType" SG_ 2566842110 LocalMinuteOffset 1;
BA_ "SPN" SG_ 2566842110 LocalMinuteOffset 1601;
BA_ "SAEDocument" SG_ 2566842110 LocalMinuteOffset "J1939-71";
BA_ "SigType" SG_ 2566842110 Year 1;
BA_ "SPN" SG_ 2566842110 Year 964;
BA_ "SAEDocument" SG_ 2566842110 Year "J1939-71";
BA_ "SigType" SG_ 2566842110 Day 1;
BA_ "SPN" SG_ 2566842110 Day 962;
BA_ "SAEDocument" SG_ 2566842110 Day "J1939-71";
BA_ "SigType" SG_ 2566842110 Month 1;
BA_ "SPN" SG_ 2566842110 Month 963;
BA_ "SAEDocument" SG_ 2566842110 Month "J1939-71";
BA_ "SigType" SG_ 2566842110 Hours 1;
BA_ "SPN" SG_ 2566842110 Hours 961;
BA_ "SAEDocument" SG_ 2566842110 Hours "J1939-71";
BA_ "SigType" SG_ 2566842110 Minutes 1;
BA_ "SPN" SG_ 2566842110 Minutes 960;
BA_ "SAEDocument" SG_ 2566842110 Minutes "J1939-71";
BA_ "SigType" SG_ 2566842110 Seconds 1;
BA_ "SPN" SG_ 2566842110 Seconds 959;
BA_ "SAEDocument" SG_ 2566842110 Seconds "J1939-71";
BA_ "SPN" SG_ 2566821630 EngDsrdTrboWastegateActuator2Pos 5373;
BA_ "SAEDocument" SG_ 2566821630 EngDsrdTrboWastegateActuator2Pos "J1939-71";
BA_ "SPN" SG_ 2566821630 EngTrbWstgateActuator1TempStatus 5372;
BA_ "SAEDocument" SG_ 2566821630 EngTrbWstgateActuator1TempStatus "J1939-71";
BA_ "SPN" SG_ 2566821630 EngTrbWstgtActtor1PreliminaryFMI 5371;
BA_ "SAEDocument" SG_ 2566821630 EngTrbWstgtActtor1PreliminaryFMI "J1939-71";
BA_ "SPN" SG_ 2566821630 EngDsrdTrboWastegateActuator1Pos 5370;
BA_ "SAEDocument" SG_ 2566821630 EngDsrdTrboWastegateActuator1Pos "J1939-71";
BA_ "SigType" SG_ 2566821630 EngTrbWstgteActuatorCtrlAirPress 1;
BA_ "SPN" SG_ 2566821630 EngTrbWstgteActuatorCtrlAirPress 1192;
BA_ "SAEDocument" SG_ 2566821630 EngTrbWstgteActuatorCtrlAirPress "J1939-71";
BA_ "SigType" SG_ 2566821630 EngTurboWastegateActuator4Pos 1;
BA_ "SPN" SG_ 2566821630 EngTurboWastegateActuator4Pos 1191;
BA_ "SAEDocument" SG_ 2566821630 EngTurboWastegateActuator4Pos "J1939-71";
BA_ "SigType" SG_ 2566821630 EngTurboWastegateActuator3Pos 1;
BA_ "SPN" SG_ 2566821630 EngTurboWastegateActuator3Pos 1190;
BA_ "SAEDocument" SG_ 2566821630 EngTurboWastegateActuator3Pos "J1939-71";
BA_ "SigType" SG_ 2566821630 EngTurboWastegateActuator2Pos 1;
BA_ "SPN" SG_ 2566821630 EngTurboWastegateActuator2Pos 1189;
BA_ "SAEDocument" SG_ 2566821630 EngTurboWastegateActuator2Pos "J1939-71";
BA_ "SigType" SG_ 2566821630 EngTurboWastegateActuator1Pos 1;
BA_ "SPN" SG_ 2566821630 EngTurboWastegateActuator1Pos 1188;
BA_ "SAEDocument" SG_ 2566821630 EngTurboWastegateActuator1Pos "J1939-71";
BA_ "SigType" SG_ 2365484286 VehicleOverspeed 4;
BA_ "SPN" SG_ 2365484286 VehicleOverspeed 1614;
BA_ "SAEDocument" SG_ 2365484286 VehicleOverspeed "J1939-71";
BA_ "SigType" SG_ 2365484286 VehicleMotion 4;
BA_ "SPN" SG_ 2365484286 VehicleMotion 1611;
BA_ "SAEDocument" SG_ 2365484286 VehicleMotion "J1939-71";
BA_ "SigType" SG_ 2365484286 TachographVehicleSpeed 1;
BA_ "SPN" SG_ 2365484286 TachographVehicleSpeed 1624;
BA_ "SAEDocument" SG_ 2365484286 TachographVehicleSpeed "J1939-71";
BA_ "SigType" SG_ 2365484286 TachographOutputShaftSpeed 1;
BA_ "SPN" SG_ 2365484286 TachographOutputShaftSpeed 1623;
BA_ "SAEDocument" SG_ 2365484286 TachographOutputShaftSpeed "J1939-71";
BA_ "SigType" SG_ 2365484286 DirectionIndicator 4;
BA_ "SPN" SG_ 2365484286 DirectionIndicator 1619;
BA_ "SAEDocument" SG_ 2365484286 DirectionIndicator "J1939-71";
BA_ "SigType" SG_ 2365484286 TachographPerformance 5;
BA_ "SPN" SG_ 2365484286 TachographPerformance 1620;
BA_ "SAEDocument" SG_ 2365484286 TachographPerformance "J1939-71";
BA_ "SigType" SG_ 2365484286 HandlingInformation 5;
BA_ "SPN" SG_ 2365484286 HandlingInformation 1621;
BA_ "SAEDocument" SG_ 2365484286 HandlingInformation "J1939-71";
BA_ "SigType" SG_ 2365484286 SystemEvent 5;
BA_ "SPN" SG_ 2365484286 SystemEvent 1622;
BA_ "SAEDocument" SG_ 2365484286 SystemEvent "J1939-71";
BA_ "SigType" SG_ 2365484286 DriverCardDriver2 4;
BA_ "SPN" SG_ 2365484286 DriverCardDriver2 1616;
BA_ "SAEDocument" SG_ 2365484286 DriverCardDriver2 "J1939-71";
BA_ "SPN" SG_ 2365484286 Driver2TimeRelatedStates 1618;
BA_ "SAEDocument" SG_ 2365484286 Driver2TimeRelatedStates "J1939-71";
BA_ "SigType" SG_ 2365484286 DriverCardDriver1 4;
BA_ "SPN" SG_ 2365484286 DriverCardDriver1 1615;
BA_ "SAEDocument" SG_ 2365484286 DriverCardDriver1 "J1939-71";
BA_ "SPN" SG_ 2365484286 Driver1TimeRelatedStates 1617;
BA_ "SAEDocument" SG_ 2365484286 Driver1TimeRelatedStates "J1939-71";
BA_ "SPN" SG_ 2365484286 Driver2WorkingState 1613;
BA_ "SAEDocument" SG_ 2365484286 Driver2WorkingState "J1939-71";
BA_ "SPN" SG_ 2365484286 Driver1WorkingState 1612;
BA_ "SAEDocument" SG_ 2365484286 Driver1WorkingState "J1939-71";
BA_ "SigType" SG_ 2566771710 EngTurbo4CompressorOutletTemp 1;
BA_ "SPN" SG_ 2566771710 EngTurbo4CompressorOutletTemp 2801;
BA_ "SAEDocument" SG_ 2566771710 EngTurbo4CompressorOutletTemp "J1939-71";
BA_ "SigType" SG_ 2566771710 EngTurbo3CompressorOutletTemp 1;
BA_ "SPN" SG_ 2566771710 EngTurbo3CompressorOutletTemp 2800;
BA_ "SAEDocument" SG_ 2566771710 EngTurbo3CompressorOutletTemp "J1939-71";
BA_ "SigType" SG_ 2566771710 EngTurbo2CompressorOutletTemp 1;
BA_ "SPN" SG_ 2566771710 EngTurbo2CompressorOutletTemp 2799;
BA_ "SAEDocument" SG_ 2566771710 EngTurbo2CompressorOutletTemp "J1939-71";
BA_ "SigType" SG_ 2566771710 EngTurbo1CompressorOutletTemp 1;
BA_ "SPN" SG_ 2566771710 EngTurbo1CompressorOutletTemp 2629;
BA_ "SAEDocument" SG_ 2566771710 EngTurbo1CompressorOutletTemp "J1939-71";
BA_ "SigType" SG_ 2566821886 EngTurbo4TurbineOutletTemp 1;
BA_ "SPN" SG_ 2566821886 EngTurbo4TurbineOutletTemp 1187;
BA_ "SAEDocument" SG_ 2566821886 EngTurbo4TurbineOutletTemp "J1939-71";
BA_ "SigType" SG_ 2566821886 EngTurbo3TurbineOutletTemp 1;
BA_ "SPN" SG_ 2566821886 EngTurbo3TurbineOutletTemp 1186;
BA_ "SAEDocument" SG_ 2566821886 EngTurbo3TurbineOutletTemp "J1939-71";
BA_ "SigType" SG_ 2566821886 EngTurbo2TurbineOutletTemp 1;
BA_ "SPN" SG_ 2566821886 EngTurbo2TurbineOutletTemp 1185;
BA_ "SAEDocument" SG_ 2566821886 EngTurbo2TurbineOutletTemp "J1939-71";
BA_ "SigType" SG_ 2566821886 EngTurbo1TurbineOutletTemp 1;
BA_ "SPN" SG_ 2566821886 EngTurbo1TurbineOutletTemp 1184;
BA_ "SAEDocument" SG_ 2566821886 EngTurbo1TurbineOutletTemp "J1939-71";
BA_ "SigType" SG_ 2566822142 EngTurbo4TurbineIntakeTemp 1;
BA_ "SPN" SG_ 2566822142 EngTurbo4TurbineIntakeTemp 1183;
BA_ "SAEDocument" SG_ 2566822142 EngTurbo4TurbineIntakeTemp "J1939-71";
BA_ "SigType" SG_ 2566822142 EngTurbo3TurbineIntakeTemp 1;
BA_ "SPN" SG_ 2566822142 EngTurbo3TurbineIntakeTemp 1182;
BA_ "SAEDocument" SG_ 2566822142 EngTurbo3TurbineIntakeTemp "J1939-71";
BA_ "SigType" SG_ 2566822142 EngTurbo2TurbineIntakeTemp 1;
BA_ "SPN" SG_ 2566822142 EngTurbo2TurbineIntakeTemp 1181;
BA_ "SAEDocument" SG_ 2566822142 EngTurbo2TurbineIntakeTemp "J1939-71";
BA_ "SigType" SG_ 2566822142 EngTurbo1TurbineIntakeTemp 1;
BA_ "SPN" SG_ 2566822142 EngTurbo1TurbineIntakeTemp 1180;
BA_ "SAEDocument" SG_ 2566822142 EngTurbo1TurbineIntakeTemp "J1939-71";
BA_ "SigType" SG_ 2566822398 EngTurbo4CompressorIntakePress 1;
BA_ "SPN" SG_ 2566822398 EngTurbo4CompressorIntakePress 1179;
BA_ "SAEDocument" SG_ 2566822398 EngTurbo4CompressorIntakePress "J1939-71";
BA_ "SigType" SG_ 2566822398 EngTurbo3CompressorIntakePress 1;
BA_ "SPN" SG_ 2566822398 EngTurbo3CompressorIntakePress 1178;
BA_ "SAEDocument" SG_ 2566822398 EngTurbo3CompressorIntakePress "J1939-71";
BA_ "SigType" SG_ 2566822398 EngTurbo2CompressorIntakePress 1;
BA_ "SPN" SG_ 2566822398 EngTurbo2CompressorIntakePress 1177;
BA_ "SAEDocument" SG_ 2566822398 EngTurbo2CompressorIntakePress "J1939-71";
BA_ "SigType" SG_ 2566822398 EngTurbo1CompressorIntakePress 1;
BA_ "SPN" SG_ 2566822398 EngTurbo1CompressorIntakePress 1176;
BA_ "SAEDocument" SG_ 2566822398 EngTurbo1CompressorIntakePress "J1939-71";
BA_ "SigType" SG_ 2566822654 EngTurbo4CompressorIntakeTemp 1;
BA_ "SPN" SG_ 2566822654 EngTurbo4CompressorIntakeTemp 1175;
BA_ "SAEDocument" SG_ 2566822654 EngTurbo4CompressorIntakeTemp "J1939-71";
BA_ "SigType" SG_ 2566822654 EngTurbo3CompressorIntakeTemp 1;
BA_ "SPN" SG_ 2566822654 EngTurbo3CompressorIntakeTemp 1174;
BA_ "SAEDocument" SG_ 2566822654 EngTurbo3CompressorIntakeTemp "J1939-71";
BA_ "SigType" SG_ 2566822654 EngTurbo2CompressorIntakeTemp 1;
BA_ "SPN" SG_ 2566822654 EngTurbo2CompressorIntakeTemp 1173;
BA_ "SAEDocument" SG_ 2566822654 EngTurbo2CompressorIntakeTemp "J1939-71";
BA_ "SigType" SG_ 2566822654 EngTurbo1CompressorIntakeTemp 1;
BA_ "SPN" SG_ 2566822654 EngTurbo1CompressorIntakeTemp 1172;
BA_ "SAEDocument" SG_ 2566822654 EngTurbo1CompressorIntakeTemp "J1939-71";
BA_ "SigType" SG_ 2633931774 EngTurbo4Speed 1;
BA_ "SPN" SG_ 2633931774 EngTurbo4Speed 1171;
BA_ "SAEDocument" SG_ 2633931774 EngTurbo4Speed "J1939-71";
BA_ "SigType" SG_ 2633931774 EngTurbo3Speed 1;
BA_ "SPN" SG_ 2633931774 EngTurbo3Speed 1170;
BA_ "SAEDocument" SG_ 2633931774 EngTurbo3Speed "J1939-71";
BA_ "SigType" SG_ 2633931774 EngTurbo2Speed 1;
BA_ "SPN" SG_ 2633931774 EngTurbo2Speed 1169;
BA_ "SAEDocument" SG_ 2633931774 EngTurbo2Speed "J1939-71";
BA_ "SigType" SG_ 2633931774 EngTurboLubeOilPress2 1;
BA_ "SPN" SG_ 2633931774 EngTurboLubeOilPress2 1168;
BA_ "SAEDocument" SG_ 2633931774 EngTurboLubeOilPress2 "J1939-71";
BA_ "SigType" SG_ 2566802430 TransTorqueLimit 1;
BA_ "SPN" SG_ 2566802430 TransTorqueLimit 1845;
BA_ "SAEDocument" SG_ 2566802430 TransTorqueLimit "J1939-71";
BA_ "SigType" SG_ 2566841086 TransGearRatio 1;
BA_ "SPN" SG_ 2566841086 TransGearRatio 581;
BA_ "SAEDocument" SG_ 2566841086 TransGearRatio "J1939-71";
BA_ "SigType" SG_ 2566841086 NumberOfForwardGearRatios 1;
BA_ "SPN" SG_ 2566841086 NumberOfForwardGearRatios 957;
BA_ "SAEDocument" SG_ 2566841086 NumberOfForwardGearRatios "J1939-71";
BA_ "SigType" SG_ 2566841086 NumberOfReverseGearRatios 1;
BA_ "SPN" SG_ 2566841086 NumberOfReverseGearRatios 958;
BA_ "SAEDocument" SG_ 2566841086 NumberOfReverseGearRatios "J1939-71";
BA_ "SigType" SG_ 2348941054 TransMode8 5;
BA_ "SPN" SG_ 2348941054 TransMode8 4249;
BA_ "SAEDocument" SG_ 2348941054 TransMode8 "J1939-71";
BA_ "SigType" SG_ 2348941054 TransMode7 5;
BA_ "SPN" SG_ 2348941054 TransMode7 4248;
BA_ "SAEDocument" SG_ 2348941054 TransMode7 "J1939-71";
BA_ "SigType" SG_ 2348941054 TransMode6 5;
BA_ "SPN" SG_ 2348941054 TransMode6 4247;
BA_ "SAEDocument" SG_ 2348941054 TransMode6 "J1939-71";
BA_ "SigType" SG_ 2348941054 TransMode5 5;
BA_ "SPN" SG_ 2348941054 TransMode5 4246;
BA_ "SAEDocument" SG_ 2348941054 TransMode5 "J1939-71";
BA_ "SigType" SG_ 2348941054 TrnsShftSlectorDisplayModeSwitch 4;
BA_ "SPN" SG_ 2348941054 TrnsShftSlectorDisplayModeSwitch 2985;
BA_ "SAEDocument" SG_ 2348941054 TrnsShftSlectorDisplayModeSwitch "J1939-71";
BA_ "SPN" SG_ 2348941054 TransRequestedLaunchGear 4255;
BA_ "SAEDocument" SG_ 2348941054 TransRequestedLaunchGear "J1939-71";
BA_ "SigType" SG_ 2348941054 TransMode4 5;
BA_ "SPN" SG_ 2348941054 TransMode4 1855;
BA_ "SAEDocument" SG_ 2348941054 TransMode4 "J1939-71";
BA_ "SigType" SG_ 2348941054 TransMode3 5;
BA_ "SPN" SG_ 2348941054 TransMode3 1854;
BA_ "SAEDocument" SG_ 2348941054 TransMode3 "J1939-71";
BA_ "SigType" SG_ 2348941054 TransMode2 5;
BA_ "SPN" SG_ 2348941054 TransMode2 1853;
BA_ "SAEDocument" SG_ 2348941054 TransMode2 "J1939-71";
BA_ "SigType" SG_ 2348941054 TransMode1 5;
BA_ "SPN" SG_ 2348941054 TransMode1 1852;
BA_ "SAEDocument" SG_ 2348941054 TransMode1 "J1939-71";
BA_ "SigType" SG_ 2348941054 DisengageDiffLockRqCentralRear 5;
BA_ "SPN" SG_ 2348941054 DisengageDiffLockRqCentralRear 691;
BA_ "SAEDocument" SG_ 2348941054 DisengageDiffLockRqCentralRear "J1939-71";
BA_ "SigType" SG_ 2348941054 DisengageDiffLockRqCentralFront 5;
BA_ "SPN" SG_ 2348941054 DisengageDiffLockRqCentralFront 690;
BA_ "SAEDocument" SG_ 2348941054 DisengageDiffLockRqCentralFront "J1939-71";
BA_ "SigType" SG_ 2348941054 DisengageDiffLockRqCentral 5;
BA_ "SPN" SG_ 2348941054 DisengageDiffLockRqCentral 689;
BA_ "SAEDocument" SG_ 2348941054 DisengageDiffLockRqCentral "J1939-71";
BA_ "SigType" SG_ 2348941054 DisengageDiffLockRqRearAxle2 5;
BA_ "SPN" SG_ 2348941054 DisengageDiffLockRqRearAxle2 688;
BA_ "SAEDocument" SG_ 2348941054 DisengageDiffLockRqRearAxle2 "J1939-71";
BA_ "SigType" SG_ 2348941054 DisengageDiffLockRqRearAxle1 5;
BA_ "SPN" SG_ 2348941054 DisengageDiffLockRqRearAxle1 687;
BA_ "SAEDocument" SG_ 2348941054 DisengageDiffLockRqRearAxle1 "J1939-71";
BA_ "SigType" SG_ 2348941054 DisengageDiffLockRqFrontAxle2 5;
BA_ "SPN" SG_ 2348941054 DisengageDiffLockRqFrontAxle2 686;
BA_ "SAEDocument" SG_ 2348941054 DisengageDiffLockRqFrontAxle2 "J1939-71";
BA_ "SigType" SG_ 2348941054 DisengageDiffLockRqFrontAxle1 5;
BA_ "SPN" SG_ 2348941054 DisengageDiffLockRqFrontAxle1 685;
BA_ "SAEDocument" SG_ 2348941054 DisengageDiffLockRqFrontAxle1 "J1939-71";
BA_ "SPN" SG_ 2348941054 TransRequestedGear 525;
BA_ "SAEDocument" SG_ 2348941054 TransRequestedGear "J1939-71";
BA_ "SPN" SG_ 2348941054 RequestedPercentClutchSlip 684;
BA_ "SAEDocument" SG_ 2348941054 RequestedPercentClutchSlip "J1939-71";
BA_ "SigType" SG_ 2348941054 TransReverseGearShiftInhibitRq 5;
BA_ "SPN" SG_ 2348941054 TransReverseGearShiftInhibitRq 4242;
BA_ "SAEDocument" SG_ 2348941054 TransReverseGearShiftInhibitRq "J1939-71";
BA_ "SigType" SG_ 2348941054 DisengageDrivelineRq 5;
BA_ "SPN" SG_ 2348941054 DisengageDrivelineRq 683;
BA_ "SAEDocument" SG_ 2348941054 DisengageDrivelineRq "J1939-71";
BA_ "SigType" SG_ 2348941054 TrnsTrqeConverterLockupDisableRq 5;
BA_ "SPN" SG_ 2348941054 TrnsTrqeConverterLockupDisableRq 682;
BA_ "SAEDocument" SG_ 2348941054 TrnsTrqeConverterLockupDisableRq "J1939-71";
BA_ "SigType" SG_ 2348941054 TransGearShiftInhibitRq 5;
BA_ "SPN" SG_ 2348941054 TransGearShiftInhibitRq 681;
BA_ "SAEDocument" SG_ 2348941054 TransGearShiftInhibitRq "J1939-71";
BA_ "SigType" SG_ 2566839806 EngTurboOilLevelSwitch 4;
BA_ "SPN" SG_ 2566839806 EngTurboOilLevelSwitch 1665;
BA_ "SAEDocument" SG_ 2566839806 EngTurboOilLevelSwitch "J1939-71";
BA_ "SigType" SG_ 2566839806 EngTurbo1Speed 1;
BA_ "SPN" SG_ 2566839806 EngTurbo1Speed 103;
BA_ "SAEDocument" SG_ 2566839806 EngTurbo1Speed "J1939-71";
BA_ "SigType" SG_ 2566839806 EngTurboLubeOilPress1 1;
BA_ "SPN" SG_ 2566839806 EngTurboLubeOilPress1 104;
BA_ "SAEDocument" SG_ 2566839806 EngTurboLubeOilPress1 "J1939-71";
BA_ "SigType" SG_ 2633911806 EngTotalAverageFuelEconomy 1;
BA_ "SPN" SG_ 2633911806 EngTotalAverageFuelEconomy 1835;
BA_ "SAEDocument" SG_ 2633911806 EngTotalAverageFuelEconomy "J1939-71";
BA_ "SigType" SG_ 2633911806 EngTotalAverageFuelRate 1;
BA_ "SPN" SG_ 2633911806 EngTotalAverageFuelRate 1834;
BA_ "SAEDocument" SG_ 2633911806 EngTotalAverageFuelRate "J1939-71";
BA_ "SPN" SG_ 2566775550 AirSuspensionSupplyPressRq 2608;
BA_ "SAEDocument" SG_ 2566775550 AirSuspensionSupplyPressRq "J1939-71";
BA_ "SPN" SG_ 2566775550 AuxEquipmentSupplyPressRq 2607;
BA_ "SAEDocument" SG_ 2566775550 AuxEquipmentSupplyPressRq "J1939-71";
BA_ "SPN" SG_ 2566775550 ServiceBrakeAirPressRqCircuit2 2606;
BA_ "SAEDocument" SG_ 2566775550 ServiceBrakeAirPressRqCircuit2 "J1939-71";
BA_ "SPN" SG_ 2566775550 ServiceBrakeAirPressRqCircuit1 2605;
BA_ "SAEDocument" SG_ 2566775550 ServiceBrakeAirPressRqCircuit1 "J1939-71";
BA_ "SPN" SG_ 2566775550 ParkingAnd_orTrailerAirPressRq 2604;
BA_ "SAEDocument" SG_ 2566775550 ParkingAnd_orTrailerAirPressRq "J1939-71";
BA_ "SPN" SG_ 2566775550 PneumaticSupplyPressRq 2603;
BA_ "SAEDocument" SG_ 2566775550 PneumaticSupplyPressRq "J1939-71";
BA_ "SigType" SG_ 2566819838 EngExtlShutdownAirSupplyPress 1;
BA_ "SPN" SG_ 2566819838 EngExtlShutdownAirSupplyPress 1320;
BA_ "SAEDocument" SG_ 2566819838 EngExtlShutdownAirSupplyPress "J1939-71";
BA_ "SigType" SG_ 2566839038 NmbrOfSftwreIdentificationFields 1;
BA_ "SPN" SG_ 2566839038 NmbrOfSftwreIdentificationFields 965;
BA_ "SAEDocument" SG_ 2566839038 NmbrOfSftwreIdentificationFields "J1939-71";
BA_ "SigType" SG_ 2566839038 SoftwareIdentification 1;
BA_ "SPN" SG_ 2566839038 SoftwareIdentification 234;
BA_ "SAEDocument" SG_ 2566839038 SoftwareIdentification "J1939-71";
BA_ "SigType" SG_ 2566841598 PTOShutdownHasShutdownEng 5;
BA_ "SPN" SG_ 2566841598 PTOShutdownHasShutdownEng 5404;
BA_ "SAEDocument" SG_ 2566841598 PTOShutdownHasShutdownEng "J1939-71";
BA_ "SigType" SG_ 2566841598 EngAirShutoffStatus 5;
BA_ "SPN" SG_ 2566841598 EngAirShutoffStatus 3667;
BA_ "SAEDocument" SG_ 2566841598 EngAirShutoffStatus "J1939-71";
BA_ "SigType" SG_ 2566841598 EngOverspeedTest 4;
BA_ "SPN" SG_ 2566841598 EngOverspeedTest 2812;
BA_ "SAEDocument" SG_ 2566841598 EngOverspeedTest "J1939-71";
BA_ "SigType" SG_ 2566841598 EngAirShutoffCmdStatus 5;
BA_ "SPN" SG_ 2566841598 EngAirShutoffCmdStatus 2813;
BA_ "SAEDocument" SG_ 2566841598 EngAirShutoffCmdStatus "J1939-71";
BA_ "SigType" SG_ 2566841598 EngAlarmOutputCmdStatus 5;
BA_ "SPN" SG_ 2566841598 EngAlarmOutputCmdStatus 2814;
BA_ "SAEDocument" SG_ 2566841598 EngAlarmOutputCmdStatus "J1939-71";
BA_ "SigType" SG_ 2566841598 EngAlarmAcknowledge 4;
BA_ "SPN" SG_ 2566841598 EngAlarmAcknowledge 2815;
BA_ "SAEDocument" SG_ 2566841598 EngAlarmAcknowledge "J1939-71";
BA_ "SigType" SG_ 2566841598 EngProtectionSystemConfig 5;
BA_ "SPN" SG_ 2566841598 EngProtectionSystemConfig 1111;
BA_ "SAEDocument" SG_ 2566841598 EngProtectionSystemConfig "J1939-71";
BA_ "SigType" SG_ 2566841598 EngProtectionSystemTimerState 5;
BA_ "SPN" SG_ 2566841598 EngProtectionSystemTimerState 1107;
BA_ "SAEDocument" SG_ 2566841598 EngProtectionSystemTimerState "J1939-71";
BA_ "SigType" SG_ 2566841598 EngProtectionSystemTimerOverride 5;
BA_ "SPN" SG_ 2566841598 EngProtectionSystemTimerOverride 1108;
BA_ "SAEDocument" SG_ 2566841598 EngProtectionSystemTimerOverride "J1939-71";
BA_ "SigType" SG_ 2566841598 EngPrtctnSystmApprachingShutdown 5;
BA_ "SPN" SG_ 2566841598 EngPrtctnSystmApprachingShutdown 1109;
BA_ "SAEDocument" SG_ 2566841598 EngPrtctnSystmApprachingShutdown "J1939-71";
BA_ "SigType" SG_ 2566841598 EngPrtectionSystemHasShutdownEng 5;
BA_ "SPN" SG_ 2566841598 EngPrtectionSystemHasShutdownEng 1110;
BA_ "SAEDocument" SG_ 2566841598 EngPrtectionSystemHasShutdownEng "J1939-71";
BA_ "SigType" SG_ 2566841598 EngWaitToStartLamp 5;
BA_ "SPN" SG_ 2566841598 EngWaitToStartLamp 1081;
BA_ "SAEDocument" SG_ 2566841598 EngWaitToStartLamp "J1939-71";
BA_ "SigType" SG_ 2566841598 RefrigerantHighPressSwitch 4;
BA_ "SPN" SG_ 2566841598 RefrigerantHighPressSwitch 605;
BA_ "SAEDocument" SG_ 2566841598 RefrigerantHighPressSwitch "J1939-71";
BA_ "SigType" SG_ 2566841598 RefrigerantLowPressSwitch 4;
BA_ "SPN" SG_ 2566841598 RefrigerantLowPressSwitch 875;
BA_ "SAEDocument" SG_ 2566841598 RefrigerantLowPressSwitch "J1939-71";
BA_ "SigType" SG_ 2566841598 A_CHighPressFanSwitch 4;
BA_ "SPN" SG_ 2566841598 A_CHighPressFanSwitch 985;
BA_ "SAEDocument" SG_ 2566841598 A_CHighPressFanSwitch "J1939-71";
BA_ "SigType" SG_ 2566841598 EngIdleShutdownTimerFunction 4;
BA_ "SPN" SG_ 2566841598 EngIdleShutdownTimerFunction 591;
BA_ "SAEDocument" SG_ 2566841598 EngIdleShutdownTimerFunction "J1939-71";
BA_ "SigType" SG_ 2566841598 EngIdleShutdownTimerState 5;
BA_ "SPN" SG_ 2566841598 EngIdleShutdownTimerState 590;
BA_ "SAEDocument" SG_ 2566841598 EngIdleShutdownTimerState "J1939-71";
BA_ "SigType" SG_ 2566841598 EngIdleShutdownTimerOverride 5;
BA_ "SPN" SG_ 2566841598 EngIdleShutdownTimerOverride 592;
BA_ "SAEDocument" SG_ 2566841598 EngIdleShutdownTimerOverride "J1939-71";
BA_ "SigType" SG_ 2566841598 EngIdleShutdownDriverAlertMode 5;
BA_ "SPN" SG_ 2566841598 EngIdleShutdownDriverAlertMode 594;
BA_ "SAEDocument" SG_ 2566841598 EngIdleShutdownDriverAlertMode "J1939-71";
BA_ "SigType" SG_ 2566841598 EngIdleShutdownHasShutdownEng 5;
BA_ "SPN" SG_ 2566841598 EngIdleShutdownHasShutdownEng 593;
BA_ "SAEDocument" SG_ 2566841598 EngIdleShutdownHasShutdownEng "J1939-71";
BA_ "SAEDocument" SG_ 2633895166 VehicleSystem5 "J1939-81";
BA_ "SAEDocument" SG_ 2633895166 VehicleSystem4 "J1939-81";
BA_ "SAEDocument" SG_ 2633895166 VehicleSystem3 "J1939-81";
BA_ "SAEDocument" SG_ 2633895166 VehicleSystem2 "J1939-81";
BA_ "SAEDocument" SG_ 2633895166 VehicleSystem1 "J1939-81";
BA_ "SPN" SG_ 2633895166 ArbitraryAddressCapable 2844;
BA_ "SAEDocument" SG_ 2633895166 ArbitraryAddressCapable "J1939-81";
BA_ "SPN" SG_ 2633895166 IndustryGroup 2846;
BA_ "SAEDocument" SG_ 2633895166 IndustryGroup "NMEA2000";
BA_ "SPN" SG_ 2633895166 VehicleSystemInstance 2843;
BA_ "SAEDocument" SG_ 2633895166 VehicleSystemInstance "J1939-81";
BA_ "SAEDocument" SG_ 2633895166 VehicleSystem "J1939-81";
BA_ "SPN" SG_ 2633895166 ECUInstance 2840;
BA_ "SAEDocument" SG_ 2633895166 ECUInstance "J1939-81";
BA_ "SPN" SG_ 2633895166 FunctionInstance 2839;
BA_ "SAEDocument" SG_ 2633895166 FunctionInstance "J1939-81";
BA_ "SPN" SG_ 2633895166 Function 2841;
BA_ "SAEDocument" SG_ 2633895166 Function "J1939-81";
BA_ "SigType" SG_ 2633895166 ManufacturerCode 1;
BA_ "SPN" SG_ 2633895166 ManufacturerCode 2838;
BA_ "SAEDocument" SG_ 2633895166 ManufacturerCode "NMEA2000";
BA_ "SPN" SG_ 2633895166 IdentityNumber 2837;
BA_ "SAEDocument" SG_ 2633895166 IdentityNumber "J1939-81";
BA_ "SigType" SG_ 2566832382 SrviceDelay_OperationalTimeBased 1;
BA_ "SPN" SG_ 2566832382 SrviceDelay_OperationalTimeBased 916;
BA_ "SAEDocument" SG_ 2566832382 SrviceDelay_OperationalTimeBased "J1939-71";
BA_ "SigType" SG_ 2566832382 ServiceComponentIdentification_0 1;
BA_ "SPN" SG_ 2566832382 ServiceComponentIdentification_0 911;
BA_ "SAEDocument" SG_ 2566832382 ServiceComponentIdentification_0 "J1939-71";
BA_ "SystemSignalLongSymbol" SG_ 2566832382 ServiceComponentIdentification_0 "ServiceComponentIdentification_02";
BA_ "SigType" SG_ 2566832382 ServiceDelay_CalendarTimeBased 1;
BA_ "SPN" SG_ 2566832382 ServiceDelay_CalendarTimeBased 915;
BA_ "SAEDocument" SG_ 2566832382 ServiceDelay_CalendarTimeBased "J1939-71";
BA_ "SystemSignalLongSymbol" SG_ 2566832382 ServiceComponentIdentificat_0000 "ServiceComponentIdentification_01";
BA_ "SigType" SG_ 2566832382 ServiceDistance 1;
BA_ "SPN" SG_ 2566832382 ServiceDistance 914;
BA_ "SAEDocument" SG_ 2566832382 ServiceDistance "J1939-71";
BA_ "SigType" SG_ 2633928446 TimeSinceLastService 1;
BA_ "SPN" SG_ 2633928446 TimeSinceLastService 1350;
BA_ "SAEDocument" SG_ 2633928446 TimeSinceLastService "J1939-71";
BA_ "SigType" SG_ 2633928446 ServiceComponentIdentification 1;
BA_ "SPN" SG_ 2633928446 ServiceComponentIdentification 1379;
BA_ "SAEDocument" SG_ 2633928446 ServiceComponentIdentification "J1939-71";
BA_ "SPN" SG_ 2566804478 MinContinuousRetarderTorque 1783;
BA_ "SAEDocument" SG_ 2566804478 MinContinuousRetarderTorque "J1939-71";
BA_ "SPN" SG_ 2566804478 MaxContinuousRetarderTorque 1782;
BA_ "SAEDocument" SG_ 2566804478 MaxContinuousRetarderTorque "J1939-71";
BA_ "SPN" SG_ 2566804478 MinContinuousRetarderSpeed 1781;
BA_ "SAEDocument" SG_ 2566804478 MinContinuousRetarderSpeed "J1939-71";
BA_ "SPN" SG_ 2566804478 MaxContinuousRetarderSpeed 1780;
BA_ "SAEDocument" SG_ 2566804478 MaxContinuousRetarderSpeed "J1939-71";
BA_ "SPN" SG_ 2566804478 HghLmtThrshldFrMnCntnsTrqFrmRtrd 1779;
BA_ "SAEDocument" SG_ 2566804478 HghLmtThrshldFrMnCntnsTrqFrmRtrd "J1939-71";
BA_ "SPN" SG_ 2566804478 LwLmtThrshldFrMxTrqeFromRetarder 1778;
BA_ "SAEDocument" SG_ 2566804478 LwLmtThrshldFrMxTrqeFromRetarder "J1939-71";
BA_ "SPN" SG_ 2566804478 HghLmtThrshldFrMnCntnsRPMFrmRtrd 1777;
BA_ "SAEDocument" SG_ 2566804478 HghLmtThrshldFrMnCntnsRPMFrmRtrd "J1939-71";
BA_ "SPN" SG_ 2566804478 LwLmtThrshldFrMaxRPMFromRetarder 1776;
BA_ "SAEDocument" SG_ 2566804478 LwLmtThrshldFrMaxRPMFromRetarder "J1939-71";
BA_ "SigType" SG_ 2566847486 DrvlineRetarderOverheatIndicator 5;
BA_ "SPN" SG_ 2566847486 DrvlineRetarderOverheatIndicator 5346;
BA_ "SAEDocument" SG_ 2566847486 DrvlineRetarderOverheatIndicator "J1939-71";
BA_ "SigType" SG_ 2566847486 HydRetarderOilTemp 1;
BA_ "SPN" SG_ 2566847486 HydRetarderOilTemp 120;
BA_ "SAEDocument" SG_ 2566847486 HydRetarderOilTemp "J1939-71";
BA_ "SigType" SG_ 2566847486 HydRetarderPress 1;
BA_ "SPN" SG_ 2566847486 HydRetarderPress 119;
BA_ "SAEDocument" SG_ 2566847486 HydRetarderPress "J1939-71";
BA_ "SigType" SG_ 2631859966 SteerStraightAheadPosReset 5;
BA_ "SPN" SG_ 2631859966 SteerStraightAheadPosReset 3600;
BA_ "SAEDocument" SG_ 2631859966 SteerStraightAheadPosReset "J1939-71";
BA_ "SigType" SG_ 2631859966 EngBuildHoursReset 5;
BA_ "SPN" SG_ 2631859966 EngBuildHoursReset 1211;
BA_ "SAEDocument" SG_ 2631859966 EngBuildHoursReset "J1939-71";
BA_ "SigType" SG_ 2631859966 ServiceComponentIdentification 1;
BA_ "SPN" SG_ 2631859966 ServiceComponentIdentification 1584;
BA_ "SAEDocument" SG_ 2631859966 ServiceComponentIdentification "J1939-71";
BA_ "SigType" SG_ 2631859966 TripGroup2Proprietary 5;
BA_ "SPN" SG_ 2631859966 TripGroup2Proprietary 989;
BA_ "SAEDocument" SG_ 2631859966 TripGroup2Proprietary "J1939-71";
BA_ "SigType" SG_ 2631859966 TripGroup1 5;
BA_ "SPN" SG_ 2631859966 TripGroup1 988;
BA_ "SAEDocument" SG_ 2631859966 TripGroup1 "J1939-71";
BA_ "SigType" SG_ 2566840830 PercentTorqueAtPeakTorquePoint5 1;
BA_ "SPN" SG_ 2566840830 PercentTorqueAtPeakTorquePoint5 555;
BA_ "SAEDocument" SG_ 2566840830 PercentTorqueAtPeakTorquePoint5 "J1939-71";
BA_ "SigType" SG_ 2566840830 ReferenceRetarderTorque 1;
BA_ "SPN" SG_ 2566840830 ReferenceRetarderTorque 556;
BA_ "SAEDocument" SG_ 2566840830 ReferenceRetarderTorque "J1939-71";
BA_ "SigType" SG_ 2566840830 RetarderSpeedAtPeakTorquePoint5 1;
BA_ "SPN" SG_ 2566840830 RetarderSpeedAtPeakTorquePoint5 547;
BA_ "SAEDocument" SG_ 2566840830 RetarderSpeedAtPeakTorquePoint5 "J1939-71";
BA_ "SigType" SG_ 2566840830 PercentTorqueAtPoint4 1;
BA_ "SPN" SG_ 2566840830 PercentTorqueAtPoint4 554;
BA_ "SAEDocument" SG_ 2566840830 PercentTorqueAtPoint4 "J1939-71";
BA_ "SigType" SG_ 2566840830 RetarderSpeedAtPoint4 1;
BA_ "SPN" SG_ 2566840830 RetarderSpeedAtPoint4 550;
BA_ "SAEDocument" SG_ 2566840830 RetarderSpeedAtPoint4 "J1939-71";
BA_ "SigType" SG_ 2566840830 PercentTorqueAtPoint3 1;
BA_ "SPN" SG_ 2566840830 PercentTorqueAtPoint3 553;
BA_ "SAEDocument" SG_ 2566840830 PercentTorqueAtPoint3 "J1939-71";
BA_ "SigType" SG_ 2566840830 RetarderSpeedAtPoint3 1;
BA_ "SPN" SG_ 2566840830 RetarderSpeedAtPoint3 549;
BA_ "SAEDocument" SG_ 2566840830 RetarderSpeedAtPoint3 "J1939-71";
BA_ "SigType" SG_ 2566840830 PercentTorqueAtMaxSpeedPoint2 1;
BA_ "SPN" SG_ 2566840830 PercentTorqueAtMaxSpeedPoint2 552;
BA_ "SAEDocument" SG_ 2566840830 PercentTorqueAtMaxSpeedPoint2 "J1939-71";
BA_ "SigType" SG_ 2566840830 MaxRetarderSpeedPoint2 1;
BA_ "SPN" SG_ 2566840830 MaxRetarderSpeedPoint2 548;
BA_ "SAEDocument" SG_ 2566840830 MaxRetarderSpeedPoint2 "J1939-71";
BA_ "SigType" SG_ 2566840830 PercentTorqueAtIdlePoint1 1;
BA_ "SPN" SG_ 2566840830 PercentTorqueAtIdlePoint1 551;
BA_ "SAEDocument" SG_ 2566840830 PercentTorqueAtIdlePoint1 "J1939-71";
BA_ "SigType" SG_ 2566840830 RetarderSpeedAtIdlePoint1 1;
BA_ "SPN" SG_ 2566840830 RetarderSpeedAtIdlePoint1 546;
BA_ "SAEDocument" SG_ 2566840830 RetarderSpeedAtIdlePoint1 "J1939-71";
BA_ "SigType" SG_ 2566840830 RetarderCtrlMethod 1;
BA_ "SPN" SG_ 2566840830 RetarderCtrlMethod 557;
BA_ "SAEDocument" SG_ 2566840830 RetarderCtrlMethod "J1939-71";
BA_ "SPN" SG_ 2566840830 RetarderLocation 902;
BA_ "SAEDocument" SG_ 2566840830 RetarderLocation "J1939-71";
BA_ "SPN" SG_ 2566840830 RetarderType 901;
BA_ "SAEDocument" SG_ 2566840830 RetarderType "J1939-71";
BA_ "SigType" SG_ 2633930238 EngOperationTimeSinceRebuild 1;
BA_ "SPN" SG_ 2633930238 EngOperationTimeSinceRebuild 1193;
BA_ "SAEDocument" SG_ 2633930238 EngOperationTimeSinceRebuild "J1939-71";
BA_ "SigType" SG_ 2566844670 PowerTakeoffSetSpeed 1;
BA_ "SPN" SG_ 2566844670 PowerTakeoffSetSpeed 187;
BA_ "SAEDocument" SG_ 2566844670 PowerTakeoffSetSpeed "J1939-71";
BA_ "SigType" SG_ 2566844670 PowerTakeoffSpeed 1;
BA_ "SPN" SG_ 2566844670 PowerTakeoffSpeed 186;
BA_ "SAEDocument" SG_ 2566844670 PowerTakeoffSpeed "J1939-71";
BA_ "SigType" SG_ 2566844670 PowerTakeoffOilTemp 1;
BA_ "SPN" SG_ 2566844670 PowerTakeoffOilTemp 90;
BA_ "SAEDocument" SG_ 2566844670 PowerTakeoffOilTemp "J1939-71";
BA_ "SigType" SG_ 2566844670 OprtrEngPTOGvrnrMmrySelectSwitch 4;
BA_ "SPN" SG_ 2566844670 OprtrEngPTOGvrnrMmrySelectSwitch 2897;
BA_ "SAEDocument" SG_ 2566844670 OprtrEngPTOGvrnrMmrySelectSwitch "J1939-71";
BA_ "SigType" SG_ 2566844670 EngRmtPTOGvrnrVrblSpedCtrlSwitch 4;
BA_ "SPN" SG_ 2566844670 EngRmtPTOGvrnrVrblSpedCtrlSwitch 978;
BA_ "SAEDocument" SG_ 2566844670 EngRmtPTOGvrnrVrblSpedCtrlSwitch "J1939-71";
BA_ "SigType" SG_ 2566844670 EngRmtPTOGvrnrPrprgrmmdSpdCtrlSw 4;
BA_ "SPN" SG_ 2566844670 EngRmtPTOGvrnrPrprgrmmdSpdCtrlSw 979;
BA_ "SAEDocument" SG_ 2566844670 EngRmtPTOGvrnrPrprgrmmdSpdCtrlSw "J1939-71";
BA_ "SigType" SG_ 2566844670 EngPTOGvrnrCast_DecelerateSwitch 4;
BA_ "SPN" SG_ 2566844670 EngPTOGvrnrCast_DecelerateSwitch 983;
BA_ "SAEDocument" SG_ 2566844670 EngPTOGvrnrCast_DecelerateSwitch "J1939-71";
BA_ "SigType" SG_ 2566844670 EngPTOGovernorSetSwitch 4;
BA_ "SPN" SG_ 2566844670 EngPTOGovernorSetSwitch 984;
BA_ "SAEDocument" SG_ 2566844670 EngPTOGovernorSetSwitch "J1939-71";
BA_ "SigType" SG_ 2566844670 EngPTOGovernorResumeSwitch 4;
BA_ "SPN" SG_ 2566844670 EngPTOGovernorResumeSwitch 982;
BA_ "SAEDocument" SG_ 2566844670 EngPTOGovernorResumeSwitch "J1939-71";
BA_ "SigType" SG_ 2566844670 EngPTOGovernorEnableSwitch 4;
BA_ "SPN" SG_ 2566844670 EngPTOGovernorEnableSwitch 980;
BA_ "SAEDocument" SG_ 2566844670 EngPTOGovernorEnableSwitch "J1939-71";
BA_ "SigType" SG_ 2566844670 EngPTOGovernorAccelerateSwitch 4;
BA_ "SPN" SG_ 2566844670 EngPTOGovernorAccelerateSwitch 981;
BA_ "SAEDocument" SG_ 2566844670 EngPTOGovernorAccelerateSwitch "J1939-71";
BA_ "SigType" SG_ 2566844670 RmtPTOGvrnrPrprgrmmdSpdCtrlSwtch 4;
BA_ "SPN" SG_ 2566844670 RmtPTOGvrnrPrprgrmmdSpdCtrlSwtch 3447;
BA_ "SAEDocument" SG_ 2566844670 RmtPTOGvrnrPrprgrmmdSpdCtrlSwtch "J1939-71";
BA_ "SigType" SG_ 2566844670 AuxInputIgnoreSwitch 4;
BA_ "SPN" SG_ 2566844670 AuxInputIgnoreSwitch 3448;
BA_ "SAEDocument" SG_ 2566844670 AuxInputIgnoreSwitch "J1939-71";
BA_ "SPN" SG_ 2566770174 RearWasherFunction 2868;
BA_ "SAEDocument" SG_ 2566770174 RearWasherFunction "J1939-71";
BA_ "SPN" SG_ 2566770174 FrontOperatorWasherSwitch 2866;
BA_ "SAEDocument" SG_ 2566770174 FrontOperatorWasherSwitch "J1939-71";
BA_ "SPN" SG_ 2566770174 FrontNonoperatorWasherSwitch 2867;
BA_ "SAEDocument" SG_ 2566770174 FrontNonoperatorWasherSwitch "J1939-71";
BA_ "SigType" SG_ 2566770174 RearWiperDelayCtrl 1;
BA_ "SPN" SG_ 2566770174 RearWiperDelayCtrl 2871;
BA_ "SAEDocument" SG_ 2566770174 RearWiperDelayCtrl "J1939-71";
BA_ "SigType" SG_ 2566770174 FrontNonoperatorWiperDelayCtrl 1;
BA_ "SPN" SG_ 2566770174 FrontNonoperatorWiperDelayCtrl 2870;
BA_ "SAEDocument" SG_ 2566770174 FrontNonoperatorWiperDelayCtrl "J1939-71";
BA_ "SigType" SG_ 2566770174 FrontOperatorWiperDelayCtrl 1;
BA_ "SPN" SG_ 2566770174 FrontOperatorWiperDelayCtrl 2869;
BA_ "SAEDocument" SG_ 2566770174 FrontOperatorWiperDelayCtrl "J1939-71";
BA_ "SPN" SG_ 2566770174 RearWiperSwitch 2865;
BA_ "SAEDocument" SG_ 2566770174 RearWiperSwitch "J1939-71";
BA_ "SPN" SG_ 2566770174 FrontOperatorWiperSwitch 2863;
BA_ "SAEDocument" SG_ 2566770174 FrontOperatorWiperSwitch "J1939-71";
BA_ "SPN" SG_ 2566770174 FrontNonoperatorWiperSwitch 2864;
BA_ "SAEDocument" SG_ 2566770174 FrontNonoperatorWiperSwitch "J1939-71";
BA_ "SPN" SG_ 2566769662 EngAltDroopAuxInputSelect 2885;
BA_ "SAEDocument" SG_ 2566769662 EngAltDroopAuxInputSelect "J1939-71";
BA_ "SPN" SG_ 2566769662 EngAltDroopRemoteAccelSelect 2886;
BA_ "SAEDocument" SG_ 2566769662 EngAltDroopRemoteAccelSelect "J1939-71";
BA_ "SPN" SG_ 2566769662 EngAltDroopAccel2Select 2879;
BA_ "SAEDocument" SG_ 2566769662 EngAltDroopAccel2Select "J1939-71";
BA_ "SPN" SG_ 2566769662 EngAltDroopAccel1Select 2881;
BA_ "SAEDocument" SG_ 2566769662 EngAltDroopAccel1Select "J1939-71";
BA_ "SigType" SG_ 2566769662 EngAltRatingSelect 1;
BA_ "SPN" SG_ 2566769662 EngAltRatingSelect 2882;
BA_ "SAEDocument" SG_ 2566769662 EngAltRatingSelect "J1939-71";
BA_ "SigType" SG_ 2566769662 EngAltLowIdleSwitch 4;
BA_ "SPN" SG_ 2566769662 EngAltLowIdleSwitch 2883;
BA_ "SAEDocument" SG_ 2566769662 EngAltLowIdleSwitch "J1939-71";
BA_ "SigType" SG_ 2566769662 EngSynchronizationSwitch 4;
BA_ "SPN" SG_ 2566769662 EngSynchronizationSwitch 1377;
BA_ "SAEDocument" SG_ 2566769662 EngSynchronizationSwitch "J1939-71";
BA_ "SigType" SG_ 2566769662 EngAuxGovernorSwitch 4;
BA_ "SPN" SG_ 2566769662 EngAuxGovernorSwitch 2884;
BA_ "SAEDocument" SG_ 2566769662 EngAuxGovernorSwitch "J1939-71";
VAL_ 2348875518 EngRequestedTorqueHighResolution 7 "0875" 1 "0125" 0 "0000" 8 "1111  not available" ;
VAL_ 2348875518 TSC1CtrlPurpose 31 "P32  Temporary Power Train Control Original use of TSC1 Command" 5 "11110  P6P31  Reserved for SAE Assignment" 4 "P5  Engine Protection" 3 "P4  Road Speed Governor" 2 "P3  PTO Governor" 1 "P2  Cruise Control" 0 "P1  Accelerator Pedal/Operator Selection" ;
VAL_ 2348875518 TSC1TransRate 7 "Use standard TSC1 transmission rates of 10 ms to engine" 6 "20 ms transmission rate" 5 "50 ms transmission rate" 4 "100 ms transmission rate" 3 "250 ms transmission rate" 2 "500 ms transmission rate" 1 "750 ms transmission rate" 0 "1000 ms transmission rate" ;
VAL_ 2348875518 OverrideCtrlModePriority 3 "Low priority" 2 "Medium priority" 1 "High priority" 0 "Highest priority" ;
VAL_ 2348875518 EngRequestedSpeedCtrlConditions 2 "Stability Optimized for driveline engaged and/or in lockup condition 1 eg vehicle driveline" 3 "Stability Optimized for driveline engaged and/or in lockup condition 2 eg PTO driveline" 1 "Stability Optimized for driveline disengaged and nonlockup conditions" 0 "Transient Optimized for driveline disengaged and nonlockup conditions" ;
VAL_ 2348875518 EngOverrideCtrlMode 3 "Speed/torque limit control  Limit speed and/or torque based on the included limit values The speed limit governor is" 2 "Torque control  Control torque to the included desired torque value" 1 "Speed control  Govern speed to the included desired speed value" 0 "Override disabled  Disable any existing control commanded by the source of this command" ;
VAL_ 2566766846 TransitRunStatus 3 "Not available" 2 "Error condition" 0 "Off" ;
VAL_ 2566766846 VehicleUseStatus 3 "Not available" 2 "Error condition" 1 "Unauthorized use" 0 "Normal use" ;
VAL_ 2566766846 SilentAlarmStatus 3 "Not available" 2 "Error condition" 1 "On" 0 "Off" ;
VAL_ 2566765310 FareboxAlarmIdentifier 25 "Maintenance access out of service" 24 "Maintenance access in service considered an alarm condition" 23 "Paper currency jam cleared" 22 "Paper currency jam" 21 "Pass/transfer jam cleared" 20 "Pass/transfer jam" 19 "Farebox reset to automatic mode" 18 "Farebox set in manual bypass" 17 "Coin dejam operated" 16 "Card/pass box full" 15 "Card/pass box less than 75 full" 14 "Card/pass box 75 full" 13 "Currency box full" 12 "Currency box less than 75 full" 11 "Currency box 75 full" 10 "Coinbox full" 9 "Coinbox 75 full" 8 "Insufficient fare accepted" 7 "Cashbox opened in service considered an alarm condition" 6 "Cashbox door timeout" 5 "Cashbox restored" 4 "Cashbox removed" 3 "Probe completed" 2 "Probe started" 1 "Voltage restored" 0 "Voltage dropout" ;
VAL_ 2566765310 FareboxEmergencyStatus 3 "Not available" 2 "Error Condition" 1 "Emergency condition" 0 "Nonemergency condition" ;
VAL_ 2566765566 TransferType 5 "Out" 4 "In" 3 "West" 2 "East" 1 "South" 0 "North" ;
VAL_ 2566765566 TypeOfService 1 "Express service" 0 "Local service" ;
VAL_ 2566765566 PaymentDetails 5 "Card" 4 "Pass" 3 "Ticket" 2 "Token" 1 "Cash" 0 "Not an upgrade" ;
VAL_ 2566765566 TypeOfFare 6 "Pass B" 5 "Pass A" 4 "Ticket B" 3 "Ticket A" 2 "Token B" 1 "Token A" 0 "Cash/No detail" ;
VAL_ 2566765566 TransactionType 7 "Free" 6 "Transfer" 5 "Permit" 4 "Card" 3 "Pass" 2 "Ticket" 1 "Token" 0 "Cash" ;
VAL_ 2566765822 FarePresets 16 "to 11111111  Reserved for assignment" 0 "to 00001111  Agency defined" ;
VAL_ 2566765822 TripDirection 5 "Out" 4 "In" 3 "West" 2 "East" 1 "South" 0 "North" ;
VAL_ 2566765822 TripStatus 4 "Undefined" 3 "Undefined" 0 "Undefined" 6 "Layover end" 5 "Layover start" 2 "Trip end" 1 "Trip start" 7 "Undefined" ;
VAL_ 2566765822 FareboxServiceStatus 3 "Not available" 2 "Error Condition" 1 "Farebox in service" 0 "Farebox out of service" ;
VAL_ 2566766078 StrobeActivationCtrlStatus 3 "Not available" 2 "Error condition" 1 "Activate strobe" 0 "Deactivate strobe" ;
VAL_ 2566766078 TransitDoorEnable 3 "Not available" 2 "Error condition" 1 "Transit door status will override strobe activation" 0 "Ignore transit door status" ;
VAL_ 2566766078 PriorityOfRespSentByEmitter 15 "Not available" 14 "Error condition" 12 "to 1101  Reserved" 11 "Priority set by hardware to high priority" 10 "Priority set by hardware to probe priority" 9 "Priority set by hardware to low priority" 4 "to 1000  Reserved" 3 "High priority" 2 "Probe priority" 1 "Low priority" 0 "Reserved" ;
VAL_ 2566766078 IntrsctnPrmptionRequest_Response 3 "Not available" 2 "Error condition" 1 "Message is a response from the emitter" 0 "Message is a request directed to the emitter" ;
VAL_ 2566766078 TransitRouteIDUsage 3 "Not available" 2 "Error condition" 1 "Transit route ID used for interleaved data if range code not enabled" 0 "Transit route ID not used for interleaved data" ;
VAL_ 2566766078 RangeCodeEnable 3 "Not available" 2 "Error condition" 1 "Range code used for interleaved data" 0 "Range code not used for interleaved data" ;
VAL_ 2561605374 TireLocation 51 "Axle3_Position3" 50 "Axle3_Position2" 49 "Axle3_Position1" 35 "Axle2_Position3" 34 "Axle2_Position2" 33 "Axle2_Position1" 19 "Axle1_Position3" 18 "Axle1_Position2" 17 "Axle1_Position1" 1 "Axle0_Position1" 48 "Axle3_Position0" 32 "Axle2_Position0" 16 "Axle1_Position0" 0 "Axle0_Position0" ;
VAL_ 2566765054 TireLocation 51 "Axle3_Position3" 50 "Axle3_Position2" 49 "Axle3_Position1" 35 "Axle2_Position3" 34 "Axle2_Position2" 33 "Axle2_Position1" 19 "Axle1_Position3" 18 "Axle1_Position2" 17 "Axle1_Position1" 1 "Axle0_Position1" 48 "Axle3_Position0" 32 "Axle2_Position0" 16 "Axle1_Position0" 0 "Axle0_Position0" ;
VAL_ 2633922814 PCUTrilerTagOrPushSolenoidStatus 3 "Not available" 2 "Error" 1 "On" 0 "Off" ;
VAL_ 2633922814 PCUSupplySolenoidStatus 3 "Not available" 2 "Error" 1 "On" 0 "Off" ;
VAL_ 2633922814 PCUCtrlSolenoidStatus 3 "Not available" 2 "Error" 1 "On" 0 "Off" ;
VAL_ 2633922814 PCUDeflateSolenoidStatus 3 "Not available" 2 "Error" 1 "On" 0 "Off" ;
VAL_ 2633922814 TirePressSupplySwitchStatus 3 "Not available" 2 "Error" 1 "On" 0 "Off" ;
VAL_ 2633922814 PCUSteerSolenoidStatus 3 "Not available" 2 "Error" 1 "On" 0 "Off" ;
VAL_ 2633922814 PCUDriveSolenoidStatus 3 "Not available" 2 "Error" 1 "On" 0 "Off" ;
VAL_ 2633922814 DriveChannelMode 15 "Not available" 14 "Error Condition" 6 "Pressure Check" 5 "Deflate Wait  System will deflate when conditions allow" 4 "Inflate Wait  System will inflate when conditions allow" 3 "Confirm" 2 "Deflate" 1 "Inflate" 0 "Maintain" ;
VAL_ 2633922814 Trailer_tagChannelMode 15 "Not available" 14 "Error Condition" 6 "Pressure Check" 5 "Deflate Wait  System will deflate when conditions allow" 4 "Inflate Wait  System will inflate when conditions allow" 3 "Confirm" 2 "Deflate" 1 "Inflate" 0 "Maintain" ;
VAL_ 2633922814 SteerChannelMode 15 "Not available" 14 "Error Condition" 6 "Pressure Check" 5 "Deflate Wait  System will deflate when conditions allow" 4 "Inflate Wait  System will inflate when conditions allow" 3 "Confirm" 2 "Deflate" 1 "Inflate" 0 "Maintain" ;
VAL_ 2566845694 TirePressThresholdDetection_13 7 "NotAvailable" 6 "ErrorIndicator" 5 "NotDefined" 4 "ExtrmUndrPrssTrPrssrIsAtALvlWhr" 3 "UndrPrssTrPrssrIsLwrThnThPrssrD" 2 "NWrnngPrssTrPrssrIsWthnThThrshl" 1 "OvrPrssTrPrssrIsHghrThnThPrssrD" 0 "ExtrmOvrPrssTrPrssrIsAtALvlWhrT" ;
VAL_ 2566845694 TirePressThresholdDetection_12 7 "NotAvailable" 6 "ErrorIndicator" 5 "NotDefined" 4 "ExtrmUndrPrssTrPrssrIsAtALvlWhr" 3 "UndrPrssTrPrssrIsLwrThnThPrssrD" 2 "NWrnngPrssTrPrssrIsWthnThThrshl" 1 "OvrPrssTrPrssrIsHghrThnThPrssrD" 0 "ExtrmOvrPrssTrPrssrIsAtALvlWhrT" ;
VAL_ 2566845694 TirePressThresholdDetection_11 7 "NotAvailable" 6 "ErrorIndicator" 5 "NotDefined" 4 "ExtrmUndrPrssTrPrssrIsAtALvlWhr" 3 "UndrPrssTrPrssrIsLwrThnThPrssrD" 2 "NWrnngPrssTrPrssrIsWthnThThrshl" 1 "OvrPrssTrPrssrIsHghrThnThPrssrD" 0 "ExtrmOvrPrssTrPrssrIsAtALvlWhrT" ;
VAL_ 2566845694 TirePressThresholdDetection_10 7 "NotAvailable" 6 "ErrorIndicator" 5 "NotDefined" 4 "ExtrmUndrPrssTrPrssrIsAtALvlWhr" 3 "UndrPrssTrPrssrIsLwrThnThPrssrD" 2 "NWrnngPrssTrPrssrIsWthnThThrshl" 1 "OvrPrssTrPrssrIsHghrThnThPrssrD" 0 "ExtrmOvrPrssTrPrssrIsAtALvlWhrT" ;
VAL_ 2566845694 TirePressThresholdDetection_01 7 "NotAvailable" 6 "ErrorIndicator" 5 "NotDefined" 4 "ExtrmUndrPrssTrPrssrIsAtALvlWhr" 3 "UndrPrssTrPrssrIsLwrThnThPrssrD" 2 "NWrnngPrssTrPrssrIsWthnThThrshl" 1 "OvrPrssTrPrssrIsHghrThnThPrssrD" 0 "ExtrmOvrPrssTrPrssrIsAtALvlWhrT" ;
VAL_ 2566845694 CTIWheelSensorStatus_33 3 "NotSupported" 2 "NotDefined" 1 "On" 0 "Off_IsolatedFromCTIPressCtrl" ;
VAL_ 2566845694 CTIWheelSensorStatus_32 3 "NotSupported" 2 "NotDefined" 1 "On" 0 "Off_IsolatedFromCTIPressCtrl" ;
VAL_ 2566845694 CTIWheelSensorStatus_31 3 "NotSupported" 2 "NotDefined" 1 "On" 0 "Off_IsolatedFromCTIPressCtrl" ;
VAL_ 2566845694 CTIWheelSensorStatus_30 3 "NotSupported" 2 "NotDefined" 1 "On" 0 "Off_IsolatedFromCTIPressCtrl" ;
VAL_ 2566845694 CTIWheelSensorStatus_23 3 "NotSupported" 2 "NotDefined" 1 "On" 0 "Off_IsolatedFromCTIPressCtrl" ;
VAL_ 2566845694 CTIWheelSensorStatus_22 3 "NotSupported" 2 "NotDefined" 1 "On" 0 "Off_IsolatedFromCTIPressCtrl" ;
VAL_ 2566845694 CTIWheelSensorStatus_21 3 "NotSupported" 2 "NotDefined" 1 "On" 0 "Off_IsolatedFromCTIPressCtrl" ;
VAL_ 2566845694 CTIWheelSensorStatus_20 3 "NotSupported" 2 "NotDefined" 1 "On" 0 "Off_IsolatedFromCTIPressCtrl" ;
VAL_ 2566845694 CTIWheelSensorStatus_13 3 "NotSupported" 2 "NotDefined" 1 "On" 0 "Off_IsolatedFromCTIPressCtrl" ;
VAL_ 2566845694 CTIWheelSensorStatus_12 3 "NotSupported" 2 "NotDefined" 1 "On" 0 "Off_IsolatedFromCTIPressCtrl" ;
VAL_ 2566845694 CTIWheelSensorStatus_11 3 "NotSupported" 2 "NotDefined" 1 "On" 0 "Off_IsolatedFromCTIPressCtrl" ;
VAL_ 2566845694 CTIWheelSensorStatus_10 3 "NotSupported" 2 "NotDefined" 1 "On" 0 "Off_IsolatedFromCTIPressCtrl" ;
VAL_ 2566845694 CTIWheelSensorStatus_01 3 "NotSupported" 2 "NotDefined" 1 "On" 0 "Off_IsolatedFromCTIPressCtrl" ;
VAL_ 2566845694 CTIWheelEndElectricalFault_33 3 "NotSupported" 2 "Error" 1 "NotDefined" 0 "Ok" ;
VAL_ 2566845694 CTIWheelEndElectricalFault_32 3 "NotSupported" 2 "Error" 1 "NotDefined" 0 "Ok" ;
VAL_ 2566845694 CTIWheelEndElectricalFault_31 3 "NotSupported" 2 "Error" 1 "NotDefined" 0 "Ok" ;
VAL_ 2566845694 CTIWheelEndElectricalFault_30 3 "NotSupported" 2 "Error" 1 "NotDefined" 0 "Ok" ;
VAL_ 2566845694 CTIWheelEndElectricalFault_23 3 "NotSupported" 2 "Error" 1 "NotDefined" 0 "Ok" ;
VAL_ 2566845694 CTIWheelEndElectricalFault_22 3 "NotSupported" 2 "Error" 1 "NotDefined" 0 "Ok" ;
VAL_ 2566845694 CTIWheelEndElectricalFault_21 3 "NotSupported" 2 "Error" 1 "NotDefined" 0 "Ok" ;
VAL_ 2566845694 CTIWheelEndElectricalFault_20 3 "NotSupported" 2 "Error" 1 "NotDefined" 0 "Ok" ;
VAL_ 2566845694 CTIWheelEndElectricalFault_13 3 "NotSupported" 2 "Error" 1 "NotDefined" 0 "Ok" ;
VAL_ 2566845694 CTIWheelEndElectricalFault_12 3 "NotSupported" 2 "Error" 1 "NotDefined" 0 "Ok" ;
VAL_ 2566845694 CTIWheelEndElectricalFault_11 3 "NotSupported" 2 "Error" 1 "NotDefined" 0 "Ok" ;
VAL_ 2566845694 CTIWheelEndElectricalFault_10 3 "NotSupported" 2 "Error" 1 "NotDefined" 0 "Ok" ;
VAL_ 2566845694 CTIWheelEndElectricalFault_01 3 "NotSupported" 2 "Error" 1 "NotDefined" 0 "Ok" ;
VAL_ 2566845694 CTITireStatus_33 3 "NotSupported" 2 "Error" 1 "TireLeakDetected" 0 "Ok" ;
VAL_ 2566845694 CTITireStatus_32 3 "NotSupported" 2 "Error" 1 "TireLeakDetected" 0 "Ok" ;
VAL_ 2566845694 CTITireStatus_31 3 "NotSupported" 2 "Error" 1 "TireLeakDetected" 0 "Ok" ;
VAL_ 2566845694 CTITireStatus_30 3 "NotSupported" 2 "Error" 1 "TireLeakDetected" 0 "Ok" ;
VAL_ 2566845694 CTITireStatus_23 3 "NotSupported" 2 "Error" 1 "TireLeakDetected" 0 "Ok" ;
VAL_ 2566845694 CTITireStatus_22 3 "NotSupported" 2 "Error" 1 "TireLeakDetected" 0 "Ok" ;
VAL_ 2566845694 CTITireStatus_21 3 "NotSupported" 2 "Error" 1 "TireLeakDetected" 0 "Ok" ;
VAL_ 2566845694 CTITireStatus_20 3 "NotSupported" 2 "Error" 1 "TireLeakDetected" 0 "Ok" ;
VAL_ 2566845694 CTITireStatus_13 3 "NotSupported" 2 "Error" 1 "TireLeakDetected" 0 "Ok" ;
VAL_ 2566845694 CTITireStatus_12 3 "NotSupported" 2 "Error" 1 "TireLeakDetected" 0 "Ok" ;
VAL_ 2566845694 CTITireStatus_11 3 "NotSupported" 2 "Error" 1 "TireLeakDetected" 0 "Ok" ;
VAL_ 2566845694 CTITireStatus_10 3 "NotSupported" 2 "Error" 1 "TireLeakDetected" 0 "Ok" ;
VAL_ 2566845694 CTITireStatus_01 3 "NotSupported" 2 "Error" 1 "TireLeakDetected" 0 "Ok" ;
VAL_ 2566845694 TirePressThresholdDetection_33 7 "NotAvailable" 6 "ErrorIndicator" 5 "NotDefined" 4 "ExtrmUndrPrssTrPrssrIsAtALvlWhr" 3 "UndrPrssTrPrssrIsLwrThnThPrssrD" 2 "NWrnngPrssTrPrssrIsWthnThThrshl" 1 "OvrPrssTrPrssrIsHghrThnThPrssrD" 0 "ExtrmOvrPrssTrPrssrIsAtALvlWhrT" ;
VAL_ 2566845694 TirePressThresholdDetection_32 7 "NotAvailable" 6 "ErrorIndicator" 5 "NotDefined" 4 "ExtrmUndrPrssTrPrssrIsAtALvlWhr" 3 "UndrPrssTrPrssrIsLwrThnThPrssrD" 2 "NWrnngPrssTrPrssrIsWthnThThrshl" 1 "OvrPrssTrPrssrIsHghrThnThPrssrD" 0 "ExtrmOvrPrssTrPrssrIsAtALvlWhrT" ;
VAL_ 2566845694 TirePressThresholdDetection_31 7 "NotAvailable" 6 "ErrorIndicator" 5 "NotDefined" 4 "ExtrmUndrPrssTrPrssrIsAtALvlWhr" 3 "UndrPrssTrPrssrIsLwrThnThPrssrD" 2 "NWrnngPrssTrPrssrIsWthnThThrshl" 1 "OvrPrssTrPrssrIsHghrThnThPrssrD" 0 "ExtrmOvrPrssTrPrssrIsAtALvlWhrT" ;
VAL_ 2566845694 TirePressThresholdDetection_30 7 "NotAvailable" 6 "ErrorIndicator" 5 "NotDefined" 4 "ExtrmUndrPrssTrPrssrIsAtALvlWhr" 3 "UndrPrssTrPrssrIsLwrThnThPrssrD" 2 "NWrnngPrssTrPrssrIsWthnThThrshl" 1 "OvrPrssTrPrssrIsHghrThnThPrssrD" 0 "ExtrmOvrPrssTrPrssrIsAtALvlWhrT" ;
VAL_ 2566845694 TirePressThresholdDetection_23 7 "NotAvailable" 6 "ErrorIndicator" 5 "NotDefined" 4 "ExtrmUndrPrssTrPrssrIsAtALvlWhr" 3 "UndrPrssTrPrssrIsLwrThnThPrssrD" 2 "NWrnngPrssTrPrssrIsWthnThThrshl" 1 "OvrPrssTrPrssrIsHghrThnThPrssrD" 0 "ExtrmOvrPrssTrPrssrIsAtALvlWhrT" ;
VAL_ 2566845694 TirePressThresholdDetection_22 7 "NotAvailable" 6 "ErrorIndicator" 5 "NotDefined" 4 "ExtrmUndrPrssTrPrssrIsAtALvlWhr" 3 "UndrPrssTrPrssrIsLwrThnThPrssrD" 2 "NWrnngPrssTrPrssrIsWthnThThrshl" 1 "OvrPrssTrPrssrIsHghrThnThPrssrD" 0 "ExtrmOvrPrssTrPrssrIsAtALvlWhrT" ;
VAL_ 2566845694 TirePressThresholdDetection_21 7 "NotAvailable" 6 "ErrorIndicator" 5 "NotDefined" 4 "ExtrmUndrPrssTrPrssrIsAtALvlWhr" 3 "UndrPrssTrPrssrIsLwrThnThPrssrD" 2 "NWrnngPrssTrPrssrIsWthnThThrshl" 1 "OvrPrssTrPrssrIsHghrThnThPrssrD" 0 "ExtrmOvrPrssTrPrssrIsAtALvlWhrT" ;
VAL_ 2566845694 TirePressThresholdDetection_20 7 "NotAvailable" 6 "ErrorIndicator" 5 "NotDefined" 4 "ExtrmUndrPrssTrPrssrIsAtALvlWhr" 3 "UndrPrssTrPrssrIsLwrThnThPrssrD" 2 "NWrnngPrssTrPrssrIsWthnThThrshl" 1 "OvrPrssTrPrssrIsHghrThnThPrssrD" 0 "ExtrmOvrPrssTrPrssrIsAtALvlWhrT" ;
VAL_ 2566845694 TirePressThresholdDetection_00 7 "NotAvailable" 6 "ErrorIndicator" 5 "NotDefined" 4 "ExtrmUndrPrssTrPrssrIsAtALvlWhr" 3 "UndrPrssTrPrssrIsLwrThnThPrssrD" 2 "NWrnngPrssTrPrssrIsWthnThThrshl" 1 "OvrPrssTrPrssrIsHghrThnThPrssrD" 0 "ExtrmOvrPrssTrPrssrIsAtALvlWhrT" ;
VAL_ 2566845694 CTIWheelSensorStatus_00 3 "NotSupported" 2 "NotDefined" 1 "On" 0 "Off_IsolatedFromCTIPressCtrl" ;
VAL_ 2566845694 CTIWheelEndElectricalFault_00 3 "NotSupported" 2 "Error" 1 "NotDefined" 0 "Ok" ;
VAL_ 2566845694 CTITireStatus_00 3 "NotSupported" 2 "Error" 1 "TireLeakDetected" 0 "Ok" ;
VAL_ 2566821630 EngTrbWstgateActuator1TempStatus 7 "Not available" 6 "Error" 5 "Not Defined" 4 "Low Most severe" 3 "Low Least severe" 2 "In Range" 1 "High Least severe" 0 "High Most severe" ;
VAL_ 2365484286 VehicleOverspeed 3 "Not available" 2 "Error" 1 "Overspeed" 0 "No overspeed" ;
VAL_ 2365484286 VehicleMotion 3 "Not available" 2 "Error" 1 "Vehicle motion detected" 0 "Vehicle motion not detected" ;
VAL_ 2365484286 DirectionIndicator 3 "Not available" 2 "Error" 1 "Reverse" 0 "Forward" ;
VAL_ 2365484286 TachographPerformance 3 "Not available" 2 "Error" 1 "Performance analysis" 0 "Normal performance" ;
VAL_ 2365484286 HandlingInformation 3 "Not available" 2 "Error" 1 "Handling information" 0 "No handling information" ;
VAL_ 2365484286 SystemEvent 3 "Not available" 2 "Error" 1 "Tachograph event" 0 "No tachograph event" ;
VAL_ 2365484286 DriverCardDriver2 3 "Not available" 2 "Error" 1 "Driver card present" 0 "Driver card not present" ;
VAL_ 2365484286 Driver2TimeRelatedStates 15 "Not available" 14 "Error" 13 "Other" 6 "Limit 6  16 h reached" 5 "Limit 5  15 min before 16 h not having 8h rest during the last 24h" 4 "Limit 4  9 h reached" 3 "Limit 3  15 min before 9 h" 2 "Limit 2  4  h reached" 1 "Limit 1  15 min before 4  h" 0 "Normal/No limits reached" ;
VAL_ 2365484286 DriverCardDriver1 3 "Not available" 2 "Error" 1 "Driver card present" 0 "Driver card not present" ;
VAL_ 2365484286 Driver1TimeRelatedStates 15 "Not available" 14 "Error" 13 "Other" 6 "Limit 6  16 h reached" 5 "Limit 5  15 min before 16 h not having 8h rest during the last 24h" 4 "Limit 4  9 h reached" 3 "Limit 3  15 min before 9 h" 2 "Limit 2  4  h reached" 1 "Limit 1  15 min before 4  h" 0 "Normal/No limits reached" ;
VAL_ 2365484286 Driver2WorkingState 7 "Not available" 6 "Error" 3 "Drive  behind wheel" 2 "Work  loading unloading working in an office" 1 "Driver available  short break" 0 "Rest  sleeping" ;
VAL_ 2365484286 Driver1WorkingState 7 "Not available" 6 "Error" 3 "Drive  behind wheel" 2 "Work  loading unloading working in an office" 1 "Driver available  short break" 0 "Rest  sleeping" ;
VAL_ 2348941054 TransMode8 3 "Take no action" 2 "Reserved" 1 "Enable" 0 "Disable" ;
VAL_ 2348941054 TransMode7 3 "Take no action" 2 "Reserved" 1 "Enable" 0 "Disable" ;
VAL_ 2348941054 TransMode6 3 "Take no action" 2 "Reserved" 1 "Enable" 0 "Disable" ;
VAL_ 2348941054 TransMode5 3 "Take no action" 2 "Reserved" 1 "Enable" 0 "Disable" ;
VAL_ 2348941054 TrnsShftSlectorDisplayModeSwitch 3 "Not available" 2 "Error" 1 "On" 0 "Off" ;
VAL_ 2348941054 TransRequestedLaunchGear 15 "Not Available" 14 "Error" 13 "Reserved" 12 "Launch the vehicle in Reverse 4" 11 "Launch the vehicle in Reverse 3" 10 "Launch the vehicle in Reverse 2" 9 "Launch the vehicle in Reverse 1" 8 "Launch the vehicle in 8th gear" 7 "Launch the vehicle in 7th gear" 6 "Launch the vehicle in 6th gear" 5 "Launch the vehicle in 5th gear" 4 "Launch the vehicle in 4th gear" 3 "Launch the vehicle in 3rd gear" 2 "Launch the vehicle in 2nd gear" 1 "Launch the vehicle in 1st gear" 0 "No specific launch gear requested use default launch gear" ;
VAL_ 2348941054 TransMode4 3 "Take no action" 2 "Reserved" 1 "Enable" 0 "Disable" ;
VAL_ 2348941054 TransMode3 3 "Take no action" 2 "Reserved" 1 "Enable" 0 "Disable" ;
VAL_ 2348941054 TransMode2 3 "Take no action" 2 "Reserved" 1 "Enable" 0 "Disable" ;
VAL_ 2348941054 TransMode1 3 "Take no action" 2 "Reserved" 1 "Enable" 0 "Disable" ;
VAL_ 2348941054 DisengageDiffLockRqCentralRear 3 "Take no action" 2 "Reserved" 1 "Disengage differential lock" 0 "Engage differential lock" ;
VAL_ 2348941054 DisengageDiffLockRqCentralFront 3 "Take no action" 2 "Reserved" 1 "Disengage differential lock" 0 "Engage differential lock" ;
VAL_ 2348941054 DisengageDiffLockRqCentral 3 "Take no action" 2 "Reserved" 1 "Disengage differential lock" 0 "Engage differential lock" ;
VAL_ 2348941054 DisengageDiffLockRqRearAxle2 3 "Take no action" 2 "Reserved" 1 "Disengage differential lock" 0 "Engage differential lock" ;
VAL_ 2348941054 DisengageDiffLockRqRearAxle1 3 "Take no action" 2 "Reserved" 1 "Disengage differential lock" 0 "Engage differential lock" ;
VAL_ 2348941054 DisengageDiffLockRqFrontAxle2 3 "Take no action" 2 "Reserved" 1 "Disengage differential lock" 0 "Engage differential lock" ;
VAL_ 2348941054 DisengageDiffLockRqFrontAxle1 3 "Take no action" 2 "Reserved" 1 "Disengage differential lock" 0 "Engage differential lock" ;
VAL_ 2348941054 TransReverseGearShiftInhibitRq 3 "Take no action" 2 "Reserved" 1 "Inhibit shifts into Reverse gear and shift transmission to Neutral if already in Reverse or attempting to shift to" 0 "Allow shifts into Reverse gear" ;
VAL_ 2348941054 DisengageDrivelineRq 2 "Reserved" 3 "Take no action" 1 "Disengage driveline" 0 "Allow driveline engagement" ;
VAL_ 2348941054 TrnsTrqeConverterLockupDisableRq 3 "Take no action" 2 "Reserved" 1 "Disable torque converter lockup" 0 "Allow torque converter lockup" ;
VAL_ 2348941054 TransGearShiftInhibitRq 2 "Reserved" 3 "Take no action leave function as is" 1 "Gear shifts are inhibited enable function" 0 "Gear shifts are allowed disable function" ;
VAL_ 2566839806 EngTurboOilLevelSwitch 3 "Not available" 2 "Error" 1 "Oil present at turbocharger" 0 "No oil present at turbocharger" ;
VAL_ 2566841598 PTOShutdownHasShutdownEng 3 "Not available" 2 "Error" 1 "Yes" 0 "No" ;
VAL_ 2566841598 EngAirShutoffStatus 3 "Not Available" 2 "Error" 1 "Air flow restricted" 0 "Air flow allowed to engine" ;
VAL_ 2566841598 EngOverspeedTest 3 "Not Available" 2 "Reserved" 1 "Engine Overspeed Test Active" 0 "Engine Overspeed Test Not Active" ;
VAL_ 2566841598 EngAirShutoffCmdStatus 0 "Air Shutoff Disabled not attempting to shutoff engine air supply" 3 "Not Available" 2 "Reserved" 1 "Air Shutoff Enabled attempting to shutoff engine air supply" ;
VAL_ 2566841598 EngAlarmOutputCmdStatus 3 "Not Available" 2 "Reserved" 1 "Engine Alarm Output Command Active" 0 "Engine Alarm Output Command Not Active" ;
VAL_ 2566841598 EngAlarmAcknowledge 3 "Not Available" 2 "Error" 1 "Engine Alarm Acknowledge Active" 0 "Engine Alarm Acknowledge Not Active" ;
VAL_ 2566841598 EngProtectionSystemConfig 3 "Not available" 2 "Error" 1 "Enabled in calibration" 0 "Disabled in calibration" ;
VAL_ 2566841598 EngProtectionSystemTimerState 3 "Not available" 2 "Error" 1 "Active" 0 "Inactive" ;
VAL_ 2566841598 EngProtectionSystemTimerOverride 3 "Not available" 2 "Error" 1 "Active" 0 "Inactive" ;
VAL_ 2566841598 EngPrtctnSystmApprachingShutdown 3 "Not available" 2 "Error" 1 "Approaching" 0 "Not approaching" ;
VAL_ 2566841598 EngPrtectionSystemHasShutdownEng 3 "Not available" 2 "Error" 1 "Yes" 0 "No" ;
VAL_ 2566841598 EngWaitToStartLamp 3 "Not available" 2 "Error" 1 "On" 0 "Off" ;
VAL_ 2566841598 RefrigerantHighPressSwitch 3 "Not available" 2 "Error" 1 "Pressure too high compressor clutch may be disengaged" 0 "Pressure normal" ;
VAL_ 2566841598 RefrigerantLowPressSwitch 3 "Not available" 2 "Error" 1 "Pressure too low compressor clutch may be disengaged" 0 "Pressure normal" ;
VAL_ 2566841598 A_CHighPressFanSwitch 3 "Not available" 2 "Error" 1 "Pressure high fan may be engaged" 0 "Pressure normal" ;
VAL_ 2566841598 EngIdleShutdownTimerFunction 3 "Not available" 2 "Error" 1 "Enabled in calibration" 0 "Disabled in calibration" ;
VAL_ 2566841598 EngIdleShutdownTimerState 3 "Not available" 2 "Error" 1 "Active" 0 "Inactive" ;
VAL_ 2566841598 EngIdleShutdownTimerOverride 3 "Not available" 2 "Error" 1 "Active" 0 "Inactive" ;
VAL_ 2566841598 EngIdleShutdownDriverAlertMode 3 "Not available" 2 "Error" 1 "Active" 0 "Inactive" ;
VAL_ 2566841598 EngIdleShutdownHasShutdownEng 3 "Not available" 2 "Error" 1 "Yes" 0 "No" ;
VAL_ 2633895166 VehicleSystem5 127 "Not Available" 0 "Ind. Process Control Stationary" ;
VAL_ 2633895166 VehicleSystem4 100 "Deck/Cargo/Fishing equip. sys" 90 "Environmental (HVAC) Systems" 80 "Instrumentation/General Systems" 70 "Communications Systems" 60 "Navigation Systems" 50 "Propulsion Systems" 40 "Steering Systems" 30 "Power Mgmt and lighting systems" 25 "Gateway" 20 "Safety Systems" 10 "System Tools" 127 "Not Available" 0 "Non-specific System" ;
VAL_ 2633895166 VehicleSystem3 8 "Grader" 7 "Four Wheel Drive Loader" 6 "Forklift" 5 "Excavator" 4 "Crawler" 3 "Backhoe" 2 "Articulated Dump Truck" 1 "Skid Steer Loader" 127 "Not Available" 0 "Non-specific System" ;
VAL_ 2633895166 VehicleSystem2 16 "Skidder" 15 "Earth Work" 14 "Special Crops" 13 "Powered Auxiliary Device" 12 "Farm Yard Operations" 11 "Transport/Trailer" 10 "Irrigation" 9 "Forage" 8 "Root Harvesters" 7 "Harvesters" 6 "Sprayers" 5 "Fertilizers" 4 "Planters/Seeders" 3 "Secondary Tillage" 2 "Tillage" 1 "Tractor" 127 "Not Available" 0 "Non-specific System" ;
VAL_ 2633895166 VehicleSystem1 2 "Trailer" 1 "Tractor" 127 "Not Available" 0 "Non-specific System" ;
VAL_ 2633895166 IndustryGroup 6 "Reserved for SAE" 7 "Reserved for SAE" 5 "IndustrialProcessCtrlStationary" 4 "Marine" 3 "Construction" 2 "Agricultural and Forestry" 1 "On-Highway" 0 "Global" ;
VAL_ 2633895166 VehicleSystem 0 "Non-specific System" 127 "Not Available" ;
VAL_ 2633895166 Function 127 "Reserved" 126 "Reserved" 125 "Reserved" 124 "Reserved" 123 "Reserved" 122 "Reserved" 121 "Reserved" 120 "Reserved" 119 "Reserved" 118 "Reserved" 117 "Reserved" 116 "Reserved" 115 "Reserved" 114 "Reserved" 113 "Reserved" 112 "Reserved" 111 "Reserved" 110 "Reserved" 109 "Reserved" 108 "Reserved" 107 "Reserved" 106 "Reserved" 105 "Reserved" 104 "Reserved" 103 "Reserved" 102 "Reserved" 101 "Reserved" 42 "Water Pump Control" 41 "Lighting - Operator Controls" 40 "Seat Control" 39 "Ignition Control Module" 38 "Tire Pressure Control" 37 "Cab Controller" 36 "Pneumatic - System Controller" 35 "Suspension - System Controller" 34 "Hydraulic Pump Controller" 33 "System Monitor" 32 "Headway Controller" 31 "Propulsion Battery Charger" 30 "Management Computer" 29 "Virtual Terminal (in cab)" 28 "Off Vehicle Gateway" 27 "Power TakeOff (Secondary or Front)" 26 "Body Controller" 25 "Network Interconnect ECU" 24 "Vehicle Security" 23 "Vehicle Navigation" 22 "Aerodynamic Control" 21 "Cab Climate Control" 20 "Trip Recorder" 19 "Instrument Cluster" 18 "Suspension - Drive Axle" 17 "Suspension - Steer Axle" 16 "Steering Controller" 15 "Fuel System" 14 "Cruise Control" 13 "Retarder - Driveline" 12 "Retarder - Engine" 11 "Brakes - Drive Axle" 10 "Brakes - Steer Axle" 9 "Brakes - System Controller" 8 "Axle - Drive" 7 "Axle - Steering" 6 "Power TakeOff - (Main or Rear)" 5 "Shift Control/Console" 4 "Battery Pack Monitor" 3 "Transmission" 2 "Electric Propulsion Control" 1 "Auxiliary Power Unit (APU)" 0 "Engine" 100 "Reserved" 99 "Reserved" 98 "Reserved" 97 "Reserved" 96 "Reserved" 95 "Reserved" 94 "Reserved" 93 "Reserved" 92 "Reserved" 91 "Reserved" 90 "Reserved" 89 "Reserved" 88 "Reserved" 87 "Reserved" 86 "Reserved" 85 "Reserved" 84 "Reserved" 83 "Reserved" 82 "Reserved" 81 "Reserved" 80 "Reserved" 79 "Reserved" 78 "Reserved" 77 "Reserved" 76 "Reserved" 75 "Supplemental Fan" 74 "Lubrication System" 73 "Rollover Detection Control" 72 "Coolant Valve Controller" 71 "Transfer Case Control" 70 "Auxiliary Regeneration Device" 69 "Engine Emission Aftertreatement System" 68 "Aftertreatment system gas measurement" 67 "Electrical System Controller" 66 "I/O Controller" 65 "Gas Flow Measurement" 64 "Endurance Braking" 63 "Engine Valve Controller" 62 "On-Board Diagnostic Unit" 61 "File Server/Printer" 60 "Cab Display" 59 "Starter" 58 "Fan Drive Control" 57 "Steering Column Unit" 56 "Communications Unit, Radio" 55 "Communications Unit, Satellite" 54 "Communications Unit, Cellular" 53 "Alternator/Charging System" 52 "Chassis Controller" 51 "Forward-Looking Collision Warning System" 50 "Auxiliary Heater" 49 "Clutch/Converter Control" 48 "Ramp Control" 47 "Information System Controller" 46 "Oil Sensor Unit" 45 "Vehicle Dynamic Stability Control" 44 "Exhaust Emission Control" 43 "Transmission Display" ;
VAL_ 2633895166 ManufacturerCode 381 "B&G" 374 "Northern Lights" 373 "Electronic Design" 371 "Delphi" 370 "Heinzmann GmbH & Co. KG" 369 "Power Torque Engineering Ltd" 368 "HANSENHOF_electronic" 367 "Fliegl Agrartechnik" 366 "Viewnyx Corp." 365 "Digi-Star, LLC" 364 "OEM Controls Inc." 363 "BEI Duncan" 362 "Alois Poettinger Maschinenfabrik GmbH" 361 "InMach" 360 "HJS Fahrzeugtechnik GmbH & Co KG" 359 "Ludwig Bergmann GmbH" 358 "Victron Energy BV" 357 "Hardi International A/S" 356 "Fischer Panda Generators, Inc" 355 "Mastervolt International B.V." 354 "Junkkari OY" 353 "Hegemon Electronics, Inc." 352 "SAME DEUTZ-FAHR" 351 "Thrane & Thrane" 350 "Noris Marine Systems GmbH & Co KG" 349 "Suonentiet" 348 "Amazonen Werke H. Dreyer" 347 "Honeywell" 346 "Control Solutions" 345 "Korean Maritime University" 344 "Parvus Corporation" 343 "Baumer Group" 342 "THOMAS MAGNETE GmbH" 341 "Boning GmbH & Co" 340 "Continental AG" 339 "Competence Center ISOBUS e.V." 338 "GRAF-SYTECO" 337 "Carraro S.p.A." 336 "APE s.r.o." 335 "Evo Electric Ltd" 334 "Takata-Petri AG" 333 "Hadley Products Corporation" 332 "HWH Corporation" 331 "Horton, Inc." 330 "Kidde Aerospace and Defense" 329 "Deif A/S" 328 "Qwerty Electronik AB" 252 "Sensor-Technik Wiedemann GmbH" 251 "German Agricultural Society" 250 "Kuhn Group" 249 "Schaltbau GmbH" 233 "Yacht Monitoring Solutions Inc." 232 "TSD Integrated Controls" 1863 "Thomas G. Faria Co." 1862 "Sanshin" 1861 "Vector CANtech" 1860 "MMP" 1859 "Kvasar AB" 1858 "Litton" 1857 "Simrad" 1856 "Trimble" 1855 "Furuno USA" 1854 "Northstar Technologies" 1853 "Japan Radio Co." 1852 "Navionics" 1851 "Raymarine" 1850 "Teleflex" 222 "Generac Power Systems, Inc." 221 "SiE" 220 "Beede Electrical Instrument Company, Inc." 219 "Cat OEM Solutions" 218 "Gits Manufacturing Company" 217 "RM Michaelides Software & Elektronik GmbH" 216 "Paneltronics Inc." 215 "Aetna Engineering/Fireboy-Xintex" 214 "MC elettronica Srl" 213 "CNH Belgium N.V." 212 "Sure Power Industries, Inc." 211 "DNA Group" 210 "Iteris, Inc." 209 "Bell Equip. Co. SA (PTY) LTD" 208 "Drew Technologies, Inc." 207 "Otto Engineering" 206 "port GmbH" 205 "SmarTire Systems Inc" 204 "The Morey Corporation" 203 "MILtronik GmbH" 202 "Curtis Instruments, Inc." 201 "Disenos y Tecnologia S.A." 200 "MGM Brakes" 199 "Actia Corp." 198 "Mystic Valley Communications" 197 "Mechron Power Systems" 196 "LEMKEN GmbH & Co. KG" 195 "General Engine Products" 194 "TriMark Corporation" 193 "Nobletec" 192 "Floscan" 191 "XATA Corporation" 190 "Hella KGaA Hueck & Co." 189 "QUALCOMM" 188 "EMP Corp." 187 "Air-Weigh" 186 "Altronic, Inc." 185 "Beede Electrical Instrument Company" 184 "EIA Electronics" 183 "KDS Controls, Inc." 182 "Vehicle Systems Engineering B.V." 181 "Coretronics, Inc." 180 "Smart Power Systems" 179 "TeeJet Technologies Denmark" 178 "Siemens VDO Automotive AG" 177 "Diagnostic System Associates" 176 "Moritz Aerospace" 175 "Veris Technologies, Inc." 174 "AB Volvo Penta" 173 "Ryeso, Inc." 172 "Yanmar Marine USA" 171 "Wachendorff Elektronik GmbH & Co. KG" 170 "Computronics Corporation Ltd." 169 "Marlin Technologies Inc." 168 "Xantrex" 167 "JLG Industries Inc." 166 "Phoenix International" 165 "CPAC Systems AB" 164 "DaimlerChrysler Off-Highway" 163 "BRP Inc." 162 "Axiomatic Technologies" 161 "Offshore Systems (UK) Limited" 160 "Nido" 159 "NTech Industries Inc." 158 "Firestone Industrial Products Company" 157 "ISSPRO Inc." 156 "ITT Industries - Cannon" 155 "Vetronix Corporation" 154 "Westerbeke Corporation" 153 "Woodward, Industrial Controls Division" 152 "elobau GmbH & Co. KG" 151 "Raven Industries Inc. - Flow Controls Division" 150 "Fleetguard" 149 "Holset" 148 "Blue Water Data, Inc." 147 "Nautibus Electronic GmbH" 146 "Maxima Technologies" 145 "MurCal Controls" 144 "Mercury Marine" 143 "W. Gmeiner GmbH & Co." 142 "TRW Automotive (Commercial Steering Systems)" 141 "Thales Navigation Ltd." 140 "Lowrance Electronics, Inc." 139 "Caterpillar Trimble Control Technologies (CTCT), LLC" 138 "Georg Fritzmeier GmbH & Co. KG" 137 "Maretron" 136 "Komatsu Ltd." 135 "Airmar Technology Corporation" 134 "Iris Technology Ltd." 133 "Bucher Schoerling GmbH" 132 "Mulag-Fahrzeugwerk" 131 "ITT Industries" 130 "Nido - Universal Machines B.V." 129 "OMNEX Control Systems, Inc." 128 "Gerhard Duecker GmbH & Co. KG" 127 "Holland USA" 126 "Driver Tech" 125 "Nevada Automotive Test Center" 124 "Hydac Electronic" 123 "Basler Electric" 122 "FG Wilson (Engineering) Limited" 121 "HED (Hydro Electronic Devices, Inc.)" 120 "RDS Technology Ltd." 119 "IntegriNautics" 118 "Intron GmbH" 117 "HUSCO International" 116 "BEELINE Technologies" 115 "NACCO Materials Handling Group, Inc." 114 "EControls, Inc." 113 "Stress-Tek, Inc." 112 "MECALAC" 111 "Maschinenfabrik Bernhard Krone GmbH" 110 "EPIQ Sensor-Nite" 109 "TeeJet Technologies Denmark" 108 "WTK-Elecktronik GmbH" 107 "Grimme Landmaschinen GmbH & Co. KG" 106 "BAE Systems Controls, Inc." 105 "Kiepe Elektrik GmbH & Co. KG" 104 "Claas Selbstfahrende Erntemaschinen GmbH" 103 "Agrocom GmbH & Co. Agrarsystem KG" 102 "AGCO GmbH & Co." 101 "Sensoria" 100 "VDO Technik AG" 99 "International Transmissions Ltd (ITL)" 98 "Mueller-Elektronik GmbH & Co." 97 "Ag Leader Technology, Inc." 96 "Mech@tronic IT GmbH" 95 "Pacific Insight Electronics Corp." 94 "CNH Global N.V." 93 "Perkins Engines Company Ltd." 92 "Ag-Chem Equipment Co., Inc." 91 "BSG Bodensee Steuergeraete GmbH" 90 "Knorr-Bremse SfN GmbH" 89 "Kverneland Group, Electronics Division" 88 "Satloc Precision GPS" 87 "J.C. Bamford Excavators Ltd (JCB)" 86 "C.E. Niehoff & Company" 85 "Kohler Co." 84 "New Holland UK Limited" 83 "Eaton VORAD Technologies" 82 "Bobcat/Ingersoll-Rand" 81 "Fire Research Corp" 80 "Twin Disc, Inc." 79 "Daimler Benz AG - Engine Division (PBM)" 78 "Frank W. Murphy Manufacturing, Inc." 77 "Deere Power Systems Group" 76 "unused" 75 "Deere & Co. Agricultural Division" 74 "Eaton Axle-Brake Division" 73 "LeTourneau, Inc." 72 "Sisu Corporation" 71 "Vansco Electronics Ltd." 70 "Flex-Coil Limited" 69 "Trimble Navigation" 68 "Scania" 67 "Funk Manufacturing Company" 66 "John Deere Construction Equipment Division" 65 "MAN Nutzfahrzeuge AG" 64 "unused" 63 "ZF Industries Inc." 62 "Wabco" 61 "Volvo Truck Corp." 60 "Volvo Trucks North America Inc." 59 "VES Inc." 58 "SPX Corporation, OTC Division" 57 "Sauer-Danfoss Co." 56 "SAIC" 55 "Ryder System Inc." 54 "Meritor Wabco" 53 "Continental Automotive Systems US, Inc." 52 "Meritor Automotive, Inc." 51 "Robert Bosch GmbH" 50 "Robert Bosch Corp" 49 "RE America Inc." 48 "Pollak Alphabet" 47 "Phillips Semiconductor" 46 "Parasoft Computing Solutions" 45 "PACCAR" 44 "Nippondenso Co. Ltd." 43 "International Truck and Engine Corp. Vehicle Electronics" 42 "International Truck and Engine Corp. Engine Electronics" 41 "Motorola Inc." 40 "Motorola AIEG Inc." 39 "Microfirm Inc." 38 "Micro Processor Systems Inc." 37 "Mack Trucks Inc." 36 "Lucas Ltd." 35 "Kenworth Truck Co." 34 "Kelsey Hayes Co." 33 "John Deere" 32 "Jacobs Vehicle Systems" 31 "J Pollak Corp." 30 "Isuzu Motors Ltd." 29 "Hino Motors Ltd." 28 "Grote Ind. Inc." 27 "GMC" 26 "General Motors Corp., Service Technology Group" 25 "Daimler Trucks North America LLC" 24 "Ford Motor Co., Vehicle Controls" 23 "Ford Motor Co., Heavy Truck" 22 "Ford Motor Co., Electronic Concepts $ Systems" 21 "Echilin Inc., Midland Brake Inc." 20 "Eaton Ltd" 19 "Eaton Corp. Trucking Info Services" 18 "Eaton Corp, Transmission Division" 17 "Eaton Corp. Res & Dev" 16 "Eaton Corp." 15 "Dickey-John Corp." 14 "Detroit Diesel Corporation" 13 "Delco Electronics" 12 "Deere & Company, Precision Farming" 11 "Dearborn Group Inc." 10 "Cummins Engine Co." 9 "Chrysler Corp." 8 "Caterpillar Inc." 7 "Case Corp." 6 "Berifors Electronics AB" 5 "AMP Inc." 4 "Ametek-Dixson" 3 "Ametek, US Gauge Division" 2 "Allison Transmission, GMC" 1 "Allied Signal Inc." 0 "Reserved" 231 "Topcon Positioning Systems, Inc." 230 "Saucon Technologies" 229 "Garmin International Inc." 228 "ZF Marine Electronics" 227 "Lykketronic A/S" 226 "Monaco Coach Corporation" 225 "SKF" 224 "EMMI Network, S.L." 223 "Vaueo Retarder Co., Ltd." 263 "IMMI" 262 "HydraForce, Inc" 261 "Red Dot Corporation" 260 "Reichhardt GmbH" 259 "Jetter AG" 258 "ARAG" 257 "Honda Motor Co., Ltd" 256 "Tyco Electronics AMP" 255 "MEAS France" 254 "GE Sensing" 253 "Mobile Control Systems" 298 "Holley Performance" 297 "Zonar Systems Inc" 296 "micro dynamics GmbH" 295 "BEP Marine" 294 "Grayhill Inc." 293 "Spyder Controls Corp." 292 "IKUSI - Angel Iglesias S.A." 291 "Groeneveld Transport Efficiency BV" 290 "Kuebler GmbH" 289 "Watlow" 288 "Mitsubishi FUSO Truck & Bus Corp." 287 "NTech Industries, Inc" 286 "Coelmo srl" 285 "Sea Recovery Corp" 284 "Mobile Tech Chile" 283 "CWF Hamilton & Co Ltd" 282 "Medallion Instrumentation Systems" 281 "Precision Governors LLC" 311 "Patrick Power Products" 310 "TECNORD srl" 309 "Krauss-Maffei Wegmann GmbH & Co. KG" 308 "Cyntrx" 307 "MAS Technologies" 306 "Sleipner Motor AB" 305 "NovAtel Inc" 304 "EmpirBus AB" 303 "CTS Corporation" 302 "Nissin Kogyo Co., LTD" 301 "Parker Hannifin (UK) Ltd FDE group" 300 "Systron Donner Automotive" 299 "Rauch Landmaschinen GmbH" 280 "Leica Geosystems Pty Ltd" 279 "Geometris LP" 278 "Takata Electronics" 277 "LHP Telematics" 276 "Aqua-Hot Heating Systems" 275 "Navico Egersund AS" 274 "LTW Technology Co., LTD" 273 "Active Research Limited" 272 "Gross Mechanical Laboratories, Inc" 327 "Sonceboz SA" 326 "Akron Brass Company" 325 "ASM Automation Sensorik Messtechnik GmbH" 324 "Snap-on Diagnostics" 323 "Mobileye Vision Technologies Ltd." 322 "MICHENKA s.r.o." 321 "Ultra Electronics, Electrics" 320 "Miedema Landbouwwerktuigenfabriek B.V." 319 "Cadec Global" 318 "SAT Plan" 317 "Navtronics Bvba" 316 "ITT Flow Control" 315 "Icom Incorporated" 314 "CSM GmbH" 313 "Ilmor Engineering, Inc" 312 "Lectronix, Inc." 271 "Cole Hersee" 270 "Tennant" 269 "Saft America Inc.,  Space & Defense Division" 268 "Accurate Technologies" 267 "Red Lion Controls, Inc" 266 "International Thermal Research Ltd" 265 "MTS Sensor Technologie GmbH" 264 "Autolync" 248 "Cooper Standard Automotive Active Systems Group" 247 "ePULSE" 246 "Class 1, Inc" 245 "Capstan Ag Systems, Inc." 244 "Techno-Matic" 243 "eRide, Inc." 242 "Kokusandenki Co. Ltd" 241 "Schneider Automation SAS " 240 "Vanair Mfg" 239 "May & Scofield Ltd" 238 "ZF Friedrichshafen AG" 237 "Agtron Enterprises Inc" 236 "Norac Systems International Inc" 235 "SailorMade Marine Telemetry - Tetra Technology Ltd." 234 "Mondial electronic GmbH" ;
VAL_ 2566847486 DrvlineRetarderOverheatIndicator 3 "Not available" 2 "Driveline Retarder Overheat Indicator is flashing" 1 "Driveline Retarder Overheat Indicator is on continuously" 0 "Driveline Retarder Overheat Indicator is off" ;
VAL_ 2631859966 SteerStraightAheadPosReset 3 "Not applicable" 2 "Reserved take no action" 1 "Reset" 0 "Take no action  Do not Reset" ;
VAL_ 2631859966 EngBuildHoursReset 2 "Reserved" 3 "Take no action" 1 "Reset" 0 "Do not reset" ;
VAL_ 2631859966 TripGroup2Proprietary 2 "Reserved" 3 "Not applicable" 1 "Reset" 0 "Take no action" ;
VAL_ 2631859966 TripGroup1 2 "Reserved" 3 "Not applicable" 1 "Reset" 0 "Take no action" ;
VAL_ 2566840830 RetarderLocation 15 "Not available" 14 "Other" 5 "Trailer Vehicle speed" 4 "Secondary Driveline Output Shaft rpm" 3 "Secondary Transmission Output Output Shaft rpm" 2 "Primary Transmission Input Engine rpm" 1 "Primary Engine Exhaust Brake Exhaust pressure" 0 "Primary Engine Compression Release Brake Engine rpm" ;
VAL_ 2566840830 RetarderType 15 "Not available" 14 "Other" 4 "Exhaust" 3 "Compression Release Engine retarder" 2 "Cooled Friction" 1 "Hydraulic" 0 "Electric/Magnetic" ;
VAL_ 2566844670 OprtrEngPTOGvrnrMmrySelectSwitch 3 "not available" 2 "error" 1 "PTO set speed memory 2 selected" 0 "PTO set speed memory 1 selected" ;
VAL_ 2566844670 EngRmtPTOGvrnrVrblSpedCtrlSwitch 3 "Not available" 2 "Error" 1 "On" 0 "Off" ;
VAL_ 2566844670 EngRmtPTOGvrnrPrprgrmmdSpdCtrlSw 3 "Not available" 2 "Error" 1 "On" 0 "Off" ;
VAL_ 2566844670 EngPTOGvrnrCast_DecelerateSwitch 3 "Not available" 2 "Error" 1 "On" 0 "Off" ;
VAL_ 2566844670 EngPTOGovernorSetSwitch 3 "Not available" 2 "Error" 1 "On" 0 "Off" ;
VAL_ 2566844670 EngPTOGovernorResumeSwitch 3 "Not available" 2 "Error" 1 "On" 0 "Off" ;
VAL_ 2566844670 EngPTOGovernorEnableSwitch 3 "Not available" 2 "Error" 1 "On" 0 "Off" ;
VAL_ 2566844670 EngPTOGovernorAccelerateSwitch 3 "Not available" 2 "Error" 1 "On" 0 "Off" ;
VAL_ 2566844670 RmtPTOGvrnrPrprgrmmdSpdCtrlSwtch 3 "Not Available" 2 "Error" 1 "On" 0 "Off" ;
VAL_ 2566844670 AuxInputIgnoreSwitch 3 "Not Available" 2 "Error" 1 "On" 0 "Off" ;
VAL_ 2566770174 RearWasherFunction 7 "Not available do not change" 4 "110 Reserved" 3 "High" 2 "Medium" 1 "Low" 0 "Off" ;
VAL_ 2566770174 FrontOperatorWasherSwitch 7 "Not available do not change" 4 "110 Reserved" 3 "High" 2 "Medium" 1 "Low" 0 "Off" ;
VAL_ 2566770174 FrontNonoperatorWasherSwitch 7 "Not available do not change" 4 "110 Reserved" 3 "High" 2 "Medium" 1 "Low" 0 "Off" ;
VAL_ 2566770174 RearWiperSwitch 7 "1110 Reserved" 6 "Mist position where external sensor controls wiper rate" 5 "Delayed 2 used for the second delay choice when the wiper switch position controls the delay" 4 "Delayed 1 used for the first delay choice when the wiper switch position controls the delay" 2 "Medium" 15 "Not available do not change" 3 "High" 1 "Low" 0 "Off" ;
VAL_ 2566770174 FrontOperatorWiperSwitch 7 "1110 Reserved" 6 "Mist position where external sensor controls wiper rate" 5 "Delayed 2 used for the second delay choice when the wiper switch position controls the delay" 4 "Delayed 1 used for the first delay choice when the wiper switch position controls the delay" 2 "Medium" 15 "Not available do not change" 3 "High" 1 "Low" 0 "Off" ;
VAL_ 2566770174 FrontNonoperatorWiperSwitch 15 "Not available do not change" 7 "1110 Reserved" 6 "Mist position where external sensor controls wiper rate" 5 "Delayed 2 used for the second delay choice when the wiper switch position controls the delay" 4 "Delayed 1 used for the first delay choice when the wiper switch position controls the delay" 3 "High" 2 "Medium" 1 "Low" 0 "Off" ;
VAL_ 2566769662 EngAltDroopAuxInputSelect 15 "Not available" 14 "Error condition" 1 "thru 1101  One of Alternate Droop Setting 1 through 13 in sequential order is selected" 0 "Normal Droop Setting is selected" ;
VAL_ 2566769662 EngAltDroopRemoteAccelSelect 15 "Not available" 14 "Error condition" 1 "thru 1101  One of Alternate Droop Setting 1 through 13 in sequential order is selected" 0 "Normal Droop Setting is selected" ;
VAL_ 2566769662 EngAltDroopAccel2Select 15 "Not available" 14 "Error condition" 1 "thru 1101  One of Alternate Droop Setting 1 through 13 in sequential order is selected" 0 "Normal Droop Setting is selected" ;
VAL_ 2566769662 EngAltDroopAccel1Select 15 "Not available" 14 "Error condition" 1 "thru 1101  One of Alternate Droop Setting 1 through 13 in sequential order is selected" 0 "Normal Droop Setting is selected" ;
VAL_ 2566769662 EngAltLowIdleSwitch 3 "Not available or Unused" 2 "Error" 1 "Alternate low idle point is selected" 0 "Default low idle point is selected" ;
VAL_ 2566769662 EngSynchronizationSwitch 3 "Not available or Unused" 2 "Error" 1 "Functionality is enabled on" 0 "Functionality is disabled off" ;
VAL_ 2566769662 EngAuxGovernorSwitch 2 "Error condition" 1 "Auxiliary Governor is enabled" 0 "Auxiliary Governor is disabled" 3 "Not available" ;
